VERSION ""

NS_ :

BS_:

BU_: HIB SaGE CBC DASM DIAGNOST EBCM ECM EPSB ESC ESL HALF HCP IC OCM ORC PTS RF_HUB SCCM

BO_ 1089 DG_RQ_GLOBAL_UDS: 8 DIAGNOST
 SG_ DG_RQ_GLOBAL_UDS : 7|64@0+ (1,0) [0|0] ""  SCCM,RF_HUB,PTS,ORC,OCM,IC,HCP,HALF,ESL,ESC,EPSB,ECM,EBCM,DASM,CBC

BO_ 501 DAS_A4: 8 DASM
 SG_ Sm_ICON_Dspl : 40|6@1+ (1,0) [0|0] ""  HIB,IC
 SG_ SetSpeed_MPH : 16|8@1+ (1,0) [0|250] "mph"  HIB,ORC,IC
 SG_ SetSpeed_KPH : 8|8@1+ (1,0) [0|250] "km/h"  HIB,IC,ECM
 SG_ RadarBlocked : 46|1@1+ (1,0) [0|0] ""  HIB,ORC,IC
 SG_ ObjIntrstDist : 56|8@1+ (1,0) [0|253] "m"  HIB,ORC
 SG_ NCConlyNA_DASMSts : 49|1@1+ (1,0) [0|0] ""  HIB,IC
 SG_ NCCNA_DASMSts : 53|1@1+ (1,0) [0|0] ""  HIB,IC
 SG_ HMI_Screens : 0|8@1+ (1,0) [0|254] "Text"  HIB,IC
 SG_ FCWonlyNA_DASMSts : 51|1@1+ (1,0) [0|0] ""  HIB,IC
 SG_ FCW_Error : 26|2@1+ (1,0) [0|0] ""  HIB,ORC,IC
 SG_ FCW_BrkOn : 29|1@1+ (1,0) [0|0] ""  HIB,ORC,CBC
 SG_ FCWBrakingOff : 47|1@1+ (1,0) [0|0] ""  HIB,IC
 SG_ CameraFailure : 55|1@1+ (1,0) [0|0] ""  HIB,IC
 SG_ CameraBlocked : 54|1@1+ (1,0) [0|0] ""  HIB,IC
 SG_ CIPV_Fused : 30|1@1+ (1,0) [0|0] ""  HIB,ORC
 SG_ ACConlyNA_DASMSts : 48|1@1+ (1,0) [0|0] ""  HIB,IC
 SG_ ACC_HMI_SCRN_REQ : 31|1@1+ (1,0) [0|0] ""  HIB,IC
 SG_ ACCOnOff : 36|3@1+ (1,0) [0|0] ""  HIB,ORC,IC
 SG_ ACCNA_DASMSts : 52|1@1+ (1,0) [0|0] ""  HIB,IC
 SG_ ACCFaulted : 50|1@1+ (1,0) [0|0] ""  HIB,ORC,IC

BO_ 1747 APPL_ECU_DASM: 8 DIAGNOST
 SG_ APPL_ECU_DASM : 7|64@0+ (1,0) [0|0] ""  DASM

BO_ 1754 APPL_ECU_EPS: 8 DIAGNOST
 SG_ APPL_ECU_EPS : 7|64@0+ (1,0) [0|0] ""  EPSB

BO_ 1764 APPL_ECU_HALF: 8 DIAGNOST
 SG_ APPL_ECU_HaLF : 7|64@0+ (1,0) [0|0] ""  HALF

BO_ 1762 APPL_ECU_PTS: 8 DIAGNOST
 SG_ APPL_ECU_PTS : 7|64@0+ (1,0) [0|0] ""  PTS

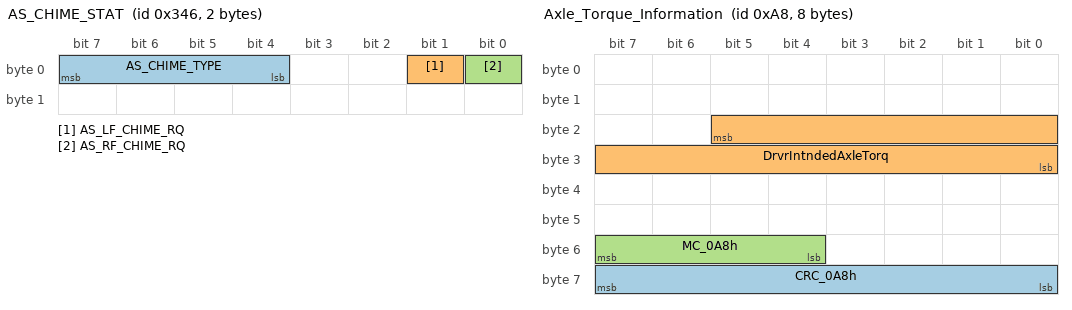
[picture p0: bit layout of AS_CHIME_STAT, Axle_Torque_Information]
BO_ 838 AS_CHIME_STAT: 2 DASM
 SG_ AS_CHIME_TYPE : 4|4@1+ (1,0) [0|0] ""  CBC,ORC
 SG_ AS_LF_CHIME_RQ : 1|1@1+ (1,0) [0|0] ""  CBC
 SG_ AS_RF_CHIME_RQ : 0|1@1+ (1,0) [0|0] ""  CBC

BO_ 168 Axle_Torque_Information: 8 ECM
 SG_ CRC_0A8h : 56|8@1+ (1,0) [0|0] ""  DASM,ESC
 SG_ DrvrIntndedAxleTorq : 21|14@0+ (1.5625,-4604.688) [-4604.688|20970.3125] "Nm"  DASM,ESC,ORC
 SG_ MC_0A8h : 52|4@1+ (1,0) [0|15] ""  DASM,ESC

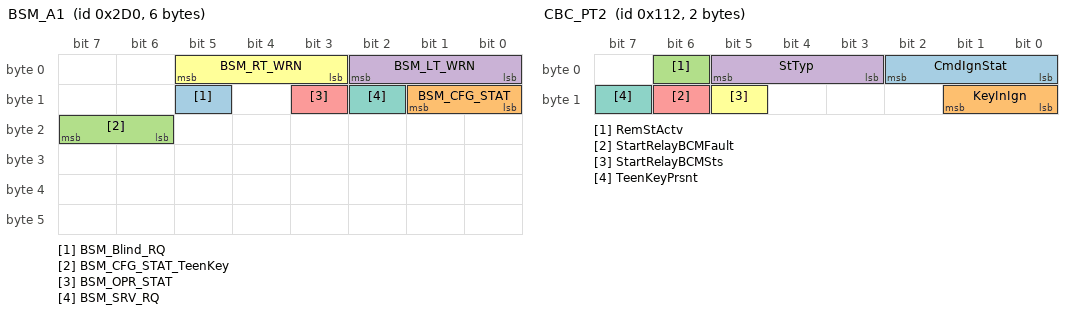
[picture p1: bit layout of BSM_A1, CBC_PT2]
BO_ 720 BSM_A1: 6 CBC
 SG_ BSM_Blind_RQ : 13|1@1+ (1,0) [0|0] ""  DASM,IC,ORC
 SG_ BSM_CFG_STAT : 8|2@1+ (1,0) [0|0] ""  DASM,IC,ORC
 SG_ BSM_CFG_STAT_TeenKey : 22|2@1+ (1,0) [0|0] ""  DASM
 SG_ BSM_LT_WRN : 0|3@1+ (1,0) [0|0] ""  DASM,ORC
 SG_ BSM_OPR_STAT : 11|1@1+ (1,0) [0|0] ""  DASM,IC
 SG_ BSM_RT_WRN : 3|3@1+ (1,0) [0|0] ""  DASM,ORC
 SG_ BSM_SRV_RQ : 10|1@1+ (1,0) [0|0] ""  DASM,IC,ORC

BO_ 820 CBC_PT1: 8 CBC
 SG_ AHB_ACT : 14|1@1+ (1,0) [0|0] ""  IC
 SG_ BRK_FLUID_LO : 62|1@1+ (1,0) [0|0] ""  ESC,IC
 SG_ DAY_LGT_MD : 40|1@1+ (1,0) [0|0] ""  IC,RF_HUB,SCCM
 SG_ DRV_AJAR : 17|1@1+ (1,0) [0|0] ""  DASM,ECM,ESC,HCP,IC,PTS,RF_HUB
 SG_ DR_LK_STAT : 5|2@1+ (1,0) [0|0] "" Vector__XXX
 SG_ FOB_SrchRq : 8|2@1+ (1,0) [0|0] ""  RF_HUB
 SG_ FT_FOG_RQ : 2|1@1+ (1,0) [0|0] ""  IC
 SG_ FT_WPR_NOT_PRK : 56|1@1+ (1,0) [0|0] ""  DASM,ECM,HALF
 SG_ HIBEAM_ON : 58|1@1+ (1,0) [0|0] ""  HALF,IC
 SG_ IGN_OFF_TIME_LNG : 27|12@0+ (1,0) [0|4080] "min"  DASM,ECM,ESC
 SG_ LOBEAM_ON : 57|1@1+ (1,0) [0|0] "" Vector__XXX
 SG_ L_R_AJAR : 19|1@1+ (1,0) [0|0] ""  IC,RF_HUB
 SG_ PANEL_INTS : 48|8@1+ (0.5,0) [0|100] "%"  IC,RF_HUB,SCCM
 SG_ PARK_LMP_ON : 16|1@1+ (1,0) [0|0] ""  IC
 SG_ PSG_AJAR : 18|1@1+ (1,0) [0|0] ""  ESC,IC,RF_HUB
 SG_ REV_GEAR : 4|1@1+ (1,0) [0|0] ""  EPSB,HALF,ORC
 SG_ R_FOG_RQ : 3|1@1+ (1,0) [0|0] ""  IC
 SG_ R_R_AJAR : 20|1@1+ (1,0) [0|0] ""  IC,RF_HUB
 SG_ SHIP_STAT : 28|2@1+ (1,0) [0|0] ""  DASM,HCP,IC,RF_HUB
 SG_ TLG_AJAR : 22|1@1+ (1,0) [0|0] ""  IC,PTS,RF_HUB
 SG_ TurnInd_LT_ON : 30|1@1+ (1,0) [0|0] ""  HALF,IC
 SG_ TurnInd_RT_ON : 31|1@1+ (1,0) [0|0] ""  HALF,IC
 SG_ WASH_FLUID_LO : 63|1@1+ (1,0) [0|0] ""  IC

BO_ 274 CBC_PT2: 2 CBC
 SG_ CmdIgnStat : 0|3@1+ (1,0) [0|0] ""  DASM,EBCM,ECM,EPSB,ESC,ESL,HALF,HCP,IC,OCM,ORC,PTS,RF_HUB,SCCM
 SG_ KeyInIgn : 8|2@1+ (1,0) [0|0] ""  ESL,HCP,IC,RF_HUB
 SG_ RemStActv : 6|1@1+ (1,0) [0|0] ""  ECM,HCP,IC,RF_HUB
 SG_ StTyp : 3|3@1+ (1,0) [0|0] ""  RF_HUB
 SG_ StartRelayBCMFault : 14|1@1+ (1,0) [0|0] ""  ECM
 SG_ StartRelayBCMSts : 13|1@1+ (1,0) [0|0] ""  ECM
 SG_ TeenKeyPrsnt : 15|1@1+ (1,0) [0|0] ""  DASM,ECM,IC,ORC,PTS

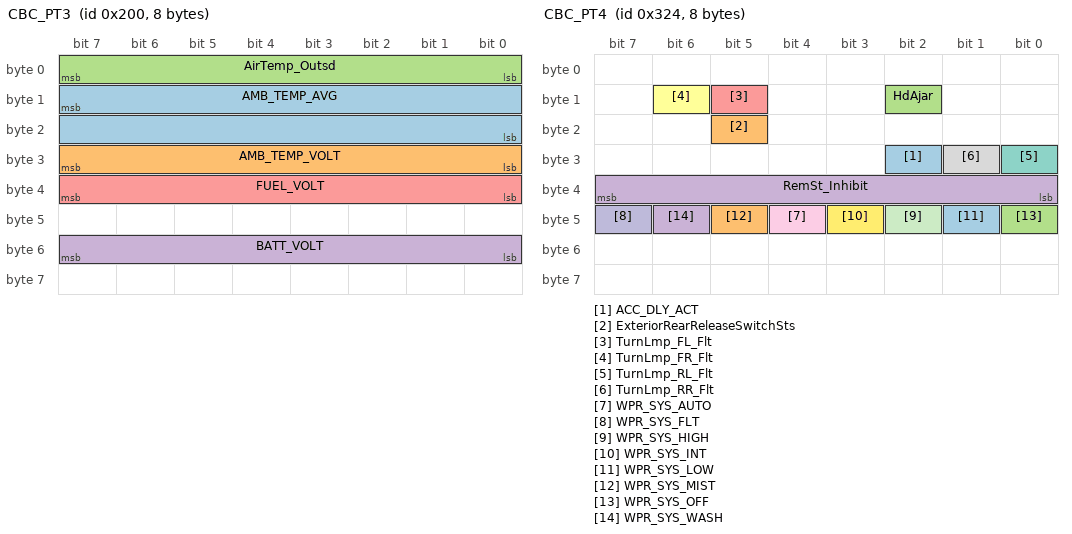
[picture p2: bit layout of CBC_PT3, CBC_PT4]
BO_ 512 CBC_PT3: 8 CBC
 SG_ AMB_TEMP_AVG : 15|16@0+ (0.01,-40) [-40|85] "°C"  DASM,ECM,EPSB,ESC,OCM,PTS,RF_HUB
 SG_ AMB_TEMP_VOLT : 24|8@1+ (0.019607843,0) [0|4.98] "Volts"  ECM,HCP
 SG_ AirTemp_Outsd : 0|8@1+ (0.5,-40) [-40|85] "°C"  DASM,ECM,EPSB,RF_HUB
 SG_ BATT_VOLT : 48|8@1+ (0.1,0) [5|18] "Volts"  DASM,EBCM,ECM,EPSB,ESC,ESL,HALF,HCP,IC,OCM,ORC,PTS,RF_HUB,SCCM
 SG_ FUEL_VOLT : 32|8@1+ (0.019607843,0) [0|4.98] "Volts"  ECM,IC

BO_ 804 CBC_PT4: 8 CBC
 SG_ ACC_DLY_ACT : 26|1@1+ (1,0) [0|0] ""  IC
 SG_ ExteriorRearReleaseSwitchSts : 21|1@1+ (1,0) [0|0] ""  RF_HUB
 SG_ HdAjar : 10|1@1+ (1,0) [0|0] ""  HCP,IC
 SG_ RemSt_Inhibit : 32|8@1+ (1,0) [0|0] ""  IC
 SG_ TurnLmp_FL_Flt : 13|1@1+ (1,0) [0|0] ""  HALF,IC
 SG_ TurnLmp_FR_Flt : 14|1@1+ (1,0) [0|0] ""  HALF,IC
 SG_ TurnLmp_RL_Flt : 24|1@1+ (1,0) [0|0] ""  HALF,IC
 SG_ TurnLmp_RR_Flt : 25|1@1+ (1,0) [0|0] ""  HALF,IC
 SG_ WPR_SYS_AUTO : 44|1@1+ (1,0) [0|0] ""  DASM,ESC,HALF
 SG_ WPR_SYS_FLT : 47|1@1+ (1,0) [0|0] ""  DASM,ESC,HALF
 SG_ WPR_SYS_HIGH : 42|1@1+ (1,0) [0|0] ""  DASM,ESC,HALF
 SG_ WPR_SYS_INT : 43|1@1+ (1,0) [0|0] ""  DASM,ESC,HALF
 SG_ WPR_SYS_LOW : 41|1@1+ (1,0) [0|0] ""  DASM,ESC,HALF
 SG_ WPR_SYS_MIST : 45|1@1+ (1,0) [0|0] ""  DASM,ESC,HALF
 SG_ WPR_SYS_OFF : 40|1@1+ (1,0) [0|0] ""  DASM,ESC,HALF
 SG_ WPR_SYS_WASH : 46|1@1+ (1,0) [0|0] ""  DASM,ESC,HALF

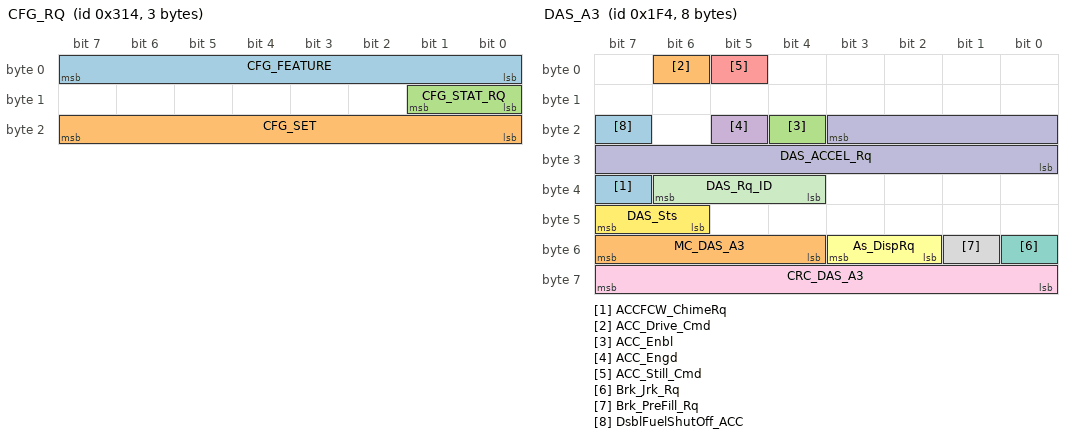
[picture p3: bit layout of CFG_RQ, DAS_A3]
BO_ 788 CFG_RQ: 3 CBC
 SG_ CFG_FEATURE : 0|8@1+ (1,0) [0|0] ""  DASM,ECM,ESC,HALF,IC,PTS,RF_HUB
 SG_ CFG_SET : 16|8@1+ (1,0) [0|255] ""  DASM,ECM,ESC,HALF,IC,PTS,RF_HUB
 SG_ CFG_STAT_RQ : 8|2@1+ (1,0) [0|0] ""  DASM,ECM,ESC,HALF,IC,PTS,RF_HUB

BO_ 500 DAS_A3: 8 DASM
 SG_ ACCFCW_ChimeRq : 39|1@1+ (1,0) [0|0] ""  HIB,IC
 SG_ ACC_Drive_Cmd : 6|1@1+ (1,0) [0|0] ""  HIB
 SG_ ACC_Enbl : 20|1@1+ (1,0) [0|0] ""  HIB,IC
 SG_ ACC_Engd : 21|1@1+ (1,0) [0|0] ""  HIB,IC
 SG_ ACC_Still_Cmd : 5|1@1+ (1,0) [0|0] ""  HIB,ORC
 SG_ As_DispRq : 50|2@1+ (1,0) [0|0] ""  HIB,HALF,IC,ORC
 SG_ Brk_Jrk_Rq : 48|1@1+ (1,0) [0|0] ""  HIB
 SG_ Brk_PreFill_Rq : 49|1@1+ (1,0) [0|0] ""  HIB
 SG_ CRC_DAS_A3 : 56|8@1+ (1,0) [0|0] ""  HIB
 SG_ DAS_ACCEL_Rq : 19|12@0+ (0.004885,-16) [-16|4] "m/s²"  HIB,ORC
 SG_ DAS_Rq_ID : 36|3@1+ (1,0) [0|0] ""  HIB
 SG_ DAS_Sts : 46|2@1+ (1,0) [0|0] ""  HIB
 SG_ DsblFuelShutOff_ACC : 23|1@1+ (1,0) [0|0] ""  HIB
 SG_ MC_DAS_A3 : 52|4@1+ (1,0) [0|15] ""  HIB,ECM

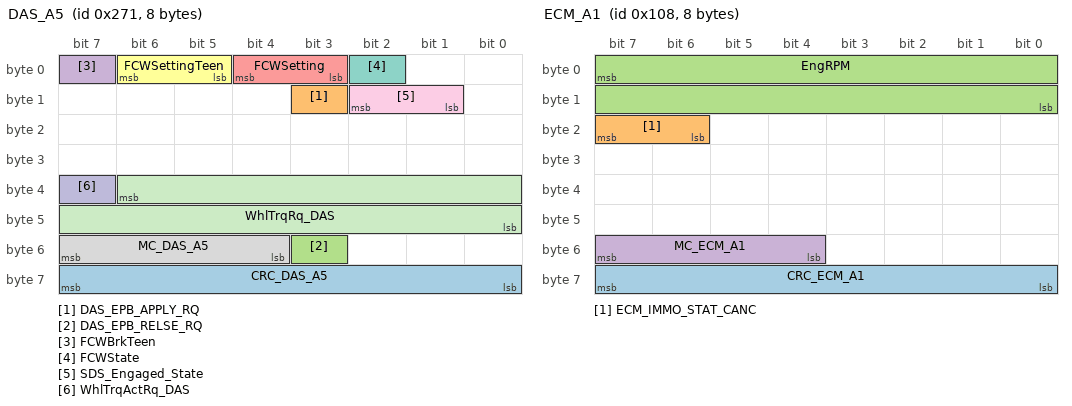
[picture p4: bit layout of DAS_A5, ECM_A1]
BO_ 625 DAS_A5: 8 DASM
 SG_ CRC_DAS_A5 : 56|8@1+ (1,0) [0|255] ""  HIB
 SG_ DAS_EPB_APPLY_RQ : 11|1@1+ (1,0) [0|0] ""  HIB
 SG_ DAS_EPB_RELSE_RQ : 51|1@1+ (1,0) [0|0] ""  HIB,HCP
 SG_ FCWBrkTeen : 7|1@1+ (1,0) [0|0] ""  HIB,CBC,ORC
 SG_ FCWSetting : 3|2@1+ (1,0) [0|0] ""  CBC,ORC
 SG_ FCWSettingTeen : 5|2@1+ (1,0) [0|0] ""  HIB,CBC,ORC
 SG_ FCWState : 2|1@1+ (1,0) [0|0] ""  HIB,CBC,IC,ORC
 SG_ MC_DAS_A5 : 52|4@1+ (1,0) [0|15] ""  HIB
 SG_ SDS_Engaged_State : 9|2@1+ (1,0) [0|0] ""  HIB,HCP
 SG_ WhlTrqActRq_DAS : 39|1@1+ (1,0) [0|0] ""  HIB
 SG_ WhlTrqRq_DAS : 38|15@0+ (1,-7767) [-7767|24999] "Nm"  HIB

BO_ 2015 DG_RQ_GLOBAL: 8 DIAGNOST
 SG_ DG_RQ_GLOBAL : 7|64@0+ (1,0) [0|0] ""  EBCM,ECM,ESC,HCP

BO_ 1875 D_RQ_DASM: 8 DIAGNOST
 SG_ D_RQ_DASM : 7|64@0+ (1,0) [0|0] ""  DASM

BO_ 1882 D_RQ_EPS: 8 DIAGNOST
 SG_ D_RQ_EPS : 7|64@0+ (1,0) [0|0] ""  EPSB

BO_ 1892 D_RQ_HaLF: 8 DIAGNOST
 SG_ D_RQ_HaLF : 7|64@0+ (1,0) [0|0] ""  HALF

BO_ 1890 D_RQ_PTS: 8 DIAGNOST
 SG_ D_RQ_PTS : 7|64@0+ (1,0) [0|0] ""  PTS

BO_ 1235 D_RS_DASM: 8 DASM
 SG_ D_RS_DASM : 7|64@0+ (1,0) [0|0] ""  DIAGNOST

BO_ 1242 D_RS_EPS: 8 EPSB
 SG_ D_RS_EPS : 7|64@0+ (1,0) [0|0] ""  DIAGNOST

BO_ 1252 D_RS_HaLF: 8 HALF
 SG_ D_RS_HaLF : 7|64@0+ (1,0) [0|0] ""  DIAGNOST

BO_ 1250 D_RS_PTS: 8 PTS
 SG_ D_RS_PTS : 7|64@0+ (1,0) [0|0] ""  DIAGNOST

BO_ 264 ECM_A1: 8 ECM
 SG_ CRC_ECM_A1 : 56|8@1+ (1,0) [0|0] ""  DASM,ESC,HALF
 SG_ ECM_IMMO_STAT_CANC : 22|2@1+ (1,0) [0|0] ""  CBC,HCP
 SG_ EngRPM : 7|16@0+ (1,0) [0|65534] "rpm"  CBC,DASM,EBCM,EPSB,ESC,HALF,IC,ORC,RF_HUB
 SG_ MC_ECM_A1 : 52|4@1+ (1,0) [0|15] ""  DASM,ESC,HALF

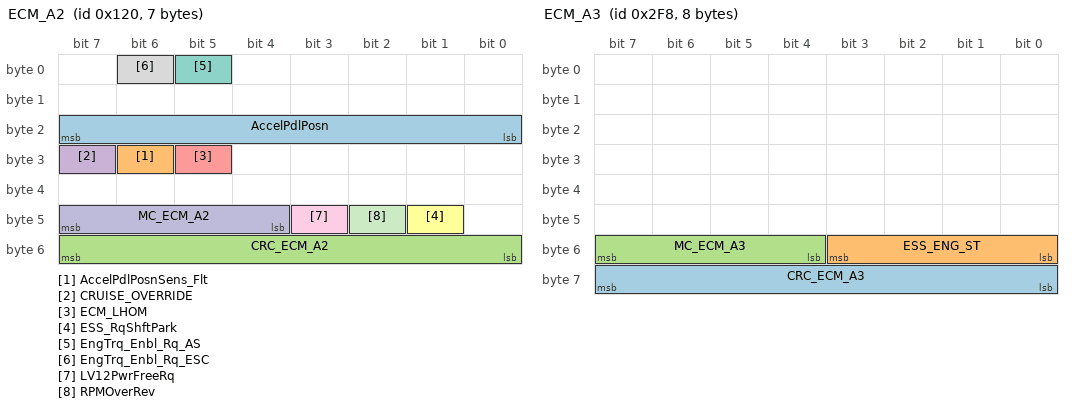
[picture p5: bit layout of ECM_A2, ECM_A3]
BO_ 288 ECM_A2: 7 ECM
 SG_ AccelPdlPosn : 16|8@1+ (0.4,0) [0|100] "%"  CBC,ESC,HALF
 SG_ AccelPdlPosnSens_Flt : 30|1@1+ (1,0) [0|0] ""  CBC,DASM,ESC,HALF
 SG_ CRC_ECM_A2 : 48|8@1+ (1,0) [0|0] ""  DASM,ESC,HALF
 SG_ CRUISE_OVERRIDE : 31|1@1+ (1,0) [0|0] ""  DASM,ESC,HCP,ORC
 SG_ ECM_LHOM : 29|1@1+ (1,0) [0|0] ""  DASM
 SG_ ESS_RqShftPark : 41|1@1+ (1,0) [0|0] ""  ORC
 SG_ EngTrq_Enbl_Rq_AS : 5|1@1+ (1,0) [0|0] ""  DASM,ESC
 SG_ EngTrq_Enbl_Rq_ESC : 6|1@1+ (1,0) [0|0] ""  DASM,ESC
 SG_ LV12PwrFreeRq : 43|1@1+ (1,0) [0|0] ""  DASM,ESC
 SG_ MC_ECM_A2 : 44|4@1+ (1,0) [0|15] ""  DASM,ESC,HALF
 SG_ RPMOverRev : 42|1@1+ (1,0) [0|0] "" Vector__XXX

BO_ 760 ECM_A3: 8 ECM
 SG_ CRC_ECM_A3 : 56|8@1+ (1,0) [0|0] ""  ESC,PTS
 SG_ ESS_ENG_ST : 48|4@1+ (1,0) [0|0] ""  CBC,EPSB,ESC,HALF,IC,ORC,PTS
 SG_ MC_ECM_A3 : 52|4@1+ (1,0) [0|15] ""  EPSB,ESC,PTS

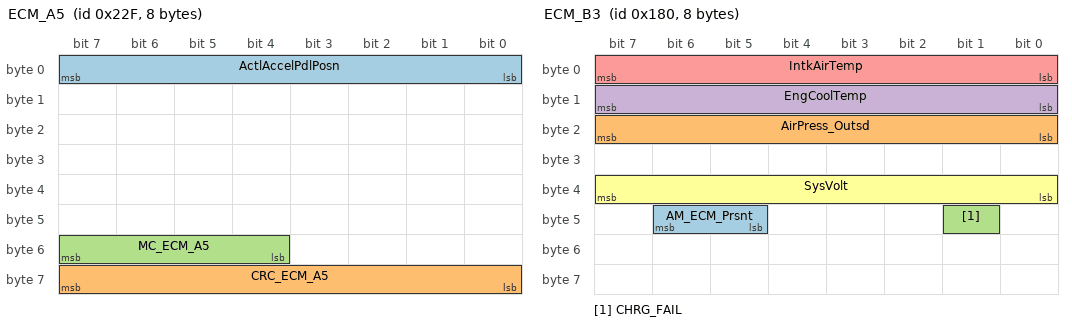
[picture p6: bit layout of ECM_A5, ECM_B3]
BO_ 559 ECM_A5: 8 ECM
 SG_ ActlAccelPdlPosn : 0|8@1+ (0.4,0) [0|100] "%"  DASM,ESC,HALF,ORC
 SG_ CRC_ECM_A5 : 56|8@1+ (1,0) [0|0] ""  DASM,ESC
 SG_ MC_ECM_A5 : 52|4@1+ (1,0) [0|15] ""  DASM,ESC

BO_ 384 ECM_B3: 8 ECM
 SG_ AM_ECM_Prsnt : 45|2@1+ (1,0) [0|0] ""  CBC
 SG_ AirPress_Outsd : 16|8@1+ (1,0) [0|254] "kPaA"  DASM,RF_HUB
 SG_ CHRG_FAIL : 41|1@1+ (1,0) [0|0] ""  IC
 SG_ EngCoolTemp : 8|8@1+ (1,-40) [-40|214] "°C"  CBC,ESC,IC
 SG_ IntkAirTemp : 0|8@1+ (1,-40) [-40|214] "°C"  ECM
 SG_ SysVolt : 32|8@1+ (0.0618,0) [0|15.6972] "Volts"  HCP

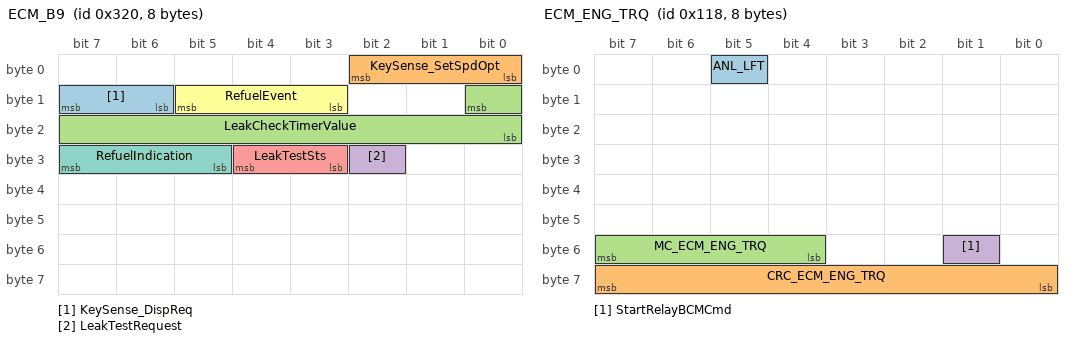
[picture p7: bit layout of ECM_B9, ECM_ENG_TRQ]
BO_ 800 ECM_B9: 8 ECM
 SG_ KeySense_DispReq : 14|2@1+ (1,0) [0|0] ""  IC
 SG_ KeySense_SetSpdOpt : 0|3@1+ (1,0) [0|0] ""  CBC,DASM,IC,ORC
 SG_ LeakCheckTimerValue : 8|9@0+ (1,0) [0|510] "min"  CBC
 SG_ LeakTestRequest : 26|1@1+ (1,0) [0|0] ""  CBC
 SG_ LeakTestSts : 27|2@1+ (1,0) [0|0] ""  CBC
 SG_ RefuelEvent : 11|3@1+ (1,0) [0|0] ""  CBC
 SG_ RefuelIndication : 29|3@1+ (1,0) [0|0] ""  IC

BO_ 280 ECM_ENG_TRQ: 8 ECM
 SG_ ANL_LFT : 5|1@1+ (1,0) [0|0] ""  CBC
 SG_ CRC_ECM_ENG_TRQ : 56|8@1+ (1,0) [0|0] ""  DASM,ESC
 SG_ MC_ECM_ENG_TRQ : 52|4@1+ (1,0) [0|15] ""  ESC
 SG_ StartRelayBCMCmd : 49|1@1+ (1,0) [0|0] ""  CBC

BO_ 1427 ECU_APPL_DASM: 8 DASM
 SG_ ECU_APPL_DASM : 7|64@0+ (1,0) [0|0] ""  DIAGNOST

BO_ 1434 ECU_APPL_EPS: 8 EPSB
 SG_ ECU_APPL_EPS : 7|64@0+ (1,0) [0|0] ""  DIAGNOST

BO_ 1444 ECU_APPL_HaLF: 8 HALF
 SG_ ECU_APPL_HaLF : 7|64@0+ (1,0) [0|0] ""  DIAGNOST

BO_ 1442 ECU_APPL_PTS: 8 PTS
 SG_ ECU_APPL_PTS : 7|64@0+ (1,0) [0|0] ""  DIAGNOST

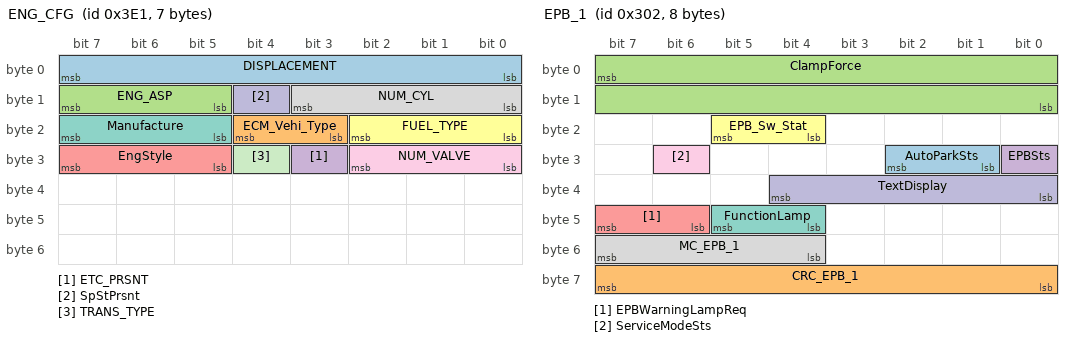
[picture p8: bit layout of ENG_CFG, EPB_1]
BO_ 993 ENG_CFG: 7 ECM
 SG_ DISPLACEMENT : 0|8@1+ (0.1,0) [0|25] "liters"  ESC,HALF,ORC
 SG_ ECM_Vehi_Type : 19|2@1+ (1,0) [0|0] "" Vector__XXX
 SG_ ENG_ASP : 13|3@1+ (1,0) [0|0] ""  ESC
 SG_ ETC_PRSNT : 27|1@1+ (1,0) [0|0] "" Vector__XXX
 SG_ EngStyle : 29|3@1+ (1,0) [0|0] ""  CBC,ESC
 SG_ FUEL_TYPE : 16|3@1+ (1,0) [0|0] ""  CBC,ESC,IC,ORC
 SG_ Manufacture : 21|3@1+ (1,0) [0|0] "" Vector__XXX
 SG_ NUM_CYL : 8|4@1+ (1,0) [0|14] "cylinders"  ESC,HALF,IC
 SG_ NUM_VALVE : 24|3@1+ (1,0) [0|6] "valve-per-cylinder" Vector__XXX
 SG_ SpStPrsnt : 12|1@1+ (1,0) [0|0] ""  CBC,EPSB,ESC,HALF,IC,PTS
 SG_ TRANS_TYPE : 28|1@1+ (1,0) [0|0] "" Vector__XXX

BO_ 770 EPB_1: 8 ESC
 SG_ AutoParkSts : 25|2@1+ (1,0) [0|0] ""  CBC
 SG_ CRC_EPB_1 : 56|8@1+ (1,0) [0|0] ""  DASM,ECM,IC
 SG_ ClampForce : 7|16@0+ (1,0) [0|65535] "N"  ORC
 SG_ EPBSts : 24|1@1+ (1,0) [0|0] ""  DASM,ECM,HCP
 SG_ EPBWarningLampReq : 46|2@1+ (1,0) [0|0] ""  IC,ORC
 SG_ EPB_Sw_Stat : 20|2@1+ (1,0) [0|0] ""  ORC
 SG_ FunctionLamp : 44|2@1+ (1,0) [0|0] ""  IC
 SG_ MC_EPB_1 : 52|4@1+ (1,0) [0|15] ""  DASM,ECM,IC
 SG_ ServiceModeSts : 30|1@1+ (1,0) [0|0] ""  CBC
 SG_ TextDisplay : 32|5@1+ (1,0) [0|0] ""  CBC,IC

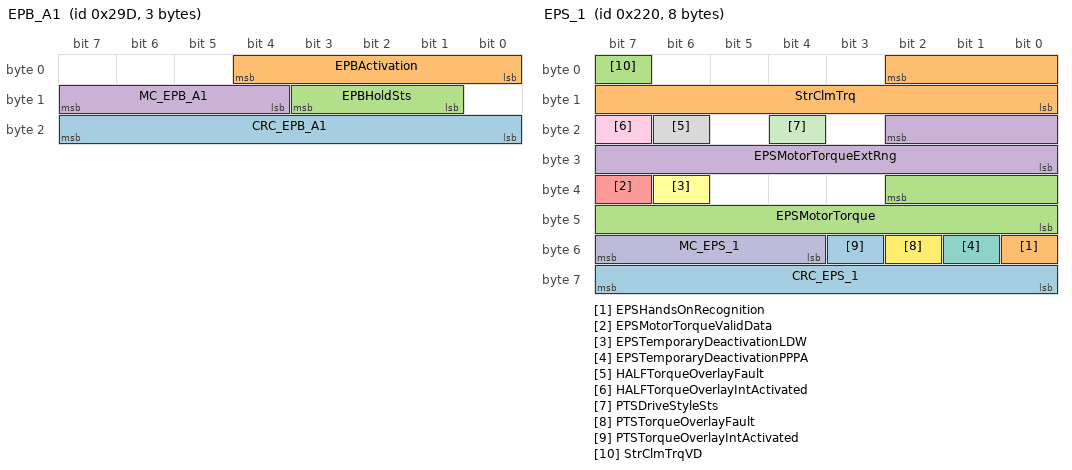
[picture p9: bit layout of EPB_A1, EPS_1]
BO_ 669 EPB_A1: 3 ESC
 SG_ CRC_EPB_A1 : 16|8@1+ (1,0) [0|0] ""  DASM,ECM,HCP,PTS
 SG_ EPBActivation : 0|5@1+ (1,0) [0|0] "" Vector__XXX
 SG_ EPBHoldSts : 9|3@1+ (1,0) [0|0] ""  CBC,DASM,ECM,HCP,ORC,PTS
 SG_ MC_EPB_A1 : 12|4@1+ (1,0) [0|15] ""  DASM,ECM,HCP,PTS

BO_ 544 EPS_1: 8 EPSB
 SG_ CRC_EPS_1 : 56|8@1+ (1,0) [0|0] ""  ECM,ESC,HALF,PTS
 SG_ EPSHandsOnRecognition : 48|1@1+ (1,0) [0|0] ""  PTS
 SG_ EPSMotorTorque : 34|11@0+ (0.001953125,-2) [-2|1.998047] "Nm"  HALF,ORC
 SG_ EPSMotorTorqueExtRng : 18|11@0+ (0.00488281,-5) [-5|4.99022926] "Nm" Vector__XXX
 SG_ EPSMotorTorqueValidData : 39|1@1+ (1,0) [0|0] ""  HALF
 SG_ EPSTemporaryDeactivationLDW : 38|1@1+ (1,0) [0|0] ""  HALF
 SG_ EPSTemporaryDeactivationPPPA : 49|1@1+ (1,0) [0|0] ""  PTS
 SG_ HALFTorqueOverlayFault : 22|1@1+ (1,0) [0|0] ""  HALF
 SG_ HALFTorqueOverlayIntActivated : 23|1@1+ (1,0) [0|0] ""  HALF,ORC
 SG_ MC_EPS_1 : 52|4@1+ (1,0) [0|15] ""  ECM,ESC,HALF,PTS
 SG_ PTSDriveStyleSts : 20|1@1+ (1,0) [0|0] ""  PTS
 SG_ PTSTorqueOverlayFault : 50|1@1+ (1,0) [0|0] ""  PTS
 SG_ PTSTorqueOverlayIntActivated : 51|1@1+ (1,0) [0|0] ""  PTS
 SG_ StrClmTrq : 2|11@0+ (0.0078125,-8) [-8|7.98] "Nm"  ECM,HALF,ORC,PTS
 SG_ StrClmTrqVD : 7|1@1+ (1,0) [0|0] ""  ECM,HALF,PTS

CM_ "Excel Convert to DBC - Written by Vector CANtech, Inc. 2016";
CM_ SG_ 1089 DG_RQ_GLOBAL_UDS "Diagnostic-Request";
CM_ SG_ 501 Sm_ICON_Dspl "Small graphic display";
CM_ SG_ 501 SetSpeed_MPH "Desired set speed in miles per hour";
CM_ SG_ 501 SetSpeed_KPH "Desired set speed in kilometers per hour";
CM_ SG_ 501 RadarBlocked "ACC FCW not available: clean radar snsr; True = [1]";
CM_ SG_ 501 ObjIntrstDist "Object of interest distance";
CM_ SG_ 501 NCConlyNA_DASMSts "NCC only not available: vehicle system error; True = [1]";
CM_ SG_ 501 NCCNA_DASMSts "NCC/FCW not avail: vehicle system error; True = [1]";
CM_ SG_ 501 HMI_Screens "HMI screens";
CM_ SG_ 501 FCWonlyNA_DASMSts "FCW only not available: vehicle system error; True = [1]";
CM_ SG_ 501 FCW_Error "Forward collision warning error";
CM_ SG_ 501 FCW_BrkOn "FCW braking is on; true = [1]";
CM_ SG_ 501 FCWBrakingOff "FCW autobraking disabled; True = [1]";
CM_ SG_ 501 CameraFailure "ACC/FCW limited functionality: camera failure; True = [1]";
CM_ SG_ 501 CameraBlocked "ACC FCW limited functionality: camera blocked; True = [1]";
CM_ SG_ 501 CIPV_Fused "Closest in-path vehicle is fused; True = [1]";
CM_ SG_ 501 ACConlyNA_DASMSts "ACC only not available: vehicle system error; True = [1]";
CM_ SG_ 501 ACC_HMI_SCRN_REQ "ACC HMI Screen request. Display HMI screen when [1]";
CM_ SG_ 501 ACCOnOff "ACC on off status";
CM_ SG_ 501 ACCNA_DASMSts "ACC/FCW not avail: vehicle system error; True = [1]";
CM_ SG_ 501 ACCFaulted "ACC faulted; True = [1]";
CM_ SG_ 1747 APPL_ECU_DASM "External Application to ECU";
CM_ SG_ 1754 APPL_ECU_EPS "External Application to ECU";
CM_ SG_ 1764 APPL_ECU_HaLF "External Application to ECU";
CM_ SG_ 1762 APPL_ECU_PTS "External Application to ECU";
CM_ SG_ 838 AS_CHIME_TYPE "AS chime type";
CM_ SG_ 838 AS_LF_CHIME_RQ "AS left front chime on request; True = [1]";
CM_ SG_ 838 AS_RF_CHIME_RQ "AS right front chime on request; True = [1]";
CM_ SG_ 168 CRC_0A8h "CRC-Checksum Byte 1 - 7 according to SAE J1850";
CM_ SG_ 168 DrvrIntndedAxleTorq "Driver Intended Axle Torque";
CM_ SG_ 168 MC_0A8h "Message counter   0A8h";
CM_ SG_ 720 BSM_Blind_RQ "Sensor blinded request from BSM; 1= sensor blocked request";
CM_ SG_ 720 BSM_CFG_STAT "BSM configuration status";
CM_ SG_ 720 BSM_CFG_STAT_TeenKey "BSM configuration status for teen key";
CM_ SG_ 720 BSM_LT_WRN "Blind spot detection left side warning";
CM_ SG_ 720 BSM_OPR_STAT "BSM operation status; 1= operational failure";
CM_ SG_ 720 BSM_RT_WRN "Blind spot detection Right side warning";
CM_ SG_ 720 BSM_SRV_RQ "BSM service warning request; 1= service request";
CM_ SG_ 820 AHB_ACT "Automatic high beam active";
CM_ SG_ 820 BRK_FLUID_LO "Low brake fluid warning; low = [1]";
CM_ SG_ 820 DAY_LGT_MD "Day light brightness mode; Night=[0], Day=[1]";
CM_ SG_ 820 DRV_AJAR "Driver door ajar (1 = Door Ajar)";
CM_ SG_ 820 DR_LK_STAT "Door lock status";
CM_ SG_ 820 FOB_SrchRq "FOB search request";
CM_ SG_ 820 FT_FOG_RQ "Front fog request; off=[0], on=[1]";
CM_ SG_ 820 FT_WPR_NOT_PRK "Front wiper outside park position";
CM_ SG_ 820 HIBEAM_ON "High beam is on; off=[0], on=[1]";
CM_ SG_ 820 IGN_OFF_TIME_LNG "Time since last ignition on (long)";
CM_ SG_ 820 LOBEAM_ON "Low beam is on; off=[0], on=[1]";
CM_ SG_ 820 L_R_AJAR "Left rear door ajar";
CM_ SG_ 820 PANEL_INTS "Panel-/display intensity";
CM_ SG_ 820 PARK_LMP_ON "Parklamps are on; off=[0], on=[1]";
CM_ SG_ 820 PSG_AJAR "Passenger door ajar";
CM_ SG_ 820 REV_GEAR "Reverse Gear (manual trans)";
CM_ SG_ 820 R_FOG_RQ "Rear fog request; [0] = off, [1] = on";
CM_ SG_ 820 R_R_AJAR "Right rear door ajar";
CM_ SG_ 820 SHIP_STAT "Shipping status";
CM_ SG_ 820 TLG_AJAR "Trunk/Liftgate ajar";
CM_ SG_ 820 TurnInd_LT_ON "Turn indication left is on";
CM_ SG_ 820 TurnInd_RT_ON "Turn indication right is on";
CM_ SG_ 820 WASH_FLUID_LO "Low washer fluid warning (1=Fluid is low)";
CM_ SG_ 274 CmdIgnStat "Commanded ignition switch status";
CM_ SG_ 274 KeyInIgn "Key in ignition status";
CM_ SG_ 274 RemStActv "Ignition run active for remote start (0=not active, 1=active)";
CM_ SG_ 274 StTyp "Type of start being requested";
CM_ SG_ 274 StartRelayBCMFault "CBC starter relay fault detected";
CM_ SG_ 274 StartRelayBCMSts "CBC starter relay status; [1] = ON";
CM_ SG_ 274 TeenKeyPrsnt "Teen key present; Present = [1]";
CM_ SG_ 512 AMB_TEMP_AVG "Averaged ambient temperature";
CM_ SG_ 512 AMB_TEMP_VOLT "Ambient Temp Sensor A/D Voltage";
CM_ SG_ 512 AirTemp_Outsd "Outside air temperature";
CM_ SG_ 512 BATT_VOLT "System voltage";
CM_ SG_ 512 FUEL_VOLT "Fuel level A/D Voltage (Single tank OR Primary on Saddle/Dual Tank)";
CM_ SG_ 804 ACC_DLY_ACT "Accessory Delay Active";
CM_ SG_ 804 ExteriorRearReleaseSwitchSts "Exterior rear release switch status";
CM_ SG_ 804 HdAjar "Hood latch ajar, left or single (1=ajar)";
CM_ SG_ 804 RemSt_Inhibit "Remote start inhibit";
CM_ SG_ 804 TurnLmp_FL_Flt "Turn indication lamp front left fault";
CM_ SG_ 804 TurnLmp_FR_Flt "Turn indication lamp front right fault";
CM_ SG_ 804 TurnLmp_RL_Flt "Turn indication lamp rear left fault";
CM_ SG_ 804 TurnLmp_RR_Flt "Turn indication lamp rear right fault";
CM_ SG_ 804 WPR_SYS_AUTO "Wiper system auto; [1] = Auto wipers equipped";
CM_ SG_ 804 WPR_SYS_FLT "Wiper system fault present; [1] = fault present";
CM_ SG_ 804 WPR_SYS_HIGH "Wiper system high; [1] = switch is HIGH";
CM_ SG_ 804 WPR_SYS_INT "Wiper system intermittent; [1] = switch is INT";
CM_ SG_ 804 WPR_SYS_LOW "Wiper system low; [1] = switch is LOW";
CM_ SG_ 804 WPR_SYS_MIST "Wiper system mist; [1] = mist request";
CM_ SG_ 804 WPR_SYS_OFF "Wiper system off; [1] = switch is OFF";
CM_ SG_ 804 WPR_SYS_WASH "Wiper system wash; [1] = wash request";
CM_ SG_ 788 CFG_FEATURE "Configurable feature";
CM_ SG_ 788 CFG_SET "Specific setting or value (see reference)";
CM_ SG_ 788 CFG_STAT_RQ "Configurable feature status request";
CM_ SG_ 500 ACCFCW_ChimeRq "ACC FCW chime request active; Active = [1]";
CM_ SG_ 500 ACC_Drive_Cmd "ACC drive off commanded; True = [1]";
CM_ SG_ 500 ACC_Enbl "ACC cruise control enabled; True = [1]";
CM_ SG_ 500 ACC_Engd "ACC engaged; True = [1]";
CM_ SG_ 500 ACC_Still_Cmd "ACC stop commanded; True = [1]";
CM_ SG_ 500 As_DispRq "Assistance system display request (priority)";
CM_ SG_ 500 Brk_Jrk_Rq "Brake jerk request; True = [1]";
CM_ SG_ 500 Brk_PreFill_Rq "Brakes pre-fill request; True = [1]";
CM_ SG_ 500 CRC_DAS_A3 "CRC-checksum byte 1 to 7 according to SAE J1850";
CM_ SG_ 500 DAS_ACCEL_Rq "DASM acceleration request";
CM_ SG_ 500 DAS_Rq_ID "DAS request ID";
CM_ SG_ 500 DAS_Sts "DASM fault status";
CM_ SG_ 500 DsblFuelShutOff_ACC "Disable fuel shutoff; True = [1]";
CM_ SG_ 500 MC_DAS_A3 "Message counter";
CM_ SG_ 625 CRC_DAS_A5 "CRC-checksum byte 1 to 7 according to SAE J1850";
CM_ SG_ 625 DAS_EPB_APPLY_RQ "DAS request to apply EPB";
CM_ SG_ 625 DAS_EPB_RELSE_RQ "DAS request to apply EPB";
CM_ SG_ 625 FCWBrkTeen "FCW braking is on for teen key; true = [1]";
CM_ SG_ 625 FCWSetting "Forward collision warning sensitivity setting";
CM_ SG_ 625 FCWSettingTeen "Forward collision warning sensitivity setting teen key";
CM_ SG_ 625 FCWState "FCW system operating state; On = [1]";
CM_ SG_ 625 MC_DAS_A5 "Message counter";
CM_ SG_ 625 SDS_Engaged_State "SDS Engaged Status";
CM_ SG_ 625 WhlTrqActRq_DAS "Wheel torque request active; True = [1]";
CM_ SG_ 625 WhlTrqRq_DAS "Requested wheel torque";
CM_ SG_ 2015 DG_RQ_GLOBAL "Diagnostic-Request";
CM_ SG_ 1875 D_RQ_DASM "Diagnostic-Request";
CM_ SG_ 1882 D_RQ_EPS "Diagnostic-Request";
CM_ SG_ 1892 D_RQ_HaLF "Diagnostic-Request";
CM_ SG_ 1890 D_RQ_PTS "Diagnostic-Request";
CM_ SG_ 1235 D_RS_DASM "Diagnostic-Response";
CM_ SG_ 1242 D_RS_EPS "Diagnostic-Response";
CM_ SG_ 1252 D_RS_HaLF "Diagnostic-Response";
CM_ SG_ 1250 D_RS_PTS "Diagnostic-Response";
CM_ SG_ 264 CRC_ECM_A1 "CRC-checksum byte 1 to 7 according to SAE J1850";
CM_ SG_ 264 ECM_IMMO_STAT_CANC "ECM immobilizer status";
CM_ SG_ 264 EngRPM "Engine revolutions per minute";
CM_ SG_ 264 MC_ECM_A1 "Message counter";
CM_ SG_ 288 AccelPdlPosn "Throttle Pedal Position (Calculated)";
CM_ SG_ 288 AccelPdlPosnSens_Flt "Accelerator pedal position sensor fault";
CM_ SG_ 288 CRC_ECM_A2 "CRC-checksum byte 1 to 6 according to SAE J1850";
CM_ SG_ 288 CRUISE_OVERRIDE "Driver is over-riding cruise set speed";
CM_ SG_ 288 ECM_LHOM "Engine in limp home mode";
CM_ SG_ 288 ESS_RqShftPark "ESS Request shift to Park.  1 = True, 0 = False";
CM_ SG_ 288 EngTrq_Enbl_Rq_AS "Allow LCM torque requests";
CM_ SG_ 288 EngTrq_Enbl_Rq_ESC "Allow ESC torque request";
CM_ SG_ 288 LV12PwrFreeRq "Level 1 or 2 power free request - engine controller has depowered the throttle body";
CM_ SG_ 288 MC_ECM_A2 "Message counter";
CM_ SG_ 288 RPMOverRev "RPM Overrev condition has occurred";
CM_ SG_ 760 CRC_ECM_A3 "CRC-checksum byte 1 to 7 according to SAE J1850";
CM_ SG_ 760 ESS_ENG_ST "ESS Engine State";
CM_ SG_ 760 MC_ECM_A3 "Message counter";
CM_ SG_ 559 ActlAccelPdlPosn "Throttle Pedal Position (actual)";
CM_ SG_ 559 CRC_ECM_A5 "CRC-checksum byte 1 to 7 according to SAE J1850";
CM_ SG_ 559 MC_ECM_A5 "Message counter";
CM_ SG_ 384 AM_ECM_Prsnt "Aftermarket ECM present";
CM_ SG_ 384 AirPress_Outsd "Ambient air pressure (barometric pressure)";
CM_ SG_ 384 CHRG_FAIL "Charging system Failure (battery indicator request)";
CM_ SG_ 384 EngCoolTemp "Engine coolant temperature";
CM_ SG_ 384 IntkAirTemp "Engine Intake Air Temperature";
CM_ SG_ 384 SysVolt "Engine system voltage";
CM_ SG_ 800 KeySense_DispReq "Key sense cluster EVIC request";
CM_ SG_ 800 KeySense_SetSpdOpt "Key sense max speed option for ECM speed limiting";
CM_ SG_ 800 LeakCheckTimerValue "Requested leak test timer value";
CM_ SG_ 800 LeakTestRequest "Leak test is requested after powerdown; No request = [0], Leak test requested = [1]";
CM_ SG_ 800 LeakTestSts "Status of leak test";
CM_ SG_ 800 RefuelEvent "Status of refuel event";
CM_ SG_ 800 RefuelIndication "Indication to the driver about the status of the refuel system";
CM_ SG_ 280 ANL_LFT "Starter motor running (Cranking)";
CM_ SG_ 280 CRC_ECM_ENG_TRQ "CRC-checksum byte 1 to 7 according to SAE J1850";
CM_ SG_ 280 MC_ECM_ENG_TRQ "Message counter";
CM_ SG_ 280 StartRelayBCMCmd "Engine restart request for StopStart function";
CM_ SG_ 1427 ECU_APPL_DASM "ECU to External Application";
CM_ SG_ 1434 ECU_APPL_EPS "ECU to External Application";
CM_ SG_ 1444 ECU_APPL_HaLF "ECU to External Application";
CM_ SG_ 1442 ECU_APPL_PTS "ECU to External Application";
CM_ SG_ 993 DISPLACEMENT "Engine displacement";
CM_ SG_ 993 ECM_Vehi_Type "Engine vehicle type";
CM_ SG_ 993 ENG_ASP "Engine aspiration method";
CM_ SG_ 993 ETC_PRSNT "Electronic throttle control";
CM_ SG_ 993 EngStyle "Engine output version";
CM_ SG_ 993 FUEL_TYPE "Fuel type";
CM_ SG_ 993 Manufacture "Engine manufacture";
CM_ SG_ 993 NUM_CYL "Number of engine cylinders";
CM_ SG_ 993 NUM_VALVE "Number of valves per cylinder";
CM_ SG_ 993 SpStPrsnt "Stop start feature present";
CM_ SG_ 993 TRANS_TYPE "Transmission type; [0] = manual, [1] = automatic";
CM_ SG_ 770 AutoParkSts "EPB auto park brake function available status";
CM_ SG_ 770 CRC_EPB_1 "CRC-checksum byte 1 to 7 according to SAE J1850";
CM_ SG_ 770 ClampForce "EPB clamp force";
CM_ SG_ 770 EPBSts "EPB status; Enable = [1]";
CM_ SG_ 770 EPBWarningLampReq "EPB warning (fault) lamp active request";
CM_ SG_ 770 EPB_Sw_Stat "EPB switch state";
CM_ SG_ 770 FunctionLamp "EPB function lamp active request";
CM_ SG_ 770 MC_EPB_1 "Message counter";
CM_ SG_ 770 ServiceModeSts "EPB service mode; Service mode = [1]";
CM_ SG_ 770 TextDisplay "Text message display request";
CM_ SG_ 669 CRC_EPB_A1 "CRC-checksum byte 1 to 2 according to SAE J1850";
CM_ SG_ 669 EPBActivation "EPB activation reason";
CM_ SG_ 669 EPBHoldSts "EPB hold status";
CM_ SG_ 669 MC_EPB_A1 "Message counter";
CM_ SG_ 544 CRC_EPS_1 "CRC-checksum byte 1 to 7 according to SAE J1850";
CM_ SG_ 544 EPSHandsOnRecognition "Driver interference during the semiautomatic parking maneuver; True = [1]";
CM_ SG_ 544 EPSMotorTorque "EPS motor torque";
CM_ SG_ 544 EPSMotorTorqueExtRng "EPS motor torque extended range (+/- 5Nm)";
CM_ SG_ 544 EPSMotorTorqueValidData "Motor torque: valid data [1]";
CM_ SG_ 544 EPSTemporaryDeactivationLDW "Temporary deactivation of the EPS LDW torque overlay function";
CM_ SG_ 544 EPSTemporaryDeactivationPPPA "Temporary deactivation of the EPS PPPA torque overlay function; True = [1]";
CM_ SG_ 544 HALFTorqueOverlayFault "Fault of the HALF torque overlay interface";
CM_ SG_ 544 HALFTorqueOverlayIntActivated "Torque overlay interface has been successfully activated; True = [1]";
CM_ SG_ 544 MC_EPS_1 "Message counter";
CM_ SG_ 544 PTSDriveStyleSts "PTS_TOC Actived = [1]";
CM_ SG_ 544 PTSTorqueOverlayFault "Fault of the PTS torque overlay interface; True = [1]";
CM_ SG_ 544 PTSTorqueOverlayIntActivated "Torque overlay interface has been successfully activated; True = [1]";
CM_ SG_ 544 StrClmTrq "Steering column torque; counterclockwise positive [Nm]";
CM_ SG_ 544 StrClmTrqVD "Steering column torque: valid data [1]";
BA_DEF_ BO_  "App-Botschaft" ENUM  "nein","ja";
BA_DEF_ BO_  "CanMsgMinLen" INT 0 8;
BA_DEF_ BO_  "DiagRequest" ENUM  "nein","ja";
BA_DEF_ BO_  "DiagResponse" ENUM  "nein","ja";
BA_DEF_ BO_  "DiagState" ENUM  "nein","ja";
BA_DEF_ BO_  "GenMsgCycleTime" INT 0 65535;
BA_DEF_ BO_  "GenMsgCycleTimeActive" INT 0 65535;
BA_DEF_ BO_  "GenMsgDelayTime" INT 0 65535;
BA_DEF_ BO_  "GenMsgNrOfRepetitions" INT 0 65535;
BA_DEF_ BO_  "GenMsgSendType" ENUM  "cyclicX","spontanX","cyclicIfActiveX","spontanWithDelay","cyclicAndSpontanX","cyclicAndSpontanWithDelay","spontanWithRepitition","cyclicIfActiveAndSpontanWD","cyclicIfActiveFast","cyclicWithRepeatOnDemand","none";
BA_DEF_ BO_  "GenMsgStartDelayTime" INT 0 65535;
BA_DEF_ BO_  "GenMsgStartValue" STRING ;
BA_DEF_ BO_  "NWM-Botschaft" ENUM  "nein","ja";
BA_DEF_ BO_  "TpTxIndex" INT 0 99;
BA_DEF_  "Baudrate" INT 0 1000000;
BA_DEF_  "Manufacturer" ENUM  "DBAG","VAG","BMWAG","PAG","GM";
BA_DEF_  "NBTMax" INT 0 255;
BA_DEF_  "NBTMin" INT 0 255;
BA_DEF_  "NmMessageCount" INT 0 64;
BA_DEF_  "NWM-Basisadresse" HEX 0 536870911;
BA_DEF_  "NWM-Typ" ENUM  "zentral (MB-W210)","dezentral (MB-OSAN)","keines","VAG-OSEK","BMW-OSEK","PAG-OSEK","DBAG-OSEK";
BA_DEF_  "SamplePointMax" FLOAT 0 100;
BA_DEF_  "SamplePointMin" FLOAT 0 100;
BA_DEF_  "Version" HEX 0 4080;
BA_DEF_  "VersionWeek" INT 0 53;
BA_DEF_  "VersionYear" INT 0 99;
BA_DEF_ BU_  "NWM-Knoten" ENUM  "nein","ja";
BA_DEF_ BU_  "NWM-Stationsadresse" HEX 0 63;
BA_DEF_ BU_  "TpNodeBaseAddress" HEX 0 65535;
BA_DEF_ BU_  "TpOwnSystemEcuNumber" HEX 0 255;
BA_DEF_ SG_  "FlexKomComment" STRING ;
BA_DEF_ SG_  "FlexKomIsMotorola" ENUM  "nein","ja";
BA_DEF_ SG_  "FlexKomSID" INT 0 2147483647;
BA_DEF_ SG_  "FlexKomSigLaenge" INT 0 64;
BA_DEF_ SG_  "FlexKomSigName" STRING ;
BA_DEF_ SG_  "FlexKomSigStartPos" INT 0 63;
BA_DEF_ SG_  "FlexKomSigStartValue" STRING ;
BA_DEF_ SG_  "GenSigCycleTime" INT 0 65535;
BA_DEF_ SG_  "GenSigCycleTimeActive" INT 0 65535;
BA_DEF_ SG_  "GenSigSendType" ENUM  "cyclicX","spontanX","cyclicIfActiveX","spontanWithDelay","cyclicAndSpontanX","cyclicAndSpontanWithDelay","spontanWithRepitition","cyclicIfActiveAndSpontanWD","cyclicIfActiveFast","cyclicWithRepeatOnDemand","none";
BA_DEF_ SG_  "GenSigSNA" STRING ;
BA_DEF_ SG_  "GenSigStartValue" HEX 0 2147483648;
BA_DEF_ SG_  "GenSigTimeout_CBC" INT 0 65535;
BA_DEF_ SG_  "GenSigTimeout_EPS" INT 0 65535;
BA_DEF_ SG_  "GenSigTimeout_ESC" INT 0 65535;
BA_DEF_ SG_  "GenSigTimeout_ESL" INT 0 65535;
BA_DEF_ SG_  "GenSigTimeout_RHSC2" INT 0 65535;
BA_DEF_ SG_  "GenSigTimeout_ETM" INT 0 65535;
BA_DEF_ SG_  "GenSigTimeout_HaLF" INT 0 65535;
BA_DEF_ SG_  "GenSigTimeout_IC" INT 0 65535;
BA_DEF_ SG_  "GenSigTimeout_OCM" INT 0 65535;
BA_DEF_ SG_  "GenSigTimeout_ORC" INT 0 65535;
BA_DEF_ SG_  "GenSigTimeout_PTS" INT 0 65535;
BA_DEF_ SG_  "GenSigTimeout_RF_HUB" INT 0 65535;
BA_DEF_ SG_  "GenSigTimeout_SCCM" INT 0 65535;
BA_DEF_ SG_  "RID" STRING ;
BA_DEF_DEF_  "App-Botschaft" "nein";
BA_DEF_DEF_  "CanMsgMinLen" 0;
BA_DEF_DEF_  "DiagRequest" "nein";
BA_DEF_DEF_  "DiagResponse" "nein";
BA_DEF_DEF_  "DiagState" "nein";
BA_DEF_DEF_  "GenMsgCycleTime" 0;
BA_DEF_DEF_  "GenMsgCycleTimeActive" 0;
BA_DEF_DEF_  "GenMsgDelayTime" 0;
BA_DEF_DEF_  "GenMsgNrOfRepetitions" 0;
BA_DEF_DEF_  "GenMsgSendType" "cyclicX";
BA_DEF_DEF_  "GenMsgStartDelayTime" 0;
BA_DEF_DEF_  "GenMsgStartValue" "";
BA_DEF_DEF_  "NWM-Botschaft" "nein";
BA_DEF_DEF_  "TpTxIndex" 0;
BA_DEF_DEF_  "Baudrate" 500000;
BA_DEF_DEF_  "Manufacturer" "DBAG";
BA_DEF_DEF_  "NBTMax" 20;
BA_DEF_DEF_  "NBTMin" 10;
BA_DEF_DEF_  "NmMessageCount" 64;
BA_DEF_DEF_  "NWM-Basisadresse" 1024;
BA_DEF_DEF_  "NWM-Typ" "DBAG-OSEK";
BA_DEF_DEF_  "SamplePointMax" 81.25;
BA_DEF_DEF_  "SamplePointMin" 75;
BA_DEF_DEF_  "Version" 4;
BA_DEF_DEF_  "VersionWeek" 26;
BA_DEF_DEF_  "VersionYear" 18;
BA_DEF_DEF_  "NWM-Knoten" "nein";
BA_DEF_DEF_  "NWM-Stationsadresse" 0;
BA_DEF_DEF_  "TpNodeBaseAddress" 0;
BA_DEF_DEF_  "TpOwnSystemEcuNumber" 0;
BA_DEF_DEF_  "FlexKomComment" "";
BA_DEF_DEF_  "FlexKomIsMotorola" "nein";
BA_DEF_DEF_  "FlexKomSID" 0;
BA_DEF_DEF_  "FlexKomSigLaenge" 0;
BA_DEF_DEF_  "FlexKomSigName" "";
BA_DEF_DEF_  "FlexKomSigStartPos" 0;
BA_DEF_DEF_  "FlexKomSigStartValue" "";
BA_DEF_DEF_  "GenSigCycleTime" 0;
BA_DEF_DEF_  "GenSigCycleTimeActive" 0;
BA_DEF_DEF_  "GenSigSendType" "cyclicX";
BA_DEF_DEF_  "GenSigSNA" "";
BA_DEF_DEF_  "GenSigStartValue" 0;
BA_DEF_DEF_  "GenSigTimeout_CBC" 0;
BA_DEF_DEF_  "GenSigTimeout_EPS" 0;
BA_DEF_DEF_  "GenSigTimeout_ESC" 0;
BA_DEF_DEF_  "GenSigTimeout_ESL" 0;
BA_DEF_DEF_  "GenSigTimeout_RHSC2" 0;
BA_DEF_DEF_  "GenSigTimeout_ETM" 0;
BA_DEF_DEF_  "GenSigTimeout_HaLF" 0;
BA_DEF_DEF_  "GenSigTimeout_IC" 0;
BA_DEF_DEF_  "GenSigTimeout_OCM" 0;
BA_DEF_DEF_  "GenSigTimeout_ORC" 0;
BA_DEF_DEF_  "GenSigTimeout_PTS" 0;
BA_DEF_DEF_  "GenSigTimeout_RF_HUB" 0;
BA_DEF_DEF_  "GenSigTimeout_SCCM" 0;
BA_DEF_DEF_  "RID" "";
BA_ "NWM-Knoten" BU_ CBC 1;
BA_ "NWM-Stationsadresse" BU_ CBC 1;
BA_ "NWM-Knoten" BU_ EBCM 1;
BA_ "NWM-Stationsadresse" BU_ EBCM 59;
BA_ "NWM-Knoten" BU_ EPSB 1;
BA_ "NWM-Stationsadresse" BU_ EPSB 26;
BA_ "NWM-Knoten" BU_ ESC 1;
BA_ "NWM-Stationsadresse" BU_ ESC 7;
BA_ "NWM-Knoten" BU_ ESL 1;
BA_ "NWM-Stationsadresse" BU_ ESL 8;
BA_ "NWM-Knoten" BU_ HCP 1;
BA_ "NWM-Stationsadresse" BU_ HCP 58;
BA_ "NWM-Knoten" BU_ IC 1;
BA_ "NWM-Stationsadresse" BU_ IC 2;
BA_ "NWM-Knoten" BU_ RF_HUB 1;
BA_ "NWM-Knoten" BU_ SCCM 1;
BA_ "NWM-Stationsadresse" BU_ SCCM 35;
BA_ "GenMsgStartValue" BO_ 1089 "0000000000000000h";
BA_ "GenMsgNrOfRepetitions" BO_ 1089 2;
BA_ "GenMsgDelayTime" BO_ 1089 20;
BA_ "DiagState" BO_ 1089 1;
BA_ "GenMsgStartValue" BO_ 501 "00FFFF00000000FFh";
BA_ "GenMsgNrOfRepetitions" BO_ 501 2;
BA_ "GenMsgDelayTime" BO_ 501 20;
BA_ "GenMsgCycleTime" BO_ 501 60;
BA_ "App-Botschaft" BO_ 1747 1;
BA_ "GenMsgDelayTime" BO_ 1747 20;
BA_ "GenMsgNrOfRepetitions" BO_ 1747 2;
BA_ "GenMsgSendType" BO_ 1747 1;
BA_ "GenMsgStartValue" BO_ 1747 "0000000000000000h";
BA_ "App-Botschaft" BO_ 1754 1;
BA_ "GenMsgDelayTime" BO_ 1754 20;
BA_ "GenMsgNrOfRepetitions" BO_ 1754 2;
BA_ "GenMsgSendType" BO_ 1754 1;
BA_ "GenMsgStartValue" BO_ 1754 "0000000000000000h";
BA_ "App-Botschaft" BO_ 1764 1;
BA_ "GenMsgDelayTime" BO_ 1764 20;
BA_ "GenMsgNrOfRepetitions" BO_ 1764 2;
BA_ "GenMsgSendType" BO_ 1764 1;
BA_ "GenMsgStartValue" BO_ 1764 "0000000000000000h";
BA_ "App-Botschaft" BO_ 1762 1;
BA_ "GenMsgDelayTime" BO_ 1762 20;
BA_ "GenMsgNrOfRepetitions" BO_ 1762 2;
BA_ "GenMsgSendType" BO_ 1762 1;
BA_ "GenMsgStartValue" BO_ 1762 "0000000000000000h";
BA_ "GenMsgCycleTime" BO_ 838 1000;
BA_ "GenMsgDelayTime" BO_ 838 20;
BA_ "GenMsgNrOfRepetitions" BO_ 838 2;
BA_ "GenMsgSendType" BO_ 838 5;
BA_ "GenMsgStartValue" BO_ 838 "0000h";
BA_ "GenMsgCycleTime" BO_ 168 10;
BA_ "GenMsgDelayTime" BO_ 168 20;
BA_ "GenMsgNrOfRepetitions" BO_ 168 2;
BA_ "GenMsgStartValue" BO_ 168 "0B830B830B8300FFh";
BA_ "GenMsgCycleTime" BO_ 720 500;
BA_ "GenMsgDelayTime" BO_ 720 20;
BA_ "GenMsgNrOfRepetitions" BO_ 720 2;
BA_ "GenMsgSendType" BO_ 720 5;
BA_ "GenMsgStartValue" BO_ 720 "0003C0000000h";
BA_ "GenMsgCycleTime" BO_ 820 1000;
BA_ "GenMsgDelayTime" BO_ 820 20;
BA_ "GenMsgNrOfRepetitions" BO_ 820 2;
BA_ "GenMsgSendType" BO_ 820 5;
BA_ "GenMsgStartDelayTime" BO_ 820 20;
BA_ "GenMsgStartValue" BO_ 820 "6000003FFFFC0000h";
BA_ "GenMsgCycleTime" BO_ 274 20;
BA_ "GenMsgDelayTime" BO_ 274 20;
BA_ "GenMsgNrOfRepetitions" BO_ 274 2;
BA_ "GenMsgStartValue" BO_ 274 "0000h";
BA_ "GenMsgCycleTime" BO_ 512 100;
BA_ "GenMsgDelayTime" BO_ 512 20;
BA_ "GenMsgNrOfRepetitions" BO_ 512 2;
BA_ "GenMsgStartValue" BO_ 512 "FFFFFFFFFFFFFFFFh";
BA_ "GenMsgCycleTime" BO_ 804 1000;
BA_ "GenMsgDelayTime" BO_ 804 20;
BA_ "GenMsgNrOfRepetitions" BO_ 804 2;
BA_ "GenMsgSendType" BO_ 804 5;
BA_ "GenMsgStartDelayTime" BO_ 804 30;
BA_ "GenMsgStartValue" BO_ 804 "000C000000010000h";
BA_ "GenMsgCycleTimeActive" BO_ 788 50;
BA_ "GenMsgDelayTime" BO_ 788 20;
BA_ "GenMsgNrOfRepetitions" BO_ 788 2;
BA_ "GenMsgSendType" BO_ 788 2;
BA_ "GenMsgStartValue" BO_ 788 "000000h";
BA_ "GenMsgCycleTime" BO_ 500 20;
BA_ "GenMsgDelayTime" BO_ 500 20;
BA_ "GenMsgNrOfRepetitions" BO_ 500 2;
BA_ "GenMsgStartValue" BO_ 500 "1FFF0CCB000000FFh";
BA_ "GenMsgCycleTime" BO_ 625 20;
BA_ "GenMsgDelayTime" BO_ 625 20;
BA_ "GenMsgNrOfRepetitions" BO_ 625 2;
BA_ "GenMsgStartValue" BO_ 625 "000000FF000000FFh";
BA_ "DiagState" BO_ 2015 1;
BA_ "GenMsgDelayTime" BO_ 2015 20;
BA_ "GenMsgNrOfRepetitions" BO_ 2015 2;
BA_ "GenMsgStartValue" BO_ 2015 "0000000000000000h";
BA_ "DiagRequest" BO_ 1875 1;
BA_ "GenMsgDelayTime" BO_ 1875 20;
BA_ "GenMsgNrOfRepetitions" BO_ 1875 2;
BA_ "GenMsgSendType" BO_ 1875 1;
BA_ "GenMsgStartValue" BO_ 1875 "0000000000000000h";
BA_ "DiagRequest" BO_ 1882 1;
BA_ "GenMsgDelayTime" BO_ 1882 20;
BA_ "GenMsgNrOfRepetitions" BO_ 1882 2;
BA_ "GenMsgSendType" BO_ 1882 1;
BA_ "GenMsgStartValue" BO_ 1882 "0000000000000000h";
BA_ "DiagRequest" BO_ 1892 1;
BA_ "GenMsgDelayTime" BO_ 1892 20;
BA_ "GenMsgNrOfRepetitions" BO_ 1892 2;
BA_ "GenMsgSendType" BO_ 1892 1;
BA_ "GenMsgStartValue" BO_ 1892 "0000000000000000h";
BA_ "DiagRequest" BO_ 1890 1;
BA_ "GenMsgDelayTime" BO_ 1890 20;
BA_ "GenMsgNrOfRepetitions" BO_ 1890 2;
BA_ "GenMsgSendType" BO_ 1890 1;
BA_ "GenMsgStartValue" BO_ 1890 "0000000000000000h";
BA_ "DiagResponse" BO_ 1235 1;
BA_ "GenMsgDelayTime" BO_ 1235 20;
BA_ "GenMsgNrOfRepetitions" BO_ 1235 2;
BA_ "GenMsgSendType" BO_ 1235 1;
BA_ "GenMsgStartValue" BO_ 1235 "0000000000000000h";
BA_ "DiagResponse" BO_ 1242 1;
BA_ "GenMsgDelayTime" BO_ 1242 20;
BA_ "GenMsgNrOfRepetitions" BO_ 1242 2;
BA_ "GenMsgSendType" BO_ 1242 1;
BA_ "GenMsgStartValue" BO_ 1242 "0000000000000000h";
BA_ "DiagResponse" BO_ 1252 1;
BA_ "GenMsgDelayTime" BO_ 1252 20;
BA_ "GenMsgNrOfRepetitions" BO_ 1252 2;
BA_ "GenMsgSendType" BO_ 1252 1;
BA_ "GenMsgStartValue" BO_ 1252 "0000000000000000h";
BA_ "DiagResponse" BO_ 1250 1;
BA_ "GenMsgDelayTime" BO_ 1250 20;
BA_ "GenMsgNrOfRepetitions" BO_ 1250 2;
BA_ "GenMsgSendType" BO_ 1250 1;
BA_ "GenMsgStartValue" BO_ 1250 "0000000000000000h";
BA_ "GenMsgCycleTime" BO_ 264 10;
BA_ "GenMsgDelayTime" BO_ 264 20;
BA_ "GenMsgNrOfRepetitions" BO_ 264 2;
BA_ "GenMsgStartValue" BO_ 264 "FFFF1FFF1FFF00FFh";
BA_ "GenMsgCycleTime" BO_ 288 20;
BA_ "GenMsgDelayTime" BO_ 288 20;
BA_ "GenMsgNrOfRepetitions" BO_ 288 2;
BA_ "GenMsgStartValue" BO_ 288 "1FFFFF1FFF00FFh";
BA_ "GenMsgCycleTime" BO_ 760 10;
BA_ "GenMsgDelayTime" BO_ 760 20;
BA_ "GenMsgNrOfRepetitions" BO_ 760 2;
BA_ "GenMsgStartValue" BO_ 760 "5FFF1FFF00FF0FFFh";
BA_ "GenMsgCycleTime" BO_ 559 20;
BA_ "GenMsgDelayTime" BO_ 559 20;
BA_ "GenMsgNrOfRepetitions" BO_ 559 2;
BA_ "GenMsgStartValue" BO_ 559 "FFFFFFFF00000CFFh";
BA_ "GenMsgCycleTime" BO_ 384 100;
BA_ "GenMsgDelayTime" BO_ 384 20;
BA_ "GenMsgNrOfRepetitions" BO_ 384 2;
BA_ "GenMsgStartValue" BO_ 384 "00FFFF000001FFFFh";
BA_ "GenMsgCycleTime" BO_ 800 100;
BA_ "GenMsgDelayTime" BO_ 800 20;
BA_ "GenMsgNrOfRepetitions" BO_ 800 2;
BA_ "GenMsgStartValue" BO_ 800 "00000000F0000000h";
BA_ "GenMsgCycleTime" BO_ 280 10;
BA_ "GenMsgDelayTime" BO_ 280 20;
BA_ "GenMsgNrOfRepetitions" BO_ 280 2;
BA_ "GenMsgStartValue" BO_ 280 "9FFF1FFF1FFF00FFh";
BA_ "App-Botschaft" BO_ 1427 1;
BA_ "GenMsgDelayTime" BO_ 1427 20;
BA_ "GenMsgNrOfRepetitions" BO_ 1427 2;
BA_ "GenMsgSendType" BO_ 1427 1;
BA_ "GenMsgStartValue" BO_ 1427 "0000000000000000h";
BA_ "App-Botschaft" BO_ 1434 1;
BA_ "GenMsgDelayTime" BO_ 1434 20;
BA_ "GenMsgNrOfRepetitions" BO_ 1434 2;
BA_ "GenMsgSendType" BO_ 1434 1;
BA_ "GenMsgStartValue" BO_ 1434 "0000000000000000h";
BA_ "App-Botschaft" BO_ 1444 1;
BA_ "GenMsgDelayTime" BO_ 1444 20;
BA_ "GenMsgNrOfRepetitions" BO_ 1444 2;
BA_ "GenMsgSendType" BO_ 1444 1;
BA_ "GenMsgStartValue" BO_ 1444 "0000000000000000h";
BA_ "App-Botschaft" BO_ 1442 1;
BA_ "GenMsgDelayTime" BO_ 1442 20;
BA_ "GenMsgNrOfRepetitions" BO_ 1442 2;
BA_ "GenMsgSendType" BO_ 1442 1;
BA_ "GenMsgStartValue" BO_ 1442 "0000000000000000h";
BA_ "GenMsgCycleTime" BO_ 993 100;
BA_ "GenMsgDelayTime" BO_ 993 20;
BA_ "GenMsgNrOfRepetitions" BO_ 993 2;
BA_ "GenMsgStartValue" BO_ 993 "FFEFE7E71F0000h";
BA_ "GenMsgCycleTime" BO_ 770 250;
BA_ "GenMsgDelayTime" BO_ 770 20;
BA_ "GenMsgNrOfRepetitions" BO_ 770 2;
BA_ "GenMsgStartValue" BO_ 770 "00000000000000FFh";
BA_ "GenMsgCycleTime" BO_ 669 40;
BA_ "GenMsgDelayTime" BO_ 669 20;
BA_ "GenMsgNrOfRepetitions" BO_ 669 2;
BA_ "GenMsgStartValue" BO_ 669 "0000FFh";
BA_ "GenMsgCycleTime" BO_ 544 10;
BA_ "GenMsgDelayTime" BO_ 544 20;
BA_ "GenMsgNrOfRepetitions" BO_ 544 2;
BA_ "GenMsgStartValue" BO_ 544 "07FF07FF040000FFh";
BA_ "RID" SG_ 1089 DG_RQ_GLOBAL_UDS "2075";
BA_ "GenSigSNA" SG_ 1089 DG_RQ_GLOBAL_UDS "0h";
BA_ "FlexKomSigStartValue" SG_ 1089 DG_RQ_GLOBAL_UDS "0000000000000000h";
BA_ "FlexKomSigStartPos" SG_ 1089 DG_RQ_GLOBAL_UDS 7;
BA_ "FlexKomSigName" SG_ 1089 DG_RQ_GLOBAL_UDS "DG_RQ_GLOBAL_UDS";
BA_ "FlexKomSigLaenge" SG_ 1089 DG_RQ_GLOBAL_UDS 64;
BA_ "FlexKomSID" SG_ 1089 DG_RQ_GLOBAL_UDS 393;
BA_ "FlexKomIsMotorola" SG_ 1089 DG_RQ_GLOBAL_UDS 1;
BA_ "FlexKomComment" SG_ 1089 DG_RQ_GLOBAL_UDS "Diagnostic-Request";
BA_ "GenSigTimeout_IC" SG_ 501 Sm_ICON_Dspl 630;
BA_ "GenSigSNA" SG_ 501 Sm_ICON_Dspl "3Fh";
BA_ "GenSigCycleTime" SG_ 501 Sm_ICON_Dspl 60;
BA_ "FlexKomSigStartValue" SG_ 501 Sm_ICON_Dspl "00FFFF00000000FFh";
BA_ "FlexKomSigStartPos" SG_ 501 Sm_ICON_Dspl 7;
BA_ "FlexKomSigName" SG_ 501 Sm_ICON_Dspl "DAS_A4_PKT";
BA_ "FlexKomSigLaenge" SG_ 501 Sm_ICON_Dspl 64;
BA_ "FlexKomSID" SG_ 501 Sm_ICON_Dspl 1717;
BA_ "FlexKomIsMotorola" SG_ 501 Sm_ICON_Dspl 1;
BA_ "FlexKomComment" SG_ 501 Sm_ICON_Dspl "DAS_A4 Packet";
BA_ "GenSigTimeout_ORC" SG_ 501 SetSpeed_MPH 210;
BA_ "GenSigTimeout_IC" SG_ 501 SetSpeed_MPH 630;
BA_ "GenSigStartValue" SG_ 501 SetSpeed_MPH 255;
BA_ "GenSigSNA" SG_ 501 SetSpeed_MPH "FFh";
BA_ "GenSigCycleTime" SG_ 501 SetSpeed_MPH 60;
BA_ "FlexKomSigStartValue" SG_ 501 SetSpeed_MPH "00FFFF00000000FFh";
BA_ "FlexKomSigStartPos" SG_ 501 SetSpeed_MPH 7;
BA_ "FlexKomSigName" SG_ 501 SetSpeed_MPH "DAS_A4_PKT";
BA_ "FlexKomSigLaenge" SG_ 501 SetSpeed_MPH 64;
BA_ "FlexKomSID" SG_ 501 SetSpeed_MPH 1717;
BA_ "FlexKomIsMotorola" SG_ 501 SetSpeed_MPH 1;
BA_ "FlexKomComment" SG_ 501 SetSpeed_MPH "DAS_A4 Packet";
BA_ "GenSigTimeout_IC" SG_ 501 SetSpeed_KPH 630;
BA_ "GenSigStartValue" SG_ 501 SetSpeed_KPH 255;
BA_ "GenSigSNA" SG_ 501 SetSpeed_KPH "FFh";
BA_ "GenSigCycleTime" SG_ 501 SetSpeed_KPH 60;
BA_ "FlexKomSigStartValue" SG_ 501 SetSpeed_KPH "00FFFF00000000FFh";
BA_ "FlexKomSigStartPos" SG_ 501 SetSpeed_KPH 7;
BA_ "FlexKomSigName" SG_ 501 SetSpeed_KPH "DAS_A4_PKT";
BA_ "FlexKomSigLaenge" SG_ 501 SetSpeed_KPH 64;
BA_ "FlexKomSID" SG_ 501 SetSpeed_KPH 1717;
BA_ "FlexKomIsMotorola" SG_ 501 SetSpeed_KPH 1;
BA_ "FlexKomComment" SG_ 501 SetSpeed_KPH "DAS_A4 Packet";
BA_ "GenSigTimeout_ORC" SG_ 501 RadarBlocked 210;
BA_ "GenSigTimeout_IC" SG_ 501 RadarBlocked 630;
BA_ "GenSigSNA" SG_ 501 RadarBlocked "0h";
BA_ "GenSigCycleTime" SG_ 501 RadarBlocked 60;
BA_ "FlexKomSigStartValue" SG_ 501 RadarBlocked "00FFFF00000000FFh";
BA_ "FlexKomSigStartPos" SG_ 501 RadarBlocked 7;
BA_ "FlexKomSigName" SG_ 501 RadarBlocked "DAS_A4_PKT";
BA_ "FlexKomSigLaenge" SG_ 501 RadarBlocked 64;
BA_ "FlexKomSID" SG_ 501 RadarBlocked 1717;
BA_ "FlexKomIsMotorola" SG_ 501 RadarBlocked 1;
BA_ "FlexKomComment" SG_ 501 RadarBlocked "DAS_A4 Packet";
BA_ "GenSigTimeout_ORC" SG_ 501 ObjIntrstDist 210;
BA_ "GenSigStartValue" SG_ 501 ObjIntrstDist 255;
BA_ "GenSigSNA" SG_ 501 ObjIntrstDist "FFh";
BA_ "GenSigCycleTime" SG_ 501 ObjIntrstDist 60;
BA_ "FlexKomSigStartValue" SG_ 501 ObjIntrstDist "00FFFF00000000FFh";
BA_ "FlexKomSigStartPos" SG_ 501 ObjIntrstDist 7;
BA_ "FlexKomSigName" SG_ 501 ObjIntrstDist "DAS_A4_PKT";
BA_ "FlexKomSigLaenge" SG_ 501 ObjIntrstDist 64;
BA_ "FlexKomSID" SG_ 501 ObjIntrstDist 1717;
BA_ "FlexKomIsMotorola" SG_ 501 ObjIntrstDist 1;
BA_ "FlexKomComment" SG_ 501 ObjIntrstDist "DAS_A4 Packet";
BA_ "GenSigTimeout_IC" SG_ 501 NCConlyNA_DASMSts 630;
BA_ "GenSigSNA" SG_ 501 NCConlyNA_DASMSts "0h";
BA_ "GenSigCycleTime" SG_ 501 NCConlyNA_DASMSts 60;
BA_ "FlexKomSigStartValue" SG_ 501 NCConlyNA_DASMSts "00FFFF00000000FFh";
BA_ "FlexKomSigStartPos" SG_ 501 NCConlyNA_DASMSts 7;
BA_ "FlexKomSigName" SG_ 501 NCConlyNA_DASMSts "DAS_A4_PKT";
BA_ "FlexKomSigLaenge" SG_ 501 NCConlyNA_DASMSts 64;
BA_ "FlexKomSID" SG_ 501 NCConlyNA_DASMSts 1717;
BA_ "FlexKomIsMotorola" SG_ 501 NCConlyNA_DASMSts 1;
BA_ "FlexKomComment" SG_ 501 NCConlyNA_DASMSts "DAS_A4 Packet";
BA_ "GenSigTimeout_ORC" SG_ 501 NCCNA_DASMSts 210;
BA_ "GenSigTimeout_IC" SG_ 501 NCCNA_DASMSts 630;
BA_ "GenSigSNA" SG_ 501 NCCNA_DASMSts "0h";
BA_ "GenSigCycleTime" SG_ 501 NCCNA_DASMSts 60;
BA_ "FlexKomSigStartValue" SG_ 501 NCCNA_DASMSts "00FFFF00000000FFh";
BA_ "FlexKomSigStartPos" SG_ 501 NCCNA_DASMSts 7;
BA_ "FlexKomSigName" SG_ 501 NCCNA_DASMSts "DAS_A4_PKT";
BA_ "FlexKomSigLaenge" SG_ 501 NCCNA_DASMSts 64;
BA_ "FlexKomSID" SG_ 501 NCCNA_DASMSts 1717;
BA_ "FlexKomIsMotorola" SG_ 501 NCCNA_DASMSts 1;
BA_ "FlexKomComment" SG_ 501 NCCNA_DASMSts "DAS_A4 Packet";
BA_ "GenSigTimeout_ORC" SG_ 501 HMI_Screens 210;
BA_ "GenSigTimeout_IC" SG_ 501 HMI_Screens 630;
BA_ "GenSigSNA" SG_ 501 HMI_Screens "FFh";
BA_ "GenSigCycleTime" SG_ 501 HMI_Screens 60;
BA_ "FlexKomSigStartValue" SG_ 501 HMI_Screens "00FFFF00000000FFh";
BA_ "FlexKomSigStartPos" SG_ 501 HMI_Screens 7;
BA_ "FlexKomSigName" SG_ 501 HMI_Screens "DAS_A4_PKT";
BA_ "FlexKomSigLaenge" SG_ 501 HMI_Screens 64;
BA_ "FlexKomSID" SG_ 501 HMI_Screens 1717;
BA_ "FlexKomIsMotorola" SG_ 501 HMI_Screens 1;
BA_ "FlexKomComment" SG_ 501 HMI_Screens "DAS_A4 Packet";
BA_ "GenSigSNA" SG_ 501 FCWonlyNA_DASMSts "0h";
BA_ "GenSigCycleTime" SG_ 501 FCWonlyNA_DASMSts 60;
BA_ "FlexKomSigStartValue" SG_ 501 FCWonlyNA_DASMSts "00FFFF00000000FFh";
BA_ "FlexKomSigStartPos" SG_ 501 FCWonlyNA_DASMSts 7;
BA_ "FlexKomSigName" SG_ 501 FCWonlyNA_DASMSts "DAS_A4_PKT";
BA_ "FlexKomSigLaenge" SG_ 501 FCWonlyNA_DASMSts 64;
BA_ "FlexKomSID" SG_ 501 FCWonlyNA_DASMSts 1717;
BA_ "FlexKomIsMotorola" SG_ 501 FCWonlyNA_DASMSts 1;
BA_ "FlexKomComment" SG_ 501 FCWonlyNA_DASMSts "DAS_A4 Packet";
BA_ "GenSigTimeout_ORC" SG_ 501 FCW_Error 210;
BA_ "GenSigTimeout_IC" SG_ 501 FCW_Error 630;
BA_ "GenSigSNA" SG_ 501 FCW_Error "3h";
BA_ "GenSigCycleTime" SG_ 501 FCW_Error 60;
BA_ "FlexKomSigStartValue" SG_ 501 FCW_Error "00FFFF00000000FFh";
BA_ "FlexKomSigStartPos" SG_ 501 FCW_Error 7;
BA_ "FlexKomSigName" SG_ 501 FCW_Error "DAS_A4_PKT";
BA_ "FlexKomSigLaenge" SG_ 501 FCW_Error 64;
BA_ "FlexKomSID" SG_ 501 FCW_Error 1717;
BA_ "FlexKomIsMotorola" SG_ 501 FCW_Error 1;
BA_ "FlexKomComment" SG_ 501 FCW_Error "DAS_A4 Packet";
BA_ "RID" SG_ 501 FCW_BrkOn "1882";
BA_ "GenSigTimeout_ORC" SG_ 501 FCW_BrkOn 210;
BA_ "GenSigTimeout_IC" SG_ 501 FCW_BrkOn 630;
BA_ "GenSigTimeout_CBC" SG_ 501 FCW_BrkOn 630;
BA_ "GenSigSNA" SG_ 501 FCW_BrkOn "0h";
BA_ "GenSigCycleTime" SG_ 501 FCW_BrkOn 60;
BA_ "FlexKomSigStartValue" SG_ 501 FCW_BrkOn "00FFFF00000000FFh";
BA_ "FlexKomSigStartPos" SG_ 501 FCW_BrkOn 7;
BA_ "FlexKomSigName" SG_ 501 FCW_BrkOn "DAS_A4_PKT";
BA_ "FlexKomSigLaenge" SG_ 501 FCW_BrkOn 64;
BA_ "FlexKomSID" SG_ 501 FCW_BrkOn 1717;
BA_ "FlexKomIsMotorola" SG_ 501 FCW_BrkOn 1;
BA_ "FlexKomComment" SG_ 501 FCW_BrkOn "DAS_A4 Packet";
BA_ "GenSigTimeout_ORC" SG_ 501 FCWBrakingOff 210;
BA_ "GenSigTimeout_IC" SG_ 501 FCWBrakingOff 630;
BA_ "GenSigSNA" SG_ 501 FCWBrakingOff "0h";
BA_ "GenSigCycleTime" SG_ 501 FCWBrakingOff 60;
BA_ "FlexKomSigStartValue" SG_ 501 FCWBrakingOff "00FFFF00000000FFh";
BA_ "FlexKomSigStartPos" SG_ 501 FCWBrakingOff 7;
BA_ "FlexKomSigName" SG_ 501 FCWBrakingOff "DAS_A4_PKT";
BA_ "FlexKomSigLaenge" SG_ 501 FCWBrakingOff 64;
BA_ "FlexKomSID" SG_ 501 FCWBrakingOff 1717;
BA_ "FlexKomIsMotorola" SG_ 501 FCWBrakingOff 1;
BA_ "FlexKomComment" SG_ 501 FCWBrakingOff "DAS_A4 Packet";
BA_ "GenSigTimeout_ORC" SG_ 501 CameraFailure 210;
BA_ "GenSigTimeout_IC" SG_ 501 CameraFailure 630;
BA_ "GenSigSNA" SG_ 501 CameraFailure "0h";
BA_ "GenSigCycleTime" SG_ 501 CameraFailure 60;
BA_ "FlexKomSigStartValue" SG_ 501 CameraFailure "00FFFF00000000FFh";
BA_ "FlexKomSigStartPos" SG_ 501 CameraFailure 7;
BA_ "FlexKomSigName" SG_ 501 CameraFailure "DAS_A4_PKT";
BA_ "FlexKomSigLaenge" SG_ 501 CameraFailure 64;
BA_ "FlexKomSID" SG_ 501 CameraFailure 1717;
BA_ "FlexKomIsMotorola" SG_ 501 CameraFailure 1;
BA_ "FlexKomComment" SG_ 501 CameraFailure "DAS_A4 Packet";
BA_ "GenSigTimeout_ORC" SG_ 501 CameraBlocked 210;
BA_ "GenSigTimeout_IC" SG_ 501 CameraBlocked 630;
BA_ "GenSigSNA" SG_ 501 CameraBlocked "0h";
BA_ "GenSigCycleTime" SG_ 501 CameraBlocked 60;
BA_ "FlexKomSigStartValue" SG_ 501 CameraBlocked "00FFFF00000000FFh";
BA_ "FlexKomSigStartPos" SG_ 501 CameraBlocked 7;
BA_ "FlexKomSigName" SG_ 501 CameraBlocked "DAS_A4_PKT";
BA_ "FlexKomSigLaenge" SG_ 501 CameraBlocked 64;
BA_ "FlexKomSID" SG_ 501 CameraBlocked 1717;
BA_ "FlexKomIsMotorola" SG_ 501 CameraBlocked 1;
BA_ "FlexKomComment" SG_ 501 CameraBlocked "DAS_A4 Packet";
BA_ "GenSigTimeout_ORC" SG_ 501 CIPV_Fused 210;
BA_ "GenSigSNA" SG_ 501 CIPV_Fused "0h";
BA_ "GenSigCycleTime" SG_ 501 CIPV_Fused 60;
BA_ "FlexKomSigStartValue" SG_ 501 CIPV_Fused "00FFFF00000000FFh";
BA_ "FlexKomSigStartPos" SG_ 501 CIPV_Fused 7;
BA_ "FlexKomSigName" SG_ 501 CIPV_Fused "DAS_A4_PKT";
BA_ "FlexKomSigLaenge" SG_ 501 CIPV_Fused 64;
BA_ "FlexKomSID" SG_ 501 CIPV_Fused 1717;
BA_ "FlexKomIsMotorola" SG_ 501 CIPV_Fused 1;
BA_ "FlexKomComment" SG_ 501 CIPV_Fused "DAS_A4 Packet";
BA_ "GenSigTimeout_IC" SG_ 501 ACConlyNA_DASMSts 630;
BA_ "GenSigSNA" SG_ 501 ACConlyNA_DASMSts "0h";
BA_ "GenSigCycleTime" SG_ 501 ACConlyNA_DASMSts 60;
BA_ "FlexKomSigStartValue" SG_ 501 ACConlyNA_DASMSts "00FFFF00000000FFh";
BA_ "FlexKomSigStartPos" SG_ 501 ACConlyNA_DASMSts 7;
BA_ "FlexKomSigName" SG_ 501 ACConlyNA_DASMSts "DAS_A4_PKT";
BA_ "FlexKomSigLaenge" SG_ 501 ACConlyNA_DASMSts 64;
BA_ "FlexKomSID" SG_ 501 ACConlyNA_DASMSts 1717;
BA_ "FlexKomIsMotorola" SG_ 501 ACConlyNA_DASMSts 1;
BA_ "FlexKomComment" SG_ 501 ACConlyNA_DASMSts "DAS_A4 Packet";
BA_ "GenSigTimeout_IC" SG_ 501 ACC_HMI_SCRN_REQ 630;
BA_ "GenSigSNA" SG_ 501 ACC_HMI_SCRN_REQ "0h";
BA_ "GenSigCycleTime" SG_ 501 ACC_HMI_SCRN_REQ 60;
BA_ "FlexKomSigStartValue" SG_ 501 ACC_HMI_SCRN_REQ "00FFFF00000000FFh";
BA_ "FlexKomSigStartPos" SG_ 501 ACC_HMI_SCRN_REQ 7;
BA_ "FlexKomSigName" SG_ 501 ACC_HMI_SCRN_REQ "DAS_A4_PKT";
BA_ "FlexKomSigLaenge" SG_ 501 ACC_HMI_SCRN_REQ 64;
BA_ "FlexKomSID" SG_ 501 ACC_HMI_SCRN_REQ 1717;
BA_ "FlexKomIsMotorola" SG_ 501 ACC_HMI_SCRN_REQ 1;
BA_ "FlexKomComment" SG_ 501 ACC_HMI_SCRN_REQ "DAS_A4 Packet";
BA_ "GenSigTimeout_ORC" SG_ 501 ACCOnOff 210;
BA_ "GenSigTimeout_IC" SG_ 501 ACCOnOff 630;
BA_ "GenSigSNA" SG_ 501 ACCOnOff "7h";
BA_ "GenSigCycleTime" SG_ 501 ACCOnOff 60;
BA_ "FlexKomSigStartValue" SG_ 501 ACCOnOff "00FFFF00000000FFh";
BA_ "FlexKomSigStartPos" SG_ 501 ACCOnOff 7;
BA_ "FlexKomSigName" SG_ 501 ACCOnOff "DAS_A4_PKT";
BA_ "FlexKomSigLaenge" SG_ 501 ACCOnOff 64;
BA_ "FlexKomSID" SG_ 501 ACCOnOff 1717;
BA_ "FlexKomIsMotorola" SG_ 501 ACCOnOff 1;
BA_ "FlexKomComment" SG_ 501 ACCOnOff "DAS_A4 Packet";
BA_ "GenSigTimeout_ORC" SG_ 501 ACCNA_DASMSts 210;
BA_ "GenSigTimeout_IC" SG_ 501 ACCNA_DASMSts 630;
BA_ "GenSigSNA" SG_ 501 ACCNA_DASMSts "0h";
BA_ "GenSigCycleTime" SG_ 501 ACCNA_DASMSts 60;
BA_ "FlexKomSigStartValue" SG_ 501 ACCNA_DASMSts "00FFFF00000000FFh";
BA_ "FlexKomSigStartPos" SG_ 501 ACCNA_DASMSts 7;
BA_ "FlexKomSigName" SG_ 501 ACCNA_DASMSts "DAS_A4_PKT";
BA_ "FlexKomSigLaenge" SG_ 501 ACCNA_DASMSts 64;
BA_ "FlexKomSID" SG_ 501 ACCNA_DASMSts 1717;
BA_ "FlexKomIsMotorola" SG_ 501 ACCNA_DASMSts 1;
BA_ "FlexKomComment" SG_ 501 ACCNA_DASMSts "DAS_A4 Packet";
BA_ "GenSigTimeout_ORC" SG_ 501 ACCFaulted 210;
BA_ "GenSigTimeout_IC" SG_ 501 ACCFaulted 630;
BA_ "GenSigSNA" SG_ 501 ACCFaulted "0h";
BA_ "GenSigCycleTime" SG_ 501 ACCFaulted 60;
BA_ "FlexKomSigStartValue" SG_ 501 ACCFaulted "00FFFF00000000FFh";
BA_ "FlexKomSigStartPos" SG_ 501 ACCFaulted 7;
BA_ "FlexKomSigName" SG_ 501 ACCFaulted "DAS_A4_PKT";
BA_ "FlexKomSigLaenge" SG_ 501 ACCFaulted 64;
BA_ "FlexKomSID" SG_ 501 ACCFaulted 1717;
BA_ "FlexKomIsMotorola" SG_ 501 ACCFaulted 1;
BA_ "FlexKomComment" SG_ 501 ACCFaulted "DAS_A4 Packet";
BA_ "FlexKomComment" SG_ 1747 APPL_ECU_DASM "External Application to ECU";
BA_ "FlexKomIsMotorola" SG_ 1747 APPL_ECU_DASM 1;
BA_ "FlexKomSID" SG_ 1747 APPL_ECU_DASM 298;
BA_ "FlexKomSigLaenge" SG_ 1747 APPL_ECU_DASM 64;
BA_ "FlexKomSigName" SG_ 1747 APPL_ECU_DASM "APPL_ECU_DASM";
BA_ "FlexKomSigStartPos" SG_ 1747 APPL_ECU_DASM 7;
BA_ "FlexKomSigStartValue" SG_ 1747 APPL_ECU_DASM "0000000000000000h";
BA_ "GenSigSendType" SG_ 1747 APPL_ECU_DASM 1;
BA_ "GenSigSNA" SG_ 1747 APPL_ECU_DASM "0h";
BA_ "FlexKomComment" SG_ 1754 APPL_ECU_EPS "External Application to ECU";
BA_ "FlexKomIsMotorola" SG_ 1754 APPL_ECU_EPS 1;
BA_ "FlexKomSID" SG_ 1754 APPL_ECU_EPS 289;
BA_ "FlexKomSigLaenge" SG_ 1754 APPL_ECU_EPS 64;
BA_ "FlexKomSigName" SG_ 1754 APPL_ECU_EPS "APPL_ECU_EPS";
BA_ "FlexKomSigStartPos" SG_ 1754 APPL_ECU_EPS 7;
BA_ "FlexKomSigStartValue" SG_ 1754 APPL_ECU_EPS "0000000000000000h";
BA_ "GenSigSendType" SG_ 1754 APPL_ECU_EPS 1;
BA_ "GenSigSNA" SG_ 1754 APPL_ECU_EPS "0h";
BA_ "FlexKomComment" SG_ 1764 APPL_ECU_HaLF "External Application to ECU";
BA_ "FlexKomIsMotorola" SG_ 1764 APPL_ECU_HaLF 1;
BA_ "FlexKomSID" SG_ 1764 APPL_ECU_HaLF 1631;
BA_ "FlexKomSigLaenge" SG_ 1764 APPL_ECU_HaLF 64;
BA_ "FlexKomSigName" SG_ 1764 APPL_ECU_HaLF "APPL_ECU_HaLF";
BA_ "FlexKomSigStartPos" SG_ 1764 APPL_ECU_HaLF 7;
BA_ "FlexKomSigStartValue" SG_ 1764 APPL_ECU_HaLF "0000000000000000h";
BA_ "GenSigSendType" SG_ 1764 APPL_ECU_HaLF 1;
BA_ "GenSigSNA" SG_ 1764 APPL_ECU_HaLF "0h";
BA_ "FlexKomComment" SG_ 1762 APPL_ECU_PTS "External Application to ECU";
BA_ "FlexKomIsMotorola" SG_ 1762 APPL_ECU_PTS 1;
BA_ "FlexKomSID" SG_ 1762 APPL_ECU_PTS 310;
BA_ "FlexKomSigLaenge" SG_ 1762 APPL_ECU_PTS 64;
BA_ "FlexKomSigName" SG_ 1762 APPL_ECU_PTS "APPL_ECU_PTS";
BA_ "FlexKomSigStartPos" SG_ 1762 APPL_ECU_PTS 7;
BA_ "FlexKomSigStartValue" SG_ 1762 APPL_ECU_PTS "0000000000000000h";
BA_ "GenSigSendType" SG_ 1762 APPL_ECU_PTS 1;
BA_ "GenSigSNA" SG_ 1762 APPL_ECU_PTS "0h";
BA_ "FlexKomComment" SG_ 838 AS_CHIME_TYPE "AS chime status";
BA_ "FlexKomIsMotorola" SG_ 838 AS_CHIME_TYPE 1;
BA_ "FlexKomSID" SG_ 838 AS_CHIME_TYPE 1016;
BA_ "FlexKomSigLaenge" SG_ 838 AS_CHIME_TYPE 16;
BA_ "FlexKomSigName" SG_ 838 AS_CHIME_TYPE "AS_CHIME_STAT";
BA_ "FlexKomSigStartPos" SG_ 838 AS_CHIME_TYPE 7;
BA_ "FlexKomSigStartValue" SG_ 838 AS_CHIME_TYPE "0000h";
BA_ "GenSigCycleTime" SG_ 838 AS_CHIME_TYPE 1000;
BA_ "GenSigSendType" SG_ 838 AS_CHIME_TYPE 5;
BA_ "GenSigSNA" SG_ 838 AS_CHIME_TYPE "Fh";
BA_ "GenSigTimeout_IC" SG_ 838 AS_CHIME_TYPE 10500;
BA_ "GenSigTimeout_ORC" SG_ 838 AS_CHIME_TYPE 3500;
BA_ "RID" SG_ 838 AS_CHIME_TYPE "1056";
BA_ "FlexKomComment" SG_ 838 AS_LF_CHIME_RQ "AS chime status";
BA_ "FlexKomIsMotorola" SG_ 838 AS_LF_CHIME_RQ 1;
BA_ "FlexKomSID" SG_ 838 AS_LF_CHIME_RQ 1016;
BA_ "FlexKomSigLaenge" SG_ 838 AS_LF_CHIME_RQ 16;
BA_ "FlexKomSigName" SG_ 838 AS_LF_CHIME_RQ "AS_CHIME_STAT";
BA_ "FlexKomSigStartPos" SG_ 838 AS_LF_CHIME_RQ 7;
BA_ "FlexKomSigStartValue" SG_ 838 AS_LF_CHIME_RQ "0000h";
BA_ "GenSigCycleTime" SG_ 838 AS_LF_CHIME_RQ 1000;
BA_ "GenSigSendType" SG_ 838 AS_LF_CHIME_RQ 5;
BA_ "GenSigSNA" SG_ 838 AS_LF_CHIME_RQ "0h";
BA_ "RID" SG_ 838 AS_LF_CHIME_RQ "1121";
BA_ "FlexKomComment" SG_ 838 AS_RF_CHIME_RQ "AS chime status";
BA_ "FlexKomIsMotorola" SG_ 838 AS_RF_CHIME_RQ 1;
BA_ "FlexKomSID" SG_ 838 AS_RF_CHIME_RQ 1016;
BA_ "FlexKomSigLaenge" SG_ 838 AS_RF_CHIME_RQ 16;
BA_ "FlexKomSigName" SG_ 838 AS_RF_CHIME_RQ "AS_CHIME_STAT";
BA_ "FlexKomSigStartPos" SG_ 838 AS_RF_CHIME_RQ 7;
BA_ "FlexKomSigStartValue" SG_ 838 AS_RF_CHIME_RQ "0000h";
BA_ "GenSigCycleTime" SG_ 838 AS_RF_CHIME_RQ 1000;
BA_ "GenSigSendType" SG_ 838 AS_RF_CHIME_RQ 5;
BA_ "GenSigSNA" SG_ 838 AS_RF_CHIME_RQ "0h";
BA_ "RID" SG_ 838 AS_RF_CHIME_RQ "1245";
BA_ "FlexKomComment" SG_ 168 CRC_0A8h ".";
BA_ "FlexKomIsMotorola" SG_ 168 CRC_0A8h 1;
BA_ "FlexKomSID" SG_ 168 CRC_0A8h 2291;
BA_ "FlexKomSigLaenge" SG_ 168 CRC_0A8h 64;
BA_ "FlexKomSigName" SG_ 168 CRC_0A8h "Axle_Torque_Information";
BA_ "FlexKomSigStartPos" SG_ 168 CRC_0A8h 7;
BA_ "FlexKomSigStartValue" SG_ 168 CRC_0A8h "0B830B830B8300FFh";
BA_ "GenSigCycleTime" SG_ 168 CRC_0A8h 10;
BA_ "GenSigSNA" SG_ 168 CRC_0A8h "FFh";
BA_ "GenSigStartValue" SG_ 168 CRC_0A8h 255;
BA_ "FlexKomComment" SG_ 168 DrvrIntndedAxleTorq ".";
BA_ "FlexKomIsMotorola" SG_ 168 DrvrIntndedAxleTorq 1;
BA_ "FlexKomSID" SG_ 168 DrvrIntndedAxleTorq 2291;
BA_ "FlexKomSigLaenge" SG_ 168 DrvrIntndedAxleTorq 64;
BA_ "FlexKomSigName" SG_ 168 DrvrIntndedAxleTorq "Axle_Torque_Information";
BA_ "FlexKomSigStartPos" SG_ 168 DrvrIntndedAxleTorq 7;
BA_ "FlexKomSigStartValue" SG_ 168 DrvrIntndedAxleTorq "0B830B830B8300FFh";
BA_ "GenSigCycleTime" SG_ 168 DrvrIntndedAxleTorq 10;
BA_ "GenSigSNA" SG_ 168 DrvrIntndedAxleTorq "3FFFh";
BA_ "GenSigStartValue" SG_ 168 DrvrIntndedAxleTorq 2947;
BA_ "FlexKomComment" SG_ 168 MC_0A8h ".";
BA_ "FlexKomIsMotorola" SG_ 168 MC_0A8h 1;
BA_ "FlexKomSID" SG_ 168 MC_0A8h 2291;
BA_ "FlexKomSigLaenge" SG_ 168 MC_0A8h 64;
BA_ "FlexKomSigName" SG_ 168 MC_0A8h "Axle_Torque_Information";
BA_ "FlexKomSigStartPos" SG_ 168 MC_0A8h 7;
BA_ "FlexKomSigStartValue" SG_ 168 MC_0A8h "0B830B830B8300FFh";
BA_ "GenSigCycleTime" SG_ 168 MC_0A8h 10;
BA_ "GenSigSNA" SG_ 168 MC_0A8h "0h";
BA_ "FlexKomComment" SG_ 720 BSM_Blind_RQ "Sensor blinded request from BSM; 1= sensor blocked";
BA_ "FlexKomIsMotorola" SG_ 720 BSM_Blind_RQ 1;
BA_ "FlexKomSID" SG_ 720 BSM_Blind_RQ 1362;
BA_ "FlexKomSigLaenge" SG_ 720 BSM_Blind_RQ 1;
BA_ "FlexKomSigName" SG_ 720 BSM_Blind_RQ "BSM_Blind_RQ";
BA_ "FlexKomSigStartPos" SG_ 720 BSM_Blind_RQ 13;
BA_ "FlexKomSigStartValue" SG_ 720 BSM_Blind_RQ "00h";
BA_ "GenSigCycleTime" SG_ 720 BSM_Blind_RQ 500;
BA_ "GenSigSendType" SG_ 720 BSM_Blind_RQ 5;
BA_ "GenSigSNA" SG_ 720 BSM_Blind_RQ "0h";
BA_ "GenSigTimeout_HaLF" SG_ 720 BSM_Blind_RQ 5250;
BA_ "GenSigTimeout_IC" SG_ 720 BSM_Blind_RQ 5250;
BA_ "RID" SG_ 720 BSM_Blind_RQ "1158";
BA_ "FlexKomComment" SG_ 720 BSM_CFG_STAT "BSM configuration status";
BA_ "FlexKomIsMotorola" SG_ 720 BSM_CFG_STAT 1;
BA_ "FlexKomSID" SG_ 720 BSM_CFG_STAT 4;
BA_ "FlexKomSigLaenge" SG_ 720 BSM_CFG_STAT 2;
BA_ "FlexKomSigName" SG_ 720 BSM_CFG_STAT "BSM_CFG_STAT";
BA_ "FlexKomSigStartPos" SG_ 720 BSM_CFG_STAT 9;
BA_ "FlexKomSigStartValue" SG_ 720 BSM_CFG_STAT "03h";
BA_ "GenSigCycleTime" SG_ 720 BSM_CFG_STAT 500;
BA_ "GenSigSendType" SG_ 720 BSM_CFG_STAT 5;
BA_ "GenSigSNA" SG_ 720 BSM_CFG_STAT "3h";
BA_ "GenSigStartValue" SG_ 720 BSM_CFG_STAT 3;
BA_ "GenSigTimeout_HaLF" SG_ 720 BSM_CFG_STAT 5250;
BA_ "GenSigTimeout_IC" SG_ 720 BSM_CFG_STAT 5250;
BA_ "RID" SG_ 720 BSM_CFG_STAT "1248";
BA_ "FlexKomComment" SG_ 720 BSM_CFG_STAT_TeenKey "BSM configuration status for teen key";
BA_ "FlexKomIsMotorola" SG_ 720 BSM_CFG_STAT_TeenKey 1;
BA_ "FlexKomSID" SG_ 720 BSM_CFG_STAT_TeenKey 2328;
BA_ "FlexKomSigLaenge" SG_ 720 BSM_CFG_STAT_TeenKey 2;
BA_ "FlexKomSigName" SG_ 720 BSM_CFG_STAT_TeenKey "BSM_CFG_STAT_TeenKey";
BA_ "FlexKomSigStartPos" SG_ 720 BSM_CFG_STAT_TeenKey 23;
BA_ "FlexKomSigStartValue" SG_ 720 BSM_CFG_STAT_TeenKey "03h";
BA_ "GenSigCycleTime" SG_ 720 BSM_CFG_STAT_TeenKey 500;
BA_ "GenSigSendType" SG_ 720 BSM_CFG_STAT_TeenKey 5;
BA_ "GenSigSNA" SG_ 720 BSM_CFG_STAT_TeenKey "3h";
BA_ "GenSigStartValue" SG_ 720 BSM_CFG_STAT_TeenKey 3;
BA_ "RID" SG_ 720 BSM_CFG_STAT_TeenKey "2164";
BA_ "FlexKomComment" SG_ 720 BSM_LT_WRN "Blind spot detection warning status";
BA_ "FlexKomIsMotorola" SG_ 720 BSM_LT_WRN 1;
BA_ "FlexKomSID" SG_ 720 BSM_LT_WRN 9;
BA_ "FlexKomSigLaenge" SG_ 720 BSM_LT_WRN 6;
BA_ "FlexKomSigName" SG_ 720 BSM_LT_WRN "BSM_WRN";
BA_ "FlexKomSigStartPos" SG_ 720 BSM_LT_WRN 5;
BA_ "FlexKomSigStartValue" SG_ 720 BSM_LT_WRN "00h";
BA_ "GenSigCycleTime" SG_ 720 BSM_LT_WRN 500;
BA_ "GenSigSendType" SG_ 720 BSM_LT_WRN 5;
BA_ "GenSigSNA" SG_ 720 BSM_LT_WRN "7h";
BA_ "GenSigTimeout_HaLF" SG_ 720 BSM_LT_WRN 5250;
BA_ "GenSigTimeout_IC" SG_ 720 BSM_LT_WRN 5250;
BA_ "RID" SG_ 720 BSM_LT_WRN "1209";
BA_ "FlexKomComment" SG_ 720 BSM_OPR_STAT "BSM operation status; 1= operational failure";
BA_ "FlexKomIsMotorola" SG_ 720 BSM_OPR_STAT 1;
BA_ "FlexKomSID" SG_ 720 BSM_OPR_STAT 7;
BA_ "FlexKomSigLaenge" SG_ 720 BSM_OPR_STAT 1;
BA_ "FlexKomSigName" SG_ 720 BSM_OPR_STAT "BSM_OPR_STAT";
BA_ "FlexKomSigStartPos" SG_ 720 BSM_OPR_STAT 11;
BA_ "FlexKomSigStartValue" SG_ 720 BSM_OPR_STAT "00h";
BA_ "GenSigCycleTime" SG_ 720 BSM_OPR_STAT 500;
BA_ "GenSigSendType" SG_ 720 BSM_OPR_STAT 5;
BA_ "GenSigSNA" SG_ 720 BSM_OPR_STAT "0h";
BA_ "GenSigTimeout_HaLF" SG_ 720 BSM_OPR_STAT 5250;
BA_ "GenSigTimeout_IC" SG_ 720 BSM_OPR_STAT 5250;
BA_ "RID" SG_ 720 BSM_OPR_STAT "1115";
BA_ "FlexKomComment" SG_ 720 BSM_RT_WRN "Blind spot detection warning status";
BA_ "FlexKomIsMotorola" SG_ 720 BSM_RT_WRN 1;
BA_ "FlexKomSID" SG_ 720 BSM_RT_WRN 9;
BA_ "FlexKomSigLaenge" SG_ 720 BSM_RT_WRN 6;
BA_ "FlexKomSigName" SG_ 720 BSM_RT_WRN "BSM_WRN";
BA_ "FlexKomSigStartPos" SG_ 720 BSM_RT_WRN 5;
BA_ "FlexKomSigStartValue" SG_ 720 BSM_RT_WRN "00h";
BA_ "GenSigCycleTime" SG_ 720 BSM_RT_WRN 500;
BA_ "GenSigSendType" SG_ 720 BSM_RT_WRN 5;
BA_ "GenSigSNA" SG_ 720 BSM_RT_WRN "7h";
BA_ "GenSigTimeout_HaLF" SG_ 720 BSM_RT_WRN 5250;
BA_ "GenSigTimeout_IC" SG_ 720 BSM_RT_WRN 5250;
BA_ "RID" SG_ 720 BSM_RT_WRN "1169";
BA_ "FlexKomComment" SG_ 720 BSM_SRV_RQ "BSM service warning request; 1= service request";
BA_ "FlexKomIsMotorola" SG_ 720 BSM_SRV_RQ 1;
BA_ "FlexKomSID" SG_ 720 BSM_SRV_RQ 6;
BA_ "FlexKomSigLaenge" SG_ 720 BSM_SRV_RQ 1;
BA_ "FlexKomSigName" SG_ 720 BSM_SRV_RQ "BSM_SRV_RQ";
BA_ "FlexKomSigStartPos" SG_ 720 BSM_SRV_RQ 10;
BA_ "FlexKomSigStartValue" SG_ 720 BSM_SRV_RQ "00h";
BA_ "GenSigCycleTime" SG_ 720 BSM_SRV_RQ 500;
BA_ "GenSigSendType" SG_ 720 BSM_SRV_RQ 5;
BA_ "GenSigSNA" SG_ 720 BSM_SRV_RQ "0h";
BA_ "GenSigTimeout_HaLF" SG_ 720 BSM_SRV_RQ 5250;
BA_ "GenSigTimeout_IC" SG_ 720 BSM_SRV_RQ 5250;
BA_ "RID" SG_ 720 BSM_SRV_RQ "1242";
BA_ "FlexKomComment" SG_ 820 AHB_ACT "Automatic high beam active";
BA_ "FlexKomIsMotorola" SG_ 820 AHB_ACT 1;
BA_ "FlexKomSID" SG_ 820 AHB_ACT 732;
BA_ "FlexKomSigLaenge" SG_ 820 AHB_ACT 1;
BA_ "FlexKomSigName" SG_ 820 AHB_ACT "AHB_ACT";
BA_ "FlexKomSigStartPos" SG_ 820 AHB_ACT 14;
BA_ "FlexKomSigStartValue" SG_ 820 AHB_ACT "00h";
BA_ "GenSigCycleTime" SG_ 820 AHB_ACT 1000;
BA_ "GenSigSendType" SG_ 820 AHB_ACT 5;
BA_ "GenSigSNA" SG_ 820 AHB_ACT "0h";
BA_ "GenSigTimeout_IC" SG_ 820 AHB_ACT 10500;
BA_ "RID" SG_ 820 AHB_ACT "971";
BA_ "FlexKomComment" SG_ 820 BRK_FLUID_LO "Low brake fluid warning; low = [1]";
BA_ "FlexKomIsMotorola" SG_ 820 BRK_FLUID_LO 1;
BA_ "FlexKomSID" SG_ 820 BRK_FLUID_LO 885;
BA_ "FlexKomSigLaenge" SG_ 820 BRK_FLUID_LO 1;
BA_ "FlexKomSigName" SG_ 820 BRK_FLUID_LO "BRK_FLUID_LO";
BA_ "FlexKomSigStartPos" SG_ 820 BRK_FLUID_LO 62;
BA_ "FlexKomSigStartValue" SG_ 820 BRK_FLUID_LO "00h";
BA_ "GenSigCycleTime" SG_ 820 BRK_FLUID_LO 1000;
BA_ "GenSigSendType" SG_ 820 BRK_FLUID_LO 5;
BA_ "GenSigSNA" SG_ 820 BRK_FLUID_LO "0h";
BA_ "GenSigTimeout_ETM" SG_ 820 BRK_FLUID_LO 10500;
BA_ "GenSigTimeout_IC" SG_ 820 BRK_FLUID_LO 10500;
BA_ "FlexKomComment" SG_ 820 DAY_LGT_MD "Interior lighting status powertrain";
BA_ "FlexKomIsMotorola" SG_ 820 DAY_LGT_MD 1;
BA_ "FlexKomSID" SG_ 820 DAY_LGT_MD 1417;
BA_ "FlexKomSigLaenge" SG_ 820 DAY_LGT_MD 24;
BA_ "FlexKomSigName" SG_ 820 DAY_LGT_MD "IntLtSt_PT";
BA_ "FlexKomSigStartPos" SG_ 820 DAY_LGT_MD 47;
BA_ "FlexKomSigStartValue" SG_ 820 DAY_LGT_MD "000000h";
BA_ "GenSigCycleTime" SG_ 820 DAY_LGT_MD 1000;
BA_ "GenSigSendType" SG_ 820 DAY_LGT_MD 5;
BA_ "GenSigSNA" SG_ 820 DAY_LGT_MD "0h";
BA_ "GenSigTimeout_RHSC2" SG_ 820 DAY_LGT_MD 10500;
BA_ "GenSigTimeout_IC" SG_ 820 DAY_LGT_MD 10500;
BA_ "GenSigTimeout_RF_HUB" SG_ 820 DAY_LGT_MD 10500;
BA_ "GenSigTimeout_SCCM" SG_ 820 DAY_LGT_MD 10500;
BA_ "RID" SG_ 820 DAY_LGT_MD "9743";
BA_ "FlexKomComment" SG_ 820 DRV_AJAR "Door ajar";
BA_ "FlexKomIsMotorola" SG_ 820 DRV_AJAR 1;
BA_ "FlexKomSID" SG_ 820 DRV_AJAR 797;
BA_ "FlexKomSigLaenge" SG_ 820 DRV_AJAR 6;
BA_ "FlexKomSigName" SG_ 820 DRV_AJAR "DR_AJAR";
BA_ "FlexKomSigStartPos" SG_ 820 DRV_AJAR 22;
BA_ "FlexKomSigStartValue" SG_ 820 DRV_AJAR "00h";
BA_ "GenSigCycleTime" SG_ 820 DRV_AJAR 1000;
BA_ "GenSigSendType" SG_ 820 DRV_AJAR 5;
BA_ "GenSigSNA" SG_ 820 DRV_AJAR "0h";
BA_ "GenSigTimeout_IC" SG_ 820 DRV_AJAR 10500;
BA_ "GenSigTimeout_RF_HUB" SG_ 820 DRV_AJAR 10500;
BA_ "FlexKomComment" SG_ 820 DR_LK_STAT "Door lock status";
BA_ "FlexKomIsMotorola" SG_ 820 DR_LK_STAT 1;
BA_ "FlexKomSID" SG_ 820 DR_LK_STAT 861;
BA_ "FlexKomSigLaenge" SG_ 820 DR_LK_STAT 2;
BA_ "FlexKomSigName" SG_ 820 DR_LK_STAT "DR_LK_STAT";
BA_ "FlexKomSigStartPos" SG_ 820 DR_LK_STAT 6;
BA_ "FlexKomSigStartValue" SG_ 820 DR_LK_STAT "03h";
BA_ "GenSigCycleTime" SG_ 820 DR_LK_STAT 1000;
BA_ "GenSigSendType" SG_ 820 DR_LK_STAT 5;
BA_ "GenSigSNA" SG_ 820 DR_LK_STAT "3h";
BA_ "GenSigStartValue" SG_ 820 DR_LK_STAT 3;
BA_ "GenSigTimeout_IC" SG_ 820 DR_LK_STAT 10500;
BA_ "GenSigTimeout_RF_HUB" SG_ 820 DR_LK_STAT 10500;
BA_ "FlexKomComment" SG_ 820 FOB_SrchRq "FOB search request";
BA_ "FlexKomIsMotorola" SG_ 820 FOB_SrchRq 1;
BA_ "FlexKomSID" SG_ 820 FOB_SrchRq 1392;
BA_ "FlexKomSigLaenge" SG_ 820 FOB_SrchRq 2;
BA_ "FlexKomSigName" SG_ 820 FOB_SrchRq "FOB_SrchRq";
BA_ "FlexKomSigStartPos" SG_ 820 FOB_SrchRq 9;
BA_ "FlexKomSigStartValue" SG_ 820 FOB_SrchRq "00h";
BA_ "GenSigCycleTime" SG_ 820 FOB_SrchRq 1000;
BA_ "GenSigSendType" SG_ 820 FOB_SrchRq 5;
BA_ "GenSigSNA" SG_ 820 FOB_SrchRq "0h";
BA_ "GenSigTimeout_RF_HUB" SG_ 820 FOB_SrchRq 5500;
BA_ "FlexKomComment" SG_ 820 FT_FOG_RQ "Front fog request; off=[0], on=[1]";
BA_ "FlexKomIsMotorola" SG_ 820 FT_FOG_RQ 1;
BA_ "FlexKomSID" SG_ 820 FT_FOG_RQ 758;
BA_ "FlexKomSigLaenge" SG_ 820 FT_FOG_RQ 1;
BA_ "FlexKomSigName" SG_ 820 FT_FOG_RQ "FT_FOG_RQ";
BA_ "FlexKomSigStartPos" SG_ 820 FT_FOG_RQ 2;
BA_ "FlexKomSigStartValue" SG_ 820 FT_FOG_RQ "00h";
BA_ "GenSigCycleTime" SG_ 820 FT_FOG_RQ 1000;
BA_ "GenSigSendType" SG_ 820 FT_FOG_RQ 5;
BA_ "GenSigSNA" SG_ 820 FT_FOG_RQ "0h";
BA_ "GenSigTimeout_IC" SG_ 820 FT_FOG_RQ 10500;
BA_ "FlexKomComment" SG_ 820 FT_WPR_NOT_PRK "Front wiper outside park position";
BA_ "FlexKomIsMotorola" SG_ 820 FT_WPR_NOT_PRK 1;
BA_ "FlexKomSID" SG_ 820 FT_WPR_NOT_PRK 1046;
BA_ "FlexKomSigLaenge" SG_ 820 FT_WPR_NOT_PRK 1;
BA_ "FlexKomSigName" SG_ 820 FT_WPR_NOT_PRK "FT_WPR_NOT_PRK";
BA_ "FlexKomSigStartPos" SG_ 820 FT_WPR_NOT_PRK 56;
BA_ "FlexKomSigStartValue" SG_ 820 FT_WPR_NOT_PRK "00h";
BA_ "GenSigCycleTime" SG_ 820 FT_WPR_NOT_PRK 1000;
BA_ "GenSigSendType" SG_ 820 FT_WPR_NOT_PRK 5;
BA_ "GenSigSNA" SG_ 820 FT_WPR_NOT_PRK "0h";
BA_ "FlexKomComment" SG_ 820 HIBEAM_ON "High beam is on; off=[0], on=[1]";
BA_ "FlexKomIsMotorola" SG_ 820 HIBEAM_ON 1;
BA_ "FlexKomSID" SG_ 820 HIBEAM_ON 884;
BA_ "FlexKomSigLaenge" SG_ 820 HIBEAM_ON 1;
BA_ "FlexKomSigName" SG_ 820 HIBEAM_ON "HIBEAM_ON";
BA_ "FlexKomSigStartPos" SG_ 820 HIBEAM_ON 58;
BA_ "FlexKomSigStartValue" SG_ 820 HIBEAM_ON "00h";
BA_ "GenSigCycleTime" SG_ 820 HIBEAM_ON 1000;
BA_ "GenSigSendType" SG_ 820 HIBEAM_ON 5;
BA_ "GenSigSNA" SG_ 820 HIBEAM_ON "0h";
BA_ "GenSigTimeout_IC" SG_ 820 HIBEAM_ON 10500;
BA_ "FlexKomComment" SG_ 820 IGN_OFF_TIME_LNG "Time since last ignition on (long)";
BA_ "FlexKomIsMotorola" SG_ 820 IGN_OFF_TIME_LNG 1;
BA_ "FlexKomSID" SG_ 820 IGN_OFF_TIME_LNG 998;
BA_ "FlexKomSigLaenge" SG_ 820 IGN_OFF_TIME_LNG 16;
BA_ "FlexKomSigName" SG_ 820 IGN_OFF_TIME_LNG "IGN_OFF_TIME_LNG";
BA_ "FlexKomSigStartPos" SG_ 820 IGN_OFF_TIME_LNG 31;
BA_ "FlexKomSigStartValue" SG_ 820 IGN_OFF_TIME_LNG "0FFFh";
BA_ "GenSigCycleTime" SG_ 820 IGN_OFF_TIME_LNG 1000;
BA_ "GenSigSendType" SG_ 820 IGN_OFF_TIME_LNG 5;
BA_ "GenSigSNA" SG_ 820 IGN_OFF_TIME_LNG "FFFh";
BA_ "GenSigStartValue" SG_ 820 IGN_OFF_TIME_LNG 4095;
BA_ "GenSigTimeout_IC" SG_ 820 IGN_OFF_TIME_LNG 10500;
BA_ "GenSigTimeout_RF_HUB" SG_ 820 IGN_OFF_TIME_LNG 10500;
BA_ "FlexKomComment" SG_ 820 LOBEAM_ON "Low beam is on; off=[0], on=[1]";
BA_ "FlexKomIsMotorola" SG_ 820 LOBEAM_ON 1;
BA_ "FlexKomSID" SG_ 820 LOBEAM_ON 883;
BA_ "FlexKomSigLaenge" SG_ 820 LOBEAM_ON 1;
BA_ "FlexKomSigName" SG_ 820 LOBEAM_ON "LOBEAM_ON";
BA_ "FlexKomSigStartPos" SG_ 820 LOBEAM_ON 57;
BA_ "FlexKomSigStartValue" SG_ 820 LOBEAM_ON "00h";
BA_ "GenSigCycleTime" SG_ 820 LOBEAM_ON 1000;
BA_ "GenSigSendType" SG_ 820 LOBEAM_ON 5;
BA_ "GenSigSNA" SG_ 820 LOBEAM_ON "0h";
BA_ "GenSigTimeout_IC" SG_ 820 LOBEAM_ON 10500;
BA_ "FlexKomComment" SG_ 820 L_R_AJAR "Door ajar";
BA_ "FlexKomIsMotorola" SG_ 820 L_R_AJAR 1;
BA_ "FlexKomSID" SG_ 820 L_R_AJAR 797;
BA_ "FlexKomSigLaenge" SG_ 820 L_R_AJAR 6;
BA_ "FlexKomSigName" SG_ 820 L_R_AJAR "DR_AJAR";
BA_ "FlexKomSigStartPos" SG_ 820 L_R_AJAR 22;
BA_ "FlexKomSigStartValue" SG_ 820 L_R_AJAR "00h";
BA_ "GenSigCycleTime" SG_ 820 L_R_AJAR 1000;
BA_ "GenSigSendType" SG_ 820 L_R_AJAR 5;
BA_ "GenSigSNA" SG_ 820 L_R_AJAR "0h";
BA_ "GenSigTimeout_IC" SG_ 820 L_R_AJAR 10500;
BA_ "GenSigTimeout_RF_HUB" SG_ 820 L_R_AJAR 10500;
BA_ "FlexKomComment" SG_ 820 PANEL_INTS "Interior lighting status powertrain";
BA_ "FlexKomIsMotorola" SG_ 820 PANEL_INTS 1;
BA_ "FlexKomSID" SG_ 820 PANEL_INTS 1417;
BA_ "FlexKomSigLaenge" SG_ 820 PANEL_INTS 24;
BA_ "FlexKomSigName" SG_ 820 PANEL_INTS "IntLtSt_PT";
BA_ "FlexKomSigStartPos" SG_ 820 PANEL_INTS 47;
BA_ "FlexKomSigStartValue" SG_ 820 PANEL_INTS "000000h";
BA_ "GenSigCycleTime" SG_ 820 PANEL_INTS 1000;
BA_ "GenSigSendType" SG_ 820 PANEL_INTS 5;
BA_ "GenSigSNA" SG_ 820 PANEL_INTS "FFh";
BA_ "GenSigTimeout_RHSC2" SG_ 820 PANEL_INTS 10500;
BA_ "GenSigTimeout_IC" SG_ 820 PANEL_INTS 10500;
BA_ "GenSigTimeout_RF_HUB" SG_ 820 PANEL_INTS 10500;
BA_ "GenSigTimeout_SCCM" SG_ 820 PANEL_INTS 10500;
BA_ "RID" SG_ 820 PANEL_INTS "9744";
BA_ "FlexKomComment" SG_ 820 PARK_LMP_ON "Parklamps are on; off=[0], on=[1]";
BA_ "FlexKomIsMotorola" SG_ 820 PARK_LMP_ON 1;
BA_ "FlexKomSID" SG_ 820 PARK_LMP_ON 767;
BA_ "FlexKomSigLaenge" SG_ 820 PARK_LMP_ON 1;
BA_ "FlexKomSigName" SG_ 820 PARK_LMP_ON "PARK_LMP_ON";
BA_ "FlexKomSigStartPos" SG_ 820 PARK_LMP_ON 16;
BA_ "FlexKomSigStartValue" SG_ 820 PARK_LMP_ON "00h";
BA_ "GenSigCycleTime" SG_ 820 PARK_LMP_ON 1000;
BA_ "GenSigSendType" SG_ 820 PARK_LMP_ON 5;
BA_ "GenSigSNA" SG_ 820 PARK_LMP_ON "0h";
BA_ "GenSigTimeout_IC" SG_ 820 PARK_LMP_ON 10500;
BA_ "FlexKomComment" SG_ 820 PSG_AJAR "Door ajar";
BA_ "FlexKomIsMotorola" SG_ 820 PSG_AJAR 1;
BA_ "FlexKomSID" SG_ 820 PSG_AJAR 797;
BA_ "FlexKomSigLaenge" SG_ 820 PSG_AJAR 6;
BA_ "FlexKomSigName" SG_ 820 PSG_AJAR "DR_AJAR";
BA_ "FlexKomSigStartPos" SG_ 820 PSG_AJAR 22;
BA_ "FlexKomSigStartValue" SG_ 820 PSG_AJAR "00h";
BA_ "GenSigCycleTime" SG_ 820 PSG_AJAR 1000;
BA_ "GenSigSendType" SG_ 820 PSG_AJAR 5;
BA_ "GenSigSNA" SG_ 820 PSG_AJAR "0h";
BA_ "GenSigTimeout_IC" SG_ 820 PSG_AJAR 10500;
BA_ "GenSigTimeout_ORC" SG_ 820 PSG_AJAR 3500;
BA_ "GenSigTimeout_RF_HUB" SG_ 820 PSG_AJAR 10500;
BA_ "FlexKomComment" SG_ 820 REV_GEAR "Reverse Gear (manual trans)";
BA_ "FlexKomIsMotorola" SG_ 820 REV_GEAR 1;
BA_ "FlexKomSID" SG_ 820 REV_GEAR 685;
BA_ "FlexKomSigLaenge" SG_ 820 REV_GEAR 1;
BA_ "FlexKomSigName" SG_ 820 REV_GEAR "REV_GEAR";
BA_ "FlexKomSigStartPos" SG_ 820 REV_GEAR 4;
BA_ "FlexKomSigStartValue" SG_ 820 REV_GEAR "00h";
BA_ "GenSigCycleTime" SG_ 820 REV_GEAR 1000;
BA_ "GenSigSendType" SG_ 820 REV_GEAR 5;
BA_ "GenSigSNA" SG_ 820 REV_GEAR "0h";
BA_ "GenSigTimeout_IC" SG_ 820 REV_GEAR 10500;
BA_ "GenSigTimeout_ORC" SG_ 820 REV_GEAR 3500;
BA_ "GenSigTimeout_PTS" SG_ 820 REV_GEAR 3500;
BA_ "GenSigTimeout_RF_HUB" SG_ 820 REV_GEAR 10500;
BA_ "RID" SG_ 820 REV_GEAR "9766";
BA_ "FlexKomComment" SG_ 820 R_FOG_RQ "Rear fog request; [0] = off, [1] = on";
BA_ "FlexKomIsMotorola" SG_ 820 R_FOG_RQ 1;
BA_ "FlexKomSID" SG_ 820 R_FOG_RQ 427;
BA_ "FlexKomSigLaenge" SG_ 820 R_FOG_RQ 1;
BA_ "FlexKomSigName" SG_ 820 R_FOG_RQ "R_FOG_RQ";
BA_ "FlexKomSigStartPos" SG_ 820 R_FOG_RQ 3;
BA_ "FlexKomSigStartValue" SG_ 820 R_FOG_RQ "00h";
BA_ "GenSigCycleTime" SG_ 820 R_FOG_RQ 1000;
BA_ "GenSigSendType" SG_ 820 R_FOG_RQ 5;
BA_ "GenSigSNA" SG_ 820 R_FOG_RQ "0h";
BA_ "GenSigTimeout_IC" SG_ 820 R_FOG_RQ 10500;
BA_ "FlexKomComment" SG_ 820 R_R_AJAR "Door ajar";
BA_ "FlexKomIsMotorola" SG_ 820 R_R_AJAR 1;
BA_ "FlexKomSID" SG_ 820 R_R_AJAR 797;
BA_ "FlexKomSigLaenge" SG_ 820 R_R_AJAR 6;
BA_ "FlexKomSigName" SG_ 820 R_R_AJAR "DR_AJAR";
BA_ "FlexKomSigStartPos" SG_ 820 R_R_AJAR 22;
BA_ "FlexKomSigStartValue" SG_ 820 R_R_AJAR "00h";
BA_ "GenSigCycleTime" SG_ 820 R_R_AJAR 1000;
BA_ "GenSigSendType" SG_ 820 R_R_AJAR 5;
BA_ "GenSigSNA" SG_ 820 R_R_AJAR "0h";
BA_ "GenSigTimeout_IC" SG_ 820 R_R_AJAR 10500;
BA_ "GenSigTimeout_RF_HUB" SG_ 820 R_R_AJAR 10500;
BA_ "FlexKomComment" SG_ 820 SHIP_STAT "Shipping status";
BA_ "FlexKomIsMotorola" SG_ 820 SHIP_STAT 1;
BA_ "FlexKomSID" SG_ 820 SHIP_STAT 869;
BA_ "FlexKomSigLaenge" SG_ 820 SHIP_STAT 2;
BA_ "FlexKomSigName" SG_ 820 SHIP_STAT "SHIP_STAT";
BA_ "FlexKomSigStartPos" SG_ 820 SHIP_STAT 29;
BA_ "FlexKomSigStartValue" SG_ 820 SHIP_STAT "03h";
BA_ "GenSigCycleTime" SG_ 820 SHIP_STAT 1000;
BA_ "GenSigSendType" SG_ 820 SHIP_STAT 5;
BA_ "GenSigSNA" SG_ 820 SHIP_STAT "3h";
BA_ "GenSigStartValue" SG_ 820 SHIP_STAT 3;
BA_ "GenSigTimeout_IC" SG_ 820 SHIP_STAT 10500;
BA_ "GenSigTimeout_ORC" SG_ 820 SHIP_STAT 3500;
BA_ "GenSigTimeout_RF_HUB" SG_ 820 SHIP_STAT 10500;
BA_ "FlexKomComment" SG_ 820 TLG_AJAR "Door ajar";
BA_ "FlexKomIsMotorola" SG_ 820 TLG_AJAR 1;
BA_ "FlexKomSID" SG_ 820 TLG_AJAR 797;
BA_ "FlexKomSigLaenge" SG_ 820 TLG_AJAR 6;
BA_ "FlexKomSigName" SG_ 820 TLG_AJAR "DR_AJAR";
BA_ "FlexKomSigStartPos" SG_ 820 TLG_AJAR 22;
BA_ "FlexKomSigStartValue" SG_ 820 TLG_AJAR "00h";
BA_ "GenSigCycleTime" SG_ 820 TLG_AJAR 1000;
BA_ "GenSigSendType" SG_ 820 TLG_AJAR 5;
BA_ "GenSigSNA" SG_ 820 TLG_AJAR "0h";
BA_ "GenSigTimeout_IC" SG_ 820 TLG_AJAR 10500;
BA_ "GenSigTimeout_RF_HUB" SG_ 820 TLG_AJAR 10500;
BA_ "FlexKomComment" SG_ 820 TurnInd_LT_ON "Turn indication status";
BA_ "FlexKomIsMotorola" SG_ 820 TurnInd_LT_ON 1;
BA_ "FlexKomSID" SG_ 820 TurnInd_LT_ON 759;
BA_ "FlexKomSigLaenge" SG_ 820 TurnInd_LT_ON 2;
BA_ "FlexKomSigName" SG_ 820 TurnInd_LT_ON "TurnInd_STAT";
BA_ "FlexKomSigStartPos" SG_ 820 TurnInd_LT_ON 31;
BA_ "FlexKomSigStartValue" SG_ 820 TurnInd_LT_ON "00h";
BA_ "GenSigCycleTime" SG_ 820 TurnInd_LT_ON 1000;
BA_ "GenSigSendType" SG_ 820 TurnInd_LT_ON 5;
BA_ "GenSigSNA" SG_ 820 TurnInd_LT_ON "0h";
BA_ "GenSigTimeout_IC" SG_ 820 TurnInd_LT_ON 10500;
BA_ "GenSigTimeout_PTS" SG_ 820 TurnInd_LT_ON 10500;
BA_ "FlexKomComment" SG_ 820 TurnInd_RT_ON "Turn indication status";
BA_ "FlexKomIsMotorola" SG_ 820 TurnInd_RT_ON 1;
BA_ "FlexKomSID" SG_ 820 TurnInd_RT_ON 759;
BA_ "FlexKomSigLaenge" SG_ 820 TurnInd_RT_ON 2;
BA_ "FlexKomSigName" SG_ 820 TurnInd_RT_ON "TurnInd_STAT";
BA_ "FlexKomSigStartPos" SG_ 820 TurnInd_RT_ON 31;
BA_ "FlexKomSigStartValue" SG_ 820 TurnInd_RT_ON "00h";
BA_ "GenSigCycleTime" SG_ 820 TurnInd_RT_ON 1000;
BA_ "GenSigSendType" SG_ 820 TurnInd_RT_ON 5;
BA_ "GenSigSNA" SG_ 820 TurnInd_RT_ON "0h";
BA_ "GenSigTimeout_IC" SG_ 820 TurnInd_RT_ON 10500;
BA_ "GenSigTimeout_PTS" SG_ 820 TurnInd_RT_ON 10500;
BA_ "FlexKomComment" SG_ 820 WASH_FLUID_LO "Low washer fluid warning (1=Fluid is low)";
BA_ "FlexKomIsMotorola" SG_ 820 WASH_FLUID_LO 1;
BA_ "FlexKomSID" SG_ 820 WASH_FLUID_LO 965;
BA_ "FlexKomSigLaenge" SG_ 820 WASH_FLUID_LO 1;
BA_ "FlexKomSigName" SG_ 820 WASH_FLUID_LO "WASH_FLUID_LO";
BA_ "FlexKomSigStartPos" SG_ 820 WASH_FLUID_LO 63;
BA_ "FlexKomSigStartValue" SG_ 820 WASH_FLUID_LO "00h";
BA_ "GenSigCycleTime" SG_ 820 WASH_FLUID_LO 1000;
BA_ "GenSigSendType" SG_ 820 WASH_FLUID_LO 5;
BA_ "GenSigSNA" SG_ 820 WASH_FLUID_LO "0h";
BA_ "GenSigTimeout_ETM" SG_ 820 WASH_FLUID_LO 10500;
BA_ "GenSigTimeout_IC" SG_ 820 WASH_FLUID_LO 10500;
BA_ "FlexKomComment" SG_ 274 CmdIgnStat "Vehicle start packet";
BA_ "FlexKomIsMotorola" SG_ 274 CmdIgnStat 1;
BA_ "FlexKomSID" SG_ 274 CmdIgnStat 880;
BA_ "FlexKomSigLaenge" SG_ 274 CmdIgnStat 16;
BA_ "FlexKomSigName" SG_ 274 CmdIgnStat "VehStart_PKT";
BA_ "FlexKomSigStartPos" SG_ 274 CmdIgnStat 7;
BA_ "FlexKomSigStartValue" SG_ 274 CmdIgnStat "0000h";
BA_ "GenSigCycleTime" SG_ 274 CmdIgnStat 20;
BA_ "GenSigSNA" SG_ 274 CmdIgnStat "7h";
BA_ "GenSigTimeout_EPS" SG_ 274 CmdIgnStat 210;
BA_ "GenSigTimeout_ESL" SG_ 274 CmdIgnStat 110;
BA_ "GenSigTimeout_IC" SG_ 274 CmdIgnStat 210;
BA_ "GenSigTimeout_ORC" SG_ 274 CmdIgnStat 70;
BA_ "GenSigTimeout_PTS" SG_ 274 CmdIgnStat 210;
BA_ "GenSigTimeout_SCCM" SG_ 274 CmdIgnStat 210;
BA_ "RID" SG_ 274 CmdIgnStat "9600";
BA_ "FlexKomComment" SG_ 274 KeyInIgn "Vehicle start packet";
BA_ "FlexKomIsMotorola" SG_ 274 KeyInIgn 1;
BA_ "FlexKomSID" SG_ 274 KeyInIgn 880;
BA_ "FlexKomSigLaenge" SG_ 274 KeyInIgn 16;
BA_ "FlexKomSigName" SG_ 274 KeyInIgn "VehStart_PKT";
BA_ "FlexKomSigStartPos" SG_ 274 KeyInIgn 7;
BA_ "FlexKomSigStartValue" SG_ 274 KeyInIgn "0000h";
BA_ "GenSigCycleTime" SG_ 274 KeyInIgn 20;
BA_ "GenSigSNA" SG_ 274 KeyInIgn "3h";
BA_ "GenSigTimeout_ESL" SG_ 274 KeyInIgn 110;
BA_ "GenSigTimeout_IC" SG_ 274 KeyInIgn 210;
BA_ "GenSigTimeout_ORC" SG_ 274 KeyInIgn 70;
BA_ "RID" SG_ 274 KeyInIgn "9745";
BA_ "FlexKomComment" SG_ 274 RemStActv "Vehicle start packet";
BA_ "FlexKomIsMotorola" SG_ 274 RemStActv 1;
BA_ "FlexKomSID" SG_ 274 RemStActv 880;
BA_ "FlexKomSigLaenge" SG_ 274 RemStActv 16;
BA_ "FlexKomSigName" SG_ 274 RemStActv "VehStart_PKT";
BA_ "FlexKomSigStartPos" SG_ 274 RemStActv 7;
BA_ "FlexKomSigStartValue" SG_ 274 RemStActv "0000h";
BA_ "GenSigCycleTime" SG_ 274 RemStActv 20;
BA_ "GenSigSNA" SG_ 274 RemStActv "0h";
BA_ "GenSigTimeout_IC" SG_ 274 RemStActv 210;
BA_ "GenSigTimeout_ORC" SG_ 274 RemStActv 70;
BA_ "RID" SG_ 274 RemStActv "9746";
BA_ "FlexKomComment" SG_ 274 StTyp "Vehicle start packet";
BA_ "FlexKomIsMotorola" SG_ 274 StTyp 1;
BA_ "FlexKomSID" SG_ 274 StTyp 880;
BA_ "FlexKomSigLaenge" SG_ 274 StTyp 16;
BA_ "FlexKomSigName" SG_ 274 StTyp "VehStart_PKT";
BA_ "FlexKomSigStartPos" SG_ 274 StTyp 7;
BA_ "FlexKomSigStartValue" SG_ 274 StTyp "0000h";
BA_ "GenSigCycleTime" SG_ 274 StTyp 20;
BA_ "GenSigSNA" SG_ 274 StTyp "7h";
BA_ "GenSigTimeout_IC" SG_ 274 StTyp 210;
BA_ "GenSigTimeout_ORC" SG_ 274 StTyp 70;
BA_ "FlexKomComment" SG_ 274 StartRelayBCMFault "CBC starter relay fault detected";
BA_ "FlexKomIsMotorola" SG_ 274 StartRelayBCMFault 1;
BA_ "FlexKomSID" SG_ 274 StartRelayBCMFault 1573;
BA_ "FlexKomSigLaenge" SG_ 274 StartRelayBCMFault 1;
BA_ "FlexKomSigName" SG_ 274 StartRelayBCMFault "StartRelayBCMFault";
BA_ "FlexKomSigStartPos" SG_ 274 StartRelayBCMFault 14;
BA_ "FlexKomSigStartValue" SG_ 274 StartRelayBCMFault "00h";
BA_ "GenSigCycleTime" SG_ 274 StartRelayBCMFault 20;
BA_ "GenSigSNA" SG_ 274 StartRelayBCMFault "0h";
BA_ "GenSigTimeout_ORC" SG_ 274 StartRelayBCMFault 70;
BA_ "FlexKomComment" SG_ 274 StartRelayBCMSts "CBC starter relay status; [1] = ON";
BA_ "FlexKomIsMotorola" SG_ 274 StartRelayBCMSts 1;
BA_ "FlexKomSID" SG_ 274 StartRelayBCMSts 1526;
BA_ "FlexKomSigLaenge" SG_ 274 StartRelayBCMSts 1;
BA_ "FlexKomSigName" SG_ 274 StartRelayBCMSts "StartRelayBCMSts";
BA_ "FlexKomSigStartPos" SG_ 274 StartRelayBCMSts 13;
BA_ "FlexKomSigStartValue" SG_ 274 StartRelayBCMSts "00h";
BA_ "GenSigCycleTime" SG_ 274 StartRelayBCMSts 20;
BA_ "GenSigSNA" SG_ 274 StartRelayBCMSts "0h";
BA_ "FlexKomComment" SG_ 274 TeenKeyPrsnt "Vehicle start packet";
BA_ "FlexKomIsMotorola" SG_ 274 TeenKeyPrsnt 1;
BA_ "FlexKomSID" SG_ 274 TeenKeyPrsnt 880;
BA_ "FlexKomSigLaenge" SG_ 274 TeenKeyPrsnt 16;
BA_ "FlexKomSigName" SG_ 274 TeenKeyPrsnt "VehStart_PKT";
BA_ "FlexKomSigStartPos" SG_ 274 TeenKeyPrsnt 7;
BA_ "FlexKomSigStartValue" SG_ 274 TeenKeyPrsnt "0000h";
BA_ "GenSigCycleTime" SG_ 274 TeenKeyPrsnt 20;
BA_ "GenSigSNA" SG_ 274 TeenKeyPrsnt "0h";
BA_ "GenSigTimeout_ETM" SG_ 274 TeenKeyPrsnt 210;
BA_ "GenSigTimeout_IC" SG_ 274 TeenKeyPrsnt 210;
BA_ "FlexKomComment" SG_ 512 AMB_TEMP_AVG "Averaged ambient temperature";
BA_ "FlexKomIsMotorola" SG_ 512 AMB_TEMP_AVG 1;
BA_ "FlexKomSID" SG_ 512 AMB_TEMP_AVG 840;
BA_ "FlexKomSigLaenge" SG_ 512 AMB_TEMP_AVG 16;
BA_ "FlexKomSigName" SG_ 512 AMB_TEMP_AVG "AMB_TEMP_AVG";
BA_ "FlexKomSigStartPos" SG_ 512 AMB_TEMP_AVG 15;
BA_ "FlexKomSigStartValue" SG_ 512 AMB_TEMP_AVG "FFFFh";
BA_ "GenSigCycleTime" SG_ 512 AMB_TEMP_AVG 100;
BA_ "GenSigSNA" SG_ 512 AMB_TEMP_AVG "FFFFh";
BA_ "GenSigStartValue" SG_ 512 AMB_TEMP_AVG 65535;
BA_ "GenSigTimeout_IC" SG_ 512 AMB_TEMP_AVG 1050;
BA_ "GenSigTimeout_ORC" SG_ 512 AMB_TEMP_AVG 350;
BA_ "GenSigTimeout_RF_HUB" SG_ 512 AMB_TEMP_AVG 1050;
BA_ "RID" SG_ 512 AMB_TEMP_AVG "9768";
BA_ "FlexKomComment" SG_ 512 AMB_TEMP_VOLT "Ambient Temp Sensor A/D Voltage";
BA_ "FlexKomIsMotorola" SG_ 512 AMB_TEMP_VOLT 1;
BA_ "FlexKomSID" SG_ 512 AMB_TEMP_VOLT 1201;
BA_ "FlexKomSigLaenge" SG_ 512 AMB_TEMP_VOLT 8;
BA_ "FlexKomSigName" SG_ 512 AMB_TEMP_VOLT "AMB_TEMP_VOLT";
BA_ "FlexKomSigStartPos" SG_ 512 AMB_TEMP_VOLT 31;
BA_ "FlexKomSigStartValue" SG_ 512 AMB_TEMP_VOLT "FFh";
BA_ "GenSigCycleTime" SG_ 512 AMB_TEMP_VOLT 100;
BA_ "GenSigSNA" SG_ 512 AMB_TEMP_VOLT "FFh";
BA_ "GenSigStartValue" SG_ 512 AMB_TEMP_VOLT 255;
BA_ "GenSigTimeout_ORC" SG_ 512 AMB_TEMP_VOLT 350;
BA_ "RID" SG_ 512 AMB_TEMP_VOLT "1805";
BA_ "FlexKomComment" SG_ 512 AirTemp_Outsd "Outside air temperature";
BA_ "FlexKomIsMotorola" SG_ 512 AirTemp_Outsd 1;
BA_ "FlexKomSID" SG_ 512 AirTemp_Outsd 773;
BA_ "FlexKomSigLaenge" SG_ 512 AirTemp_Outsd 8;
BA_ "FlexKomSigName" SG_ 512 AirTemp_Outsd "AirTemp_Outsd";
BA_ "FlexKomSigStartPos" SG_ 512 AirTemp_Outsd 7;
BA_ "FlexKomSigStartValue" SG_ 512 AirTemp_Outsd "FFh";
BA_ "GenSigCycleTime" SG_ 512 AirTemp_Outsd 100;
BA_ "GenSigSNA" SG_ 512 AirTemp_Outsd "FFh";
BA_ "GenSigStartValue" SG_ 512 AirTemp_Outsd 255;
BA_ "GenSigTimeout_IC" SG_ 512 AirTemp_Outsd 1050;
BA_ "GenSigTimeout_ORC" SG_ 512 AirTemp_Outsd 350;
BA_ "GenSigTimeout_RF_HUB" SG_ 512 AirTemp_Outsd 1050;
BA_ "RID" SG_ 512 AirTemp_Outsd "9767";
BA_ "FlexKomComment" SG_ 512 BATT_VOLT "System voltage";
BA_ "FlexKomIsMotorola" SG_ 512 BATT_VOLT 1;
BA_ "FlexKomSID" SG_ 512 BATT_VOLT 839;
BA_ "FlexKomSigLaenge" SG_ 512 BATT_VOLT 8;
BA_ "FlexKomSigName" SG_ 512 BATT_VOLT "BATT_VOLT";
BA_ "FlexKomSigStartPos" SG_ 512 BATT_VOLT 55;
BA_ "FlexKomSigStartValue" SG_ 512 BATT_VOLT "FFh";
BA_ "GenSigCycleTime" SG_ 512 BATT_VOLT 100;
BA_ "GenSigSNA" SG_ 512 BATT_VOLT "FFh";
BA_ "GenSigStartValue" SG_ 512 BATT_VOLT 255;
BA_ "GenSigTimeout_EPS" SG_ 512 BATT_VOLT 1050;
BA_ "GenSigTimeout_RHSC2" SG_ 512 BATT_VOLT 1050;
BA_ "GenSigTimeout_IC" SG_ 512 BATT_VOLT 1050;
BA_ "GenSigTimeout_ORC" SG_ 512 BATT_VOLT 350;
BA_ "GenSigTimeout_RF_HUB" SG_ 512 BATT_VOLT 1050;
BA_ "GenSigTimeout_SCCM" SG_ 512 BATT_VOLT 1050;
BA_ "RID" SG_ 512 BATT_VOLT "9601";
BA_ "FlexKomComment" SG_ 512 FUEL_VOLT "Fuel level A/D Voltage (Single tank OR Primary on ";
BA_ "FlexKomIsMotorola" SG_ 512 FUEL_VOLT 1;
BA_ "FlexKomSID" SG_ 512 FUEL_VOLT 881;
BA_ "FlexKomSigLaenge" SG_ 512 FUEL_VOLT 8;
BA_ "FlexKomSigName" SG_ 512 FUEL_VOLT "FUEL_VOLT";
BA_ "FlexKomSigStartPos" SG_ 512 FUEL_VOLT 39;
BA_ "FlexKomSigStartValue" SG_ 512 FUEL_VOLT "FFh";
BA_ "GenSigCycleTime" SG_ 512 FUEL_VOLT 100;
BA_ "GenSigSNA" SG_ 512 FUEL_VOLT "FFh";
BA_ "GenSigStartValue" SG_ 512 FUEL_VOLT 255;
BA_ "GenSigTimeout_IC" SG_ 512 FUEL_VOLT 1050;
BA_ "FlexKomComment" SG_ 804 ACC_DLY_ACT "Accessory Delay Active";
BA_ "FlexKomIsMotorola" SG_ 804 ACC_DLY_ACT 1;
BA_ "FlexKomSID" SG_ 804 ACC_DLY_ACT 841;
BA_ "FlexKomSigLaenge" SG_ 804 ACC_DLY_ACT 1;
BA_ "FlexKomSigName" SG_ 804 ACC_DLY_ACT "ACC_DLY_ACT";
BA_ "FlexKomSigStartPos" SG_ 804 ACC_DLY_ACT 26;
BA_ "FlexKomSigStartValue" SG_ 804 ACC_DLY_ACT "00h";
BA_ "GenSigCycleTime" SG_ 804 ACC_DLY_ACT 1000;
BA_ "GenSigSendType" SG_ 804 ACC_DLY_ACT 5;
BA_ "GenSigSNA" SG_ 804 ACC_DLY_ACT "0h";
BA_ "GenSigTimeout_IC" SG_ 804 ACC_DLY_ACT 10500;
BA_ "GenSigTimeout_SCCM" SG_ 804 ACC_DLY_ACT 10500;
BA_ "FlexKomComment" SG_ 804 ExteriorRearReleaseSwitchSts "Exterior rear release switch status";
BA_ "FlexKomIsMotorola" SG_ 804 ExteriorRearReleaseSwitchSts 1;
BA_ "FlexKomSID" SG_ 804 ExteriorRearReleaseSwitchSts 1846;
BA_ "FlexKomSigLaenge" SG_ 804 ExteriorRearReleaseSwitchSts 1;
BA_ "FlexKomSigName" SG_ 804 ExteriorRearReleaseSwitchSts "ExteriorRearReleaseSwitchSts";
BA_ "FlexKomSigStartPos" SG_ 804 ExteriorRearReleaseSwitchSts 21;
BA_ "FlexKomSigStartValue" SG_ 804 ExteriorRearReleaseSwitchSts "00h";
BA_ "GenSigCycleTime" SG_ 804 ExteriorRearReleaseSwitchSts 1000;
BA_ "GenSigSendType" SG_ 804 ExteriorRearReleaseSwitchSts 5;
BA_ "GenSigSNA" SG_ 804 ExteriorRearReleaseSwitchSts "0h";
BA_ "GenSigTimeout_RF_HUB" SG_ 804 ExteriorRearReleaseSwitchSts 10500;
BA_ "FlexKomComment" SG_ 804 HdAjar "Hood latch ajar, left or single (1=ajar)";
BA_ "FlexKomIsMotorola" SG_ 804 HdAjar 1;
BA_ "FlexKomSID" SG_ 804 HdAjar 1818;
BA_ "FlexKomSigLaenge" SG_ 804 HdAjar 1;
BA_ "FlexKomSigName" SG_ 804 HdAjar "HdAjar";
BA_ "FlexKomSigStartPos" SG_ 804 HdAjar 10;
BA_ "FlexKomSigStartValue" SG_ 804 HdAjar "01h";
BA_ "GenSigCycleTime" SG_ 804 HdAjar 1000;
BA_ "GenSigSendType" SG_ 804 HdAjar 5;
BA_ "GenSigSNA" SG_ 804 HdAjar "1h";
BA_ "GenSigStartValue" SG_ 804 HdAjar 1;
BA_ "GenSigTimeout_IC" SG_ 804 HdAjar 10500;
BA_ "FlexKomComment" SG_ 804 RemSt_Inhibit "Remote start inhibit";
BA_ "FlexKomIsMotorola" SG_ 804 RemSt_Inhibit 1;
BA_ "FlexKomSID" SG_ 804 RemSt_Inhibit 1047;
BA_ "FlexKomSigLaenge" SG_ 804 RemSt_Inhibit 8;
BA_ "FlexKomSigName" SG_ 804 RemSt_Inhibit "RemSt_Inhibit";
BA_ "FlexKomSigStartPos" SG_ 804 RemSt_Inhibit 39;
BA_ "FlexKomSigStartValue" SG_ 804 RemSt_Inhibit "00h";
BA_ "GenSigCycleTime" SG_ 804 RemSt_Inhibit 1000;
BA_ "GenSigSendType" SG_ 804 RemSt_Inhibit 5;
BA_ "GenSigSNA" SG_ 804 RemSt_Inhibit "FFh";
BA_ "GenSigTimeout_ETM" SG_ 804 RemSt_Inhibit 10500;
BA_ "GenSigTimeout_IC" SG_ 804 RemSt_Inhibit 10500;
BA_ "FlexKomComment" SG_ 804 TurnLmp_FL_Flt "Turn indication lamp front fault";
BA_ "FlexKomIsMotorola" SG_ 804 TurnLmp_FL_Flt 1;
BA_ "FlexKomSID" SG_ 804 TurnLmp_FL_Flt 973;
BA_ "FlexKomSigLaenge" SG_ 804 TurnLmp_FL_Flt 2;
BA_ "FlexKomSigName" SG_ 804 TurnLmp_FL_Flt "TurnLmp_F_Flt";
BA_ "FlexKomSigStartPos" SG_ 804 TurnLmp_FL_Flt 14;
BA_ "FlexKomSigStartValue" SG_ 804 TurnLmp_FL_Flt "00h";
BA_ "GenSigCycleTime" SG_ 804 TurnLmp_FL_Flt 1000;
BA_ "GenSigSendType" SG_ 804 TurnLmp_FL_Flt 5;
BA_ "GenSigSNA" SG_ 804 TurnLmp_FL_Flt "0h";
BA_ "GenSigTimeout_IC" SG_ 804 TurnLmp_FL_Flt 10500;
BA_ "FlexKomComment" SG_ 804 TurnLmp_FR_Flt "Turn indication lamp front fault";
BA_ "FlexKomIsMotorola" SG_ 804 TurnLmp_FR_Flt 1;
BA_ "FlexKomSID" SG_ 804 TurnLmp_FR_Flt 973;
BA_ "FlexKomSigLaenge" SG_ 804 TurnLmp_FR_Flt 2;
BA_ "FlexKomSigName" SG_ 804 TurnLmp_FR_Flt "TurnLmp_F_Flt";
BA_ "FlexKomSigStartPos" SG_ 804 TurnLmp_FR_Flt 14;
BA_ "FlexKomSigStartValue" SG_ 804 TurnLmp_FR_Flt "00h";
BA_ "GenSigCycleTime" SG_ 804 TurnLmp_FR_Flt 1000;
BA_ "GenSigSendType" SG_ 804 TurnLmp_FR_Flt 5;
BA_ "GenSigSNA" SG_ 804 TurnLmp_FR_Flt "0h";
BA_ "GenSigTimeout_IC" SG_ 804 TurnLmp_FR_Flt 10500;
BA_ "FlexKomComment" SG_ 804 TurnLmp_RL_Flt "Turn indication lamp rear fault";
BA_ "FlexKomIsMotorola" SG_ 804 TurnLmp_RL_Flt 1;
BA_ "FlexKomSID" SG_ 804 TurnLmp_RL_Flt 1033;
BA_ "FlexKomSigLaenge" SG_ 804 TurnLmp_RL_Flt 2;
BA_ "FlexKomSigName" SG_ 804 TurnLmp_RL_Flt "TurnLmp_R_Flt";
BA_ "FlexKomSigStartPos" SG_ 804 TurnLmp_RL_Flt 25;
BA_ "FlexKomSigStartValue" SG_ 804 TurnLmp_RL_Flt "00h";
BA_ "GenSigCycleTime" SG_ 804 TurnLmp_RL_Flt 1000;
BA_ "GenSigSendType" SG_ 804 TurnLmp_RL_Flt 5;
BA_ "GenSigSNA" SG_ 804 TurnLmp_RL_Flt "0h";
BA_ "GenSigTimeout_IC" SG_ 804 TurnLmp_RL_Flt 10500;
BA_ "FlexKomComment" SG_ 804 TurnLmp_RR_Flt "Turn indication lamp rear fault";
BA_ "FlexKomIsMotorola" SG_ 804 TurnLmp_RR_Flt 1;
BA_ "FlexKomSID" SG_ 804 TurnLmp_RR_Flt 1033;
BA_ "FlexKomSigLaenge" SG_ 804 TurnLmp_RR_Flt 2;
BA_ "FlexKomSigName" SG_ 804 TurnLmp_RR_Flt "TurnLmp_R_Flt";
BA_ "FlexKomSigStartPos" SG_ 804 TurnLmp_RR_Flt 25;
BA_ "FlexKomSigStartValue" SG_ 804 TurnLmp_RR_Flt "00h";
BA_ "GenSigCycleTime" SG_ 804 TurnLmp_RR_Flt 1000;
BA_ "GenSigSendType" SG_ 804 TurnLmp_RR_Flt 5;
BA_ "GenSigSNA" SG_ 804 TurnLmp_RR_Flt "0h";
BA_ "GenSigTimeout_IC" SG_ 804 TurnLmp_RR_Flt 10500;
BA_ "FlexKomComment" SG_ 804 WPR_SYS_AUTO "Wiper System Status";
BA_ "FlexKomIsMotorola" SG_ 804 WPR_SYS_AUTO 1;
BA_ "FlexKomSID" SG_ 804 WPR_SYS_AUTO 1048;
BA_ "FlexKomSigLaenge" SG_ 804 WPR_SYS_AUTO 8;
BA_ "FlexKomSigName" SG_ 804 WPR_SYS_AUTO "WPR_SYS_STAT";
BA_ "FlexKomSigStartPos" SG_ 804 WPR_SYS_AUTO 47;
BA_ "FlexKomSigStartValue" SG_ 804 WPR_SYS_AUTO "01h";
BA_ "GenSigCycleTime" SG_ 804 WPR_SYS_AUTO 1000;
BA_ "GenSigSNA" SG_ 804 WPR_SYS_AUTO "0h";
BA_ "FlexKomComment" SG_ 804 WPR_SYS_FLT "Wiper System Status";
BA_ "FlexKomIsMotorola" SG_ 804 WPR_SYS_FLT 1;
BA_ "FlexKomSID" SG_ 804 WPR_SYS_FLT 1048;
BA_ "FlexKomSigLaenge" SG_ 804 WPR_SYS_FLT 8;
BA_ "FlexKomSigName" SG_ 804 WPR_SYS_FLT "WPR_SYS_STAT";
BA_ "FlexKomSigStartPos" SG_ 804 WPR_SYS_FLT 47;
BA_ "FlexKomSigStartValue" SG_ 804 WPR_SYS_FLT "01h";
BA_ "GenSigCycleTime" SG_ 804 WPR_SYS_FLT 1000;
BA_ "GenSigSNA" SG_ 804 WPR_SYS_FLT "0h";
BA_ "FlexKomComment" SG_ 804 WPR_SYS_HIGH "Wiper System Status";
BA_ "FlexKomIsMotorola" SG_ 804 WPR_SYS_HIGH 1;
BA_ "FlexKomSID" SG_ 804 WPR_SYS_HIGH 1048;
BA_ "FlexKomSigLaenge" SG_ 804 WPR_SYS_HIGH 8;
BA_ "FlexKomSigName" SG_ 804 WPR_SYS_HIGH "WPR_SYS_STAT";
BA_ "FlexKomSigStartPos" SG_ 804 WPR_SYS_HIGH 47;
BA_ "FlexKomSigStartValue" SG_ 804 WPR_SYS_HIGH "01h";
BA_ "GenSigCycleTime" SG_ 804 WPR_SYS_HIGH 1000;
BA_ "GenSigSNA" SG_ 804 WPR_SYS_HIGH "0h";
BA_ "FlexKomComment" SG_ 804 WPR_SYS_INT "Wiper System Status";
BA_ "FlexKomIsMotorola" SG_ 804 WPR_SYS_INT 1;
BA_ "FlexKomSID" SG_ 804 WPR_SYS_INT 1048;
BA_ "FlexKomSigLaenge" SG_ 804 WPR_SYS_INT 8;
BA_ "FlexKomSigName" SG_ 804 WPR_SYS_INT "WPR_SYS_STAT";
BA_ "FlexKomSigStartPos" SG_ 804 WPR_SYS_INT 47;
BA_ "FlexKomSigStartValue" SG_ 804 WPR_SYS_INT "01h";
BA_ "GenSigCycleTime" SG_ 804 WPR_SYS_INT 1000;
BA_ "GenSigSNA" SG_ 804 WPR_SYS_INT "0h";
BA_ "FlexKomComment" SG_ 804 WPR_SYS_LOW "Wiper System Status";
BA_ "FlexKomIsMotorola" SG_ 804 WPR_SYS_LOW 1;
BA_ "FlexKomSID" SG_ 804 WPR_SYS_LOW 1048;
BA_ "FlexKomSigLaenge" SG_ 804 WPR_SYS_LOW 8;
BA_ "FlexKomSigName" SG_ 804 WPR_SYS_LOW "WPR_SYS_STAT";
BA_ "FlexKomSigStartPos" SG_ 804 WPR_SYS_LOW 47;
BA_ "FlexKomSigStartValue" SG_ 804 WPR_SYS_LOW "01h";
BA_ "GenSigCycleTime" SG_ 804 WPR_SYS_LOW 1000;
BA_ "GenSigSNA" SG_ 804 WPR_SYS_LOW "0h";
BA_ "FlexKomComment" SG_ 804 WPR_SYS_MIST "Wiper System Status";
BA_ "FlexKomIsMotorola" SG_ 804 WPR_SYS_MIST 1;
BA_ "FlexKomSID" SG_ 804 WPR_SYS_MIST 1048;
BA_ "FlexKomSigLaenge" SG_ 804 WPR_SYS_MIST 8;
BA_ "FlexKomSigName" SG_ 804 WPR_SYS_MIST "WPR_SYS_STAT";
BA_ "FlexKomSigStartPos" SG_ 804 WPR_SYS_MIST 47;
BA_ "FlexKomSigStartValue" SG_ 804 WPR_SYS_MIST "01h";
BA_ "GenSigCycleTime" SG_ 804 WPR_SYS_MIST 1000;
BA_ "GenSigSNA" SG_ 804 WPR_SYS_MIST "0h";
BA_ "FlexKomComment" SG_ 804 WPR_SYS_OFF "Wiper System Status";
BA_ "FlexKomIsMotorola" SG_ 804 WPR_SYS_OFF 1;
BA_ "FlexKomSID" SG_ 804 WPR_SYS_OFF 1048;
BA_ "FlexKomSigLaenge" SG_ 804 WPR_SYS_OFF 8;
BA_ "FlexKomSigName" SG_ 804 WPR_SYS_OFF "WPR_SYS_STAT";
BA_ "FlexKomSigStartPos" SG_ 804 WPR_SYS_OFF 47;
BA_ "FlexKomSigStartValue" SG_ 804 WPR_SYS_OFF "01h";
BA_ "GenSigCycleTime" SG_ 804 WPR_SYS_OFF 1000;
BA_ "GenSigSNA" SG_ 804 WPR_SYS_OFF "1h";
BA_ "GenSigStartValue" SG_ 804 WPR_SYS_OFF 1;
BA_ "FlexKomComment" SG_ 804 WPR_SYS_WASH "Wiper System Status";
BA_ "FlexKomIsMotorola" SG_ 804 WPR_SYS_WASH 1;
BA_ "FlexKomSID" SG_ 804 WPR_SYS_WASH 1048;
BA_ "FlexKomSigLaenge" SG_ 804 WPR_SYS_WASH 8;
BA_ "FlexKomSigName" SG_ 804 WPR_SYS_WASH "WPR_SYS_STAT";
BA_ "FlexKomSigStartPos" SG_ 804 WPR_SYS_WASH 47;
BA_ "FlexKomSigStartValue" SG_ 804 WPR_SYS_WASH "01h";
BA_ "GenSigCycleTime" SG_ 804 WPR_SYS_WASH 1000;
BA_ "GenSigSNA" SG_ 804 WPR_SYS_WASH "0h";
BA_ "FlexKomComment" SG_ 788 CFG_FEATURE "Configurable display request - from CAN C";
BA_ "FlexKomIsMotorola" SG_ 788 CFG_FEATURE 1;
BA_ "FlexKomSID" SG_ 788 CFG_FEATURE 1679;
BA_ "FlexKomSigLaenge" SG_ 788 CFG_FEATURE 24;
BA_ "FlexKomSigName" SG_ 788 CFG_FEATURE "CFG_RQ_C";
BA_ "FlexKomSigStartPos" SG_ 788 CFG_FEATURE 7;
BA_ "FlexKomSigStartValue" SG_ 788 CFG_FEATURE "000000h";
BA_ "GenSigCycleTimeActive" SG_ 788 CFG_FEATURE 50;
BA_ "GenSigSendType" SG_ 788 CFG_FEATURE 2;
BA_ "GenSigSNA" SG_ 788 CFG_FEATURE "0h";
BA_ "RID" SG_ 788 CFG_FEATURE "1144";
BA_ "FlexKomComment" SG_ 788 CFG_SET "Configurable display request";
BA_ "FlexKomIsMotorola" SG_ 788 CFG_SET 1;
BA_ "FlexKomSID" SG_ 788 CFG_SET 442;
BA_ "FlexKomSigLaenge" SG_ 788 CFG_SET 24;
BA_ "FlexKomSigName" SG_ 788 CFG_SET "CFG_RQ";
BA_ "FlexKomSigStartPos" SG_ 788 CFG_SET 7;
BA_ "FlexKomSigStartValue" SG_ 788 CFG_SET "000000h";
BA_ "GenSigCycleTimeActive" SG_ 788 CFG_SET 50;
BA_ "GenSigSendType" SG_ 788 CFG_SET 2;
BA_ "GenSigSNA" SG_ 788 CFG_SET "0h";
BA_ "RID" SG_ 788 CFG_SET "1173";
BA_ "FlexKomComment" SG_ 788 CFG_STAT_RQ "Configurable display request";
BA_ "FlexKomIsMotorola" SG_ 788 CFG_STAT_RQ 1;
BA_ "FlexKomSID" SG_ 788 CFG_STAT_RQ 442;
BA_ "FlexKomSigLaenge" SG_ 788 CFG_STAT_RQ 24;
BA_ "FlexKomSigName" SG_ 788 CFG_STAT_RQ "CFG_RQ";
BA_ "FlexKomSigStartPos" SG_ 788 CFG_STAT_RQ 7;
BA_ "FlexKomSigStartValue" SG_ 788 CFG_STAT_RQ "000000h";
BA_ "GenSigCycleTimeActive" SG_ 788 CFG_STAT_RQ 50;
BA_ "GenSigSendType" SG_ 788 CFG_STAT_RQ 2;
BA_ "GenSigSNA" SG_ 788 CFG_STAT_RQ "0h";
BA_ "RID" SG_ 788 CFG_STAT_RQ "1228";
BA_ "FlexKomComment" SG_ 500 ACCFCW_ChimeRq "DAS_A3_PKT";
BA_ "FlexKomIsMotorola" SG_ 500 ACCFCW_ChimeRq 1;
BA_ "FlexKomSID" SG_ 500 ACCFCW_ChimeRq 1043;
BA_ "FlexKomSigLaenge" SG_ 500 ACCFCW_ChimeRq 64;
BA_ "FlexKomSigName" SG_ 500 ACCFCW_ChimeRq "DAS_A3_PKT";
BA_ "FlexKomSigStartPos" SG_ 500 ACCFCW_ChimeRq 7;
BA_ "FlexKomSigStartValue" SG_ 500 ACCFCW_ChimeRq "1FFF0CCB000000FFh";
BA_ "GenSigCycleTime" SG_ 500 ACCFCW_ChimeRq 20;
BA_ "GenSigSNA" SG_ 500 ACCFCW_ChimeRq "0h";
BA_ "GenSigTimeout_IC" SG_ 500 ACCFCW_ChimeRq 210;
BA_ "FlexKomComment" SG_ 500 ACC_Drive_Cmd "DAS_A3_PKT";
BA_ "FlexKomIsMotorola" SG_ 500 ACC_Drive_Cmd 1;
BA_ "FlexKomSID" SG_ 500 ACC_Drive_Cmd 1043;
BA_ "FlexKomSigLaenge" SG_ 500 ACC_Drive_Cmd 64;
BA_ "FlexKomSigName" SG_ 500 ACC_Drive_Cmd "DAS_A3_PKT";
BA_ "FlexKomSigStartPos" SG_ 500 ACC_Drive_Cmd 7;
BA_ "FlexKomSigStartValue" SG_ 500 ACC_Drive_Cmd "1FFF0CCB000000FFh";
BA_ "GenSigCycleTime" SG_ 500 ACC_Drive_Cmd 20;
BA_ "GenSigSNA" SG_ 500 ACC_Drive_Cmd "0h";
BA_ "GenSigTimeout_ORC" SG_ 500 ACC_Drive_Cmd 70;
BA_ "FlexKomComment" SG_ 500 ACC_Enbl "DAS_A3_PKT";
BA_ "FlexKomIsMotorola" SG_ 500 ACC_Enbl 1;
BA_ "FlexKomSID" SG_ 500 ACC_Enbl 1043;
BA_ "FlexKomSigLaenge" SG_ 500 ACC_Enbl 64;
BA_ "FlexKomSigName" SG_ 500 ACC_Enbl "DAS_A3_PKT";
BA_ "FlexKomSigStartPos" SG_ 500 ACC_Enbl 7;
BA_ "FlexKomSigStartValue" SG_ 500 ACC_Enbl "1FFF0CCB000000FFh";
BA_ "GenSigCycleTime" SG_ 500 ACC_Enbl 20;
BA_ "GenSigSNA" SG_ 500 ACC_Enbl "0h";
BA_ "GenSigTimeout_IC" SG_ 500 ACC_Enbl 210;
BA_ "GenSigTimeout_ORC" SG_ 500 ACC_Enbl 70;
BA_ "FlexKomComment" SG_ 500 ACC_Engd "DAS_A3_PKT";
BA_ "FlexKomIsMotorola" SG_ 500 ACC_Engd 1;
BA_ "FlexKomSID" SG_ 500 ACC_Engd 1043;
BA_ "FlexKomSigLaenge" SG_ 500 ACC_Engd 64;
BA_ "FlexKomSigName" SG_ 500 ACC_Engd "DAS_A3_PKT";
BA_ "FlexKomSigStartPos" SG_ 500 ACC_Engd 7;
BA_ "FlexKomSigStartValue" SG_ 500 ACC_Engd "1FFF0CCB000000FFh";
BA_ "GenSigCycleTime" SG_ 500 ACC_Engd 20;
BA_ "GenSigSNA" SG_ 500 ACC_Engd "0h";
BA_ "GenSigTimeout_IC" SG_ 500 ACC_Engd 210;
BA_ "GenSigTimeout_ORC" SG_ 500 ACC_Engd 70;
BA_ "RID" SG_ 500 ACC_Engd "6421";
BA_ "FlexKomComment" SG_ 500 ACC_Still_Cmd "DAS_A3_PKT";
BA_ "FlexKomIsMotorola" SG_ 500 ACC_Still_Cmd 1;
BA_ "FlexKomSID" SG_ 500 ACC_Still_Cmd 1043;
BA_ "FlexKomSigLaenge" SG_ 500 ACC_Still_Cmd 64;
BA_ "FlexKomSigName" SG_ 500 ACC_Still_Cmd "DAS_A3_PKT";
BA_ "FlexKomSigStartPos" SG_ 500 ACC_Still_Cmd 7;
BA_ "FlexKomSigStartValue" SG_ 500 ACC_Still_Cmd "1FFF0CCB000000FFh";
BA_ "GenSigCycleTime" SG_ 500 ACC_Still_Cmd 20;
BA_ "GenSigSNA" SG_ 500 ACC_Still_Cmd "0h";
BA_ "GenSigTimeout_ORC" SG_ 500 ACC_Still_Cmd 70;
BA_ "FlexKomComment" SG_ 500 As_DispRq "DAS_A3_PKT";
BA_ "FlexKomIsMotorola" SG_ 500 As_DispRq 1;
BA_ "FlexKomSID" SG_ 500 As_DispRq 1043;
BA_ "FlexKomSigLaenge" SG_ 500 As_DispRq 64;
BA_ "FlexKomSigName" SG_ 500 As_DispRq "DAS_A3_PKT";
BA_ "FlexKomSigStartPos" SG_ 500 As_DispRq 7;
BA_ "FlexKomSigStartValue" SG_ 500 As_DispRq "1FFF0CCB000000FFh";
BA_ "GenSigCycleTime" SG_ 500 As_DispRq 20;
BA_ "GenSigSNA" SG_ 500 As_DispRq "3h";
BA_ "GenSigTimeout_IC" SG_ 500 As_DispRq 210;
BA_ "GenSigTimeout_ORC" SG_ 500 As_DispRq 70;
BA_ "FlexKomComment" SG_ 500 Brk_Jrk_Rq "DAS_A3_PKT";
BA_ "FlexKomIsMotorola" SG_ 500 Brk_Jrk_Rq 1;
BA_ "FlexKomSID" SG_ 500 Brk_Jrk_Rq 1043;
BA_ "FlexKomSigLaenge" SG_ 500 Brk_Jrk_Rq 64;
BA_ "FlexKomSigName" SG_ 500 Brk_Jrk_Rq "DAS_A3_PKT";
BA_ "FlexKomSigStartPos" SG_ 500 Brk_Jrk_Rq 7;
BA_ "FlexKomSigStartValue" SG_ 500 Brk_Jrk_Rq "1FFF0CCB000000FFh";
BA_ "GenSigCycleTime" SG_ 500 Brk_Jrk_Rq 20;
BA_ "GenSigSNA" SG_ 500 Brk_Jrk_Rq "0h";
BA_ "FlexKomComment" SG_ 500 Brk_PreFill_Rq "DAS_A3_PKT";
BA_ "FlexKomIsMotorola" SG_ 500 Brk_PreFill_Rq 1;
BA_ "FlexKomSID" SG_ 500 Brk_PreFill_Rq 1043;
BA_ "FlexKomSigLaenge" SG_ 500 Brk_PreFill_Rq 64;
BA_ "FlexKomSigName" SG_ 500 Brk_PreFill_Rq "DAS_A3_PKT";
BA_ "FlexKomSigStartPos" SG_ 500 Brk_PreFill_Rq 7;
BA_ "FlexKomSigStartValue" SG_ 500 Brk_PreFill_Rq "1FFF0CCB000000FFh";
BA_ "GenSigCycleTime" SG_ 500 Brk_PreFill_Rq 20;
BA_ "GenSigSNA" SG_ 500 Brk_PreFill_Rq "0h";
BA_ "GenSigTimeout_ORC" SG_ 500 Brk_PreFill_Rq 70;
BA_ "FlexKomComment" SG_ 500 CRC_DAS_A3 "DAS_A3_PKT";
BA_ "FlexKomIsMotorola" SG_ 500 CRC_DAS_A3 1;
BA_ "FlexKomSID" SG_ 500 CRC_DAS_A3 1043;
BA_ "FlexKomSigLaenge" SG_ 500 CRC_DAS_A3 64;
BA_ "FlexKomSigName" SG_ 500 CRC_DAS_A3 "DAS_A3_PKT";
BA_ "FlexKomSigStartPos" SG_ 500 CRC_DAS_A3 7;
BA_ "FlexKomSigStartValue" SG_ 500 CRC_DAS_A3 "1FFF0CCB000000FFh";
BA_ "GenSigCycleTime" SG_ 500 CRC_DAS_A3 20;
BA_ "GenSigSNA" SG_ 500 CRC_DAS_A3 "FFh";
BA_ "GenSigStartValue" SG_ 500 CRC_DAS_A3 255;
BA_ "FlexKomComment" SG_ 500 DAS_ACCEL_Rq "DAS_A3_PKT";
BA_ "FlexKomIsMotorola" SG_ 500 DAS_ACCEL_Rq 1;
BA_ "FlexKomSID" SG_ 500 DAS_ACCEL_Rq 1043;
BA_ "FlexKomSigLaenge" SG_ 500 DAS_ACCEL_Rq 64;
BA_ "FlexKomSigName" SG_ 500 DAS_ACCEL_Rq "DAS_A3_PKT";
BA_ "FlexKomSigStartPos" SG_ 500 DAS_ACCEL_Rq 7;
BA_ "FlexKomSigStartValue" SG_ 500 DAS_ACCEL_Rq "1FFF0CCB000000FFh";
BA_ "GenSigCycleTime" SG_ 500 DAS_ACCEL_Rq 20;
BA_ "GenSigSNA" SG_ 500 DAS_ACCEL_Rq "FFFh";
BA_ "GenSigStartValue" SG_ 500 DAS_ACCEL_Rq 3275;
BA_ "GenSigTimeout_ORC" SG_ 500 DAS_ACCEL_Rq 70;
BA_ "FlexKomComment" SG_ 500 DAS_Rq_ID "DAS_A3_PKT";
BA_ "FlexKomIsMotorola" SG_ 500 DAS_Rq_ID 1;
BA_ "FlexKomSID" SG_ 500 DAS_Rq_ID 1043;
BA_ "FlexKomSigLaenge" SG_ 500 DAS_Rq_ID 64;
BA_ "FlexKomSigName" SG_ 500 DAS_Rq_ID "DAS_A3_PKT";
BA_ "FlexKomSigStartPos" SG_ 500 DAS_Rq_ID 7;
BA_ "FlexKomSigStartValue" SG_ 500 DAS_Rq_ID "1FFF0CCB000000FFh";
BA_ "GenSigCycleTime" SG_ 500 DAS_Rq_ID 20;
BA_ "GenSigSNA" SG_ 500 DAS_Rq_ID "7h";
BA_ "GenSigTimeout_ORC" SG_ 500 DAS_Rq_ID 70;
BA_ "FlexKomComment" SG_ 500 DAS_Sts "DAS_A3_PKT";
BA_ "FlexKomIsMotorola" SG_ 500 DAS_Sts 1;
BA_ "FlexKomSID" SG_ 500 DAS_Sts 1043;
BA_ "FlexKomSigLaenge" SG_ 500 DAS_Sts 64;
BA_ "FlexKomSigName" SG_ 500 DAS_Sts "DAS_A3_PKT";
BA_ "FlexKomSigStartPos" SG_ 500 DAS_Sts 7;
BA_ "FlexKomSigStartValue" SG_ 500 DAS_Sts "1FFF0CCB000000FFh";
BA_ "GenSigCycleTime" SG_ 500 DAS_Sts 20;
BA_ "GenSigSNA" SG_ 500 DAS_Sts "3h";
BA_ "FlexKomComment" SG_ 500 DsblFuelShutOff_ACC "DAS_A3_PKT";
BA_ "FlexKomIsMotorola" SG_ 500 DsblFuelShutOff_ACC 1;
BA_ "FlexKomSID" SG_ 500 DsblFuelShutOff_ACC 1043;
BA_ "FlexKomSigLaenge" SG_ 500 DsblFuelShutOff_ACC 64;
BA_ "FlexKomSigName" SG_ 500 DsblFuelShutOff_ACC "DAS_A3_PKT";
BA_ "FlexKomSigStartPos" SG_ 500 DsblFuelShutOff_ACC 7;
BA_ "FlexKomSigStartValue" SG_ 500 DsblFuelShutOff_ACC "1FFF0CCB000000FFh";
BA_ "GenSigCycleTime" SG_ 500 DsblFuelShutOff_ACC 20;
BA_ "GenSigSNA" SG_ 500 DsblFuelShutOff_ACC "0h";
BA_ "FlexKomComment" SG_ 500 MC_DAS_A3 "DAS_A3_PKT";
BA_ "FlexKomIsMotorola" SG_ 500 MC_DAS_A3 1;
BA_ "FlexKomSID" SG_ 500 MC_DAS_A3 1043;
BA_ "FlexKomSigLaenge" SG_ 500 MC_DAS_A3 64;
BA_ "FlexKomSigName" SG_ 500 MC_DAS_A3 "DAS_A3_PKT";
BA_ "FlexKomSigStartPos" SG_ 500 MC_DAS_A3 7;
BA_ "FlexKomSigStartValue" SG_ 500 MC_DAS_A3 "1FFF0CCB000000FFh";
BA_ "GenSigCycleTime" SG_ 500 MC_DAS_A3 20;
BA_ "GenSigSNA" SG_ 500 MC_DAS_A3 "0h";
BA_ "FlexKomComment" SG_ 625 CRC_DAS_A5 "DAS_A5 Packet";
BA_ "FlexKomIsMotorola" SG_ 625 CRC_DAS_A5 1;
BA_ "FlexKomSID" SG_ 625 CRC_DAS_A5 2333;
BA_ "FlexKomSigLaenge" SG_ 625 CRC_DAS_A5 64;
BA_ "FlexKomSigName" SG_ 625 CRC_DAS_A5 "DAS_A5_PKT";
BA_ "FlexKomSigStartPos" SG_ 625 CRC_DAS_A5 7;
BA_ "FlexKomSigStartValue" SG_ 625 CRC_DAS_A5 "000000FF000000FFh";
BA_ "GenSigCycleTime" SG_ 625 CRC_DAS_A5 20;
BA_ "GenSigSNA" SG_ 625 CRC_DAS_A5 "FFh";
BA_ "GenSigStartValue" SG_ 625 CRC_DAS_A5 255;
BA_ "FlexKomComment" SG_ 625 DAS_EPB_APPLY_RQ "DAS_A5 Packet";
BA_ "FlexKomIsMotorola" SG_ 625 DAS_EPB_APPLY_RQ 1;
BA_ "FlexKomSID" SG_ 625 DAS_EPB_APPLY_RQ 2333;
BA_ "FlexKomSigLaenge" SG_ 625 DAS_EPB_APPLY_RQ 64;
BA_ "FlexKomSigName" SG_ 625 DAS_EPB_APPLY_RQ "DAS_A5_PKT";
BA_ "FlexKomSigStartPos" SG_ 625 DAS_EPB_APPLY_RQ 7;
BA_ "FlexKomSigStartValue" SG_ 625 DAS_EPB_APPLY_RQ "000000FF000000FFh";
BA_ "GenSigCycleTime" SG_ 625 DAS_EPB_APPLY_RQ 20;
BA_ "GenSigSNA" SG_ 625 DAS_EPB_APPLY_RQ "0h";
BA_ "GenSigTimeout_RHSC2" SG_ 625 DAS_EPB_APPLY_RQ 70;
BA_ "FlexKomComment" SG_ 625 DAS_EPB_RELSE_RQ "DAS_A5 Packet";
BA_ "FlexKomIsMotorola" SG_ 625 DAS_EPB_RELSE_RQ 1;
BA_ "FlexKomSID" SG_ 625 DAS_EPB_RELSE_RQ 2333;
BA_ "FlexKomSigLaenge" SG_ 625 DAS_EPB_RELSE_RQ 64;
BA_ "FlexKomSigName" SG_ 625 DAS_EPB_RELSE_RQ "DAS_A5_PKT";
BA_ "FlexKomSigStartPos" SG_ 625 DAS_EPB_RELSE_RQ 7;
BA_ "FlexKomSigStartValue" SG_ 625 DAS_EPB_RELSE_RQ "000000FF000000FFh";
BA_ "GenSigCycleTime" SG_ 625 DAS_EPB_RELSE_RQ 20;
BA_ "GenSigSNA" SG_ 625 DAS_EPB_RELSE_RQ "0h";
BA_ "GenSigTimeout_RHSC2" SG_ 625 DAS_EPB_RELSE_RQ 70;
BA_ "FlexKomComment" SG_ 625 FCWBrkTeen "DAS_A5 Packet";
BA_ "FlexKomIsMotorola" SG_ 625 FCWBrkTeen 1;
BA_ "FlexKomSID" SG_ 625 FCWBrkTeen 2333;
BA_ "FlexKomSigLaenge" SG_ 625 FCWBrkTeen 64;
BA_ "FlexKomSigName" SG_ 625 FCWBrkTeen "DAS_A5_PKT";
BA_ "FlexKomSigStartPos" SG_ 625 FCWBrkTeen 7;
BA_ "FlexKomSigStartValue" SG_ 625 FCWBrkTeen "000000FF000000FFh";
BA_ "GenSigCycleTime" SG_ 625 FCWBrkTeen 20;
BA_ "GenSigSNA" SG_ 625 FCWBrkTeen "0h";
BA_ "GenSigTimeout_IC" SG_ 625 FCWBrkTeen 210;
BA_ "GenSigTimeout_ORC" SG_ 625 FCWBrkTeen 70;
BA_ "RID" SG_ 625 FCWBrkTeen "2165";
BA_ "FlexKomComment" SG_ 625 FCWSetting "DAS_A5 Packet";
BA_ "FlexKomIsMotorola" SG_ 625 FCWSetting 1;
BA_ "FlexKomSID" SG_ 625 FCWSetting 2333;
BA_ "FlexKomSigLaenge" SG_ 625 FCWSetting 64;
BA_ "FlexKomSigName" SG_ 625 FCWSetting "DAS_A5_PKT";
BA_ "FlexKomSigStartPos" SG_ 625 FCWSetting 7;
BA_ "FlexKomSigStartValue" SG_ 625 FCWSetting "000000FF000000FFh";
BA_ "GenSigCycleTime" SG_ 625 FCWSetting 20;
BA_ "GenSigSNA" SG_ 625 FCWSetting "0h";
BA_ "GenSigTimeout_CBC" SG_ 625 FCWSetting 210;
BA_ "GenSigTimeout_IC" SG_ 625 FCWSetting 210;
BA_ "GenSigTimeout_ORC" SG_ 625 FCWSetting 70;
BA_ "RID" SG_ 625 FCWSetting "2163";
BA_ "FlexKomComment" SG_ 625 FCWSettingTeen "DAS_A5 Packet";
BA_ "FlexKomIsMotorola" SG_ 625 FCWSettingTeen 1;
BA_ "FlexKomSID" SG_ 625 FCWSettingTeen 2333;
BA_ "FlexKomSigLaenge" SG_ 625 FCWSettingTeen 64;
BA_ "FlexKomSigName" SG_ 625 FCWSettingTeen "DAS_A5_PKT";
BA_ "FlexKomSigStartPos" SG_ 625 FCWSettingTeen 7;
BA_ "FlexKomSigStartValue" SG_ 625 FCWSettingTeen "000000FF000000FFh";
BA_ "GenSigCycleTime" SG_ 625 FCWSettingTeen 20;
BA_ "GenSigSNA" SG_ 625 FCWSettingTeen "0h";
BA_ "GenSigTimeout_CBC" SG_ 625 FCWSettingTeen 210;
BA_ "GenSigTimeout_IC" SG_ 625 FCWSettingTeen 210;
BA_ "GenSigTimeout_ORC" SG_ 625 FCWSettingTeen 70;
BA_ "RID" SG_ 625 FCWSettingTeen "2169";
BA_ "FlexKomComment" SG_ 625 FCWState "DAS_A5 Packet";
BA_ "FlexKomIsMotorola" SG_ 625 FCWState 1;
BA_ "FlexKomSID" SG_ 625 FCWState 2333;
BA_ "FlexKomSigLaenge" SG_ 625 FCWState 64;
BA_ "FlexKomSigName" SG_ 625 FCWState "DAS_A5_PKT";
BA_ "FlexKomSigStartPos" SG_ 625 FCWState 7;
BA_ "FlexKomSigStartValue" SG_ 625 FCWState "000000FF000000FFh";
BA_ "GenSigCycleTime" SG_ 625 FCWState 20;
BA_ "GenSigSNA" SG_ 625 FCWState "0h";
BA_ "GenSigTimeout_IC" SG_ 625 FCWState 210;
BA_ "GenSigTimeout_ORC" SG_ 625 FCWState 70;
BA_ "RID" SG_ 625 FCWState "2171";
BA_ "FlexKomComment" SG_ 625 MC_DAS_A5 "DAS_A5 Packet";
BA_ "FlexKomIsMotorola" SG_ 625 MC_DAS_A5 1;
BA_ "FlexKomSID" SG_ 625 MC_DAS_A5 2333;
BA_ "FlexKomSigLaenge" SG_ 625 MC_DAS_A5 64;
BA_ "FlexKomSigName" SG_ 625 MC_DAS_A5 "DAS_A5_PKT";
BA_ "FlexKomSigStartPos" SG_ 625 MC_DAS_A5 7;
BA_ "FlexKomSigStartValue" SG_ 625 MC_DAS_A5 "000000FF000000FFh";
BA_ "GenSigCycleTime" SG_ 625 MC_DAS_A5 20;
BA_ "GenSigSNA" SG_ 625 MC_DAS_A5 "0h";
BA_ "FlexKomComment" SG_ 625 SDS_Engaged_State "DAS_A5 Packet";
BA_ "FlexKomIsMotorola" SG_ 625 SDS_Engaged_State 1;
BA_ "FlexKomSID" SG_ 625 SDS_Engaged_State 2333;
BA_ "FlexKomSigLaenge" SG_ 625 SDS_Engaged_State 64;
BA_ "FlexKomSigName" SG_ 625 SDS_Engaged_State "DAS_A5_PKT";
BA_ "FlexKomSigStartPos" SG_ 625 SDS_Engaged_State 7;
BA_ "FlexKomSigStartValue" SG_ 625 SDS_Engaged_State "000000FF000000FFh";
BA_ "GenSigCycleTime" SG_ 625 SDS_Engaged_State 20;
BA_ "GenSigSNA" SG_ 625 SDS_Engaged_State "3h";
BA_ "GenSigTimeout_RHSC2" SG_ 625 SDS_Engaged_State 70;
BA_ "FlexKomComment" SG_ 625 WhlTrqActRq_DAS "DAS_A5 Packet";
BA_ "FlexKomIsMotorola" SG_ 625 WhlTrqActRq_DAS 1;
BA_ "FlexKomSID" SG_ 625 WhlTrqActRq_DAS 2333;
BA_ "FlexKomSigLaenge" SG_ 625 WhlTrqActRq_DAS 64;
BA_ "FlexKomSigName" SG_ 625 WhlTrqActRq_DAS "DAS_A5_PKT";
BA_ "FlexKomSigStartPos" SG_ 625 WhlTrqActRq_DAS 7;
BA_ "FlexKomSigStartValue" SG_ 625 WhlTrqActRq_DAS "000000FF000000FFh";
BA_ "GenSigCycleTime" SG_ 625 WhlTrqActRq_DAS 20;
BA_ "GenSigSNA" SG_ 625 WhlTrqActRq_DAS "0h";
BA_ "FlexKomComment" SG_ 625 WhlTrqRq_DAS "DAS_A5 Packet";
BA_ "FlexKomIsMotorola" SG_ 625 WhlTrqRq_DAS 1;
BA_ "FlexKomSID" SG_ 625 WhlTrqRq_DAS 2333;
BA_ "FlexKomSigLaenge" SG_ 625 WhlTrqRq_DAS 64;
BA_ "FlexKomSigName" SG_ 625 WhlTrqRq_DAS "DAS_A5_PKT";
BA_ "FlexKomSigStartPos" SG_ 625 WhlTrqRq_DAS 7;
BA_ "FlexKomSigStartValue" SG_ 625 WhlTrqRq_DAS "000000FF000000FFh";
BA_ "GenSigCycleTime" SG_ 625 WhlTrqRq_DAS 20;
BA_ "GenSigSNA" SG_ 625 WhlTrqRq_DAS "7FFFh";
BA_ "FlexKomComment" SG_ 2015 DG_RQ_GLOBAL "Diagnostic-Request";
BA_ "FlexKomIsMotorola" SG_ 2015 DG_RQ_GLOBAL 1;
BA_ "FlexKomSID" SG_ 2015 DG_RQ_GLOBAL 392;
BA_ "FlexKomSigLaenge" SG_ 2015 DG_RQ_GLOBAL 64;
BA_ "FlexKomSigName" SG_ 2015 DG_RQ_GLOBAL "DG_RQ_GLOBAL";
BA_ "FlexKomSigStartPos" SG_ 2015 DG_RQ_GLOBAL 7;
BA_ "FlexKomSigStartValue" SG_ 2015 DG_RQ_GLOBAL "0000000000000000h";
BA_ "GenSigSNA" SG_ 2015 DG_RQ_GLOBAL "0h";
BA_ "FlexKomComment" SG_ 1875 D_RQ_DASM "Diagnostic-Request";
BA_ "FlexKomIsMotorola" SG_ 1875 D_RQ_DASM 1;
BA_ "FlexKomSID" SG_ 1875 D_RQ_DASM 97;
BA_ "FlexKomSigLaenge" SG_ 1875 D_RQ_DASM 64;
BA_ "FlexKomSigName" SG_ 1875 D_RQ_DASM "D_RQ_DASM";
BA_ "FlexKomSigStartPos" SG_ 1875 D_RQ_DASM 7;
BA_ "FlexKomSigStartValue" SG_ 1875 D_RQ_DASM "0000000000000000h";
BA_ "GenSigSendType" SG_ 1875 D_RQ_DASM 1;
BA_ "GenSigSNA" SG_ 1875 D_RQ_DASM "0h";
BA_ "FlexKomComment" SG_ 1882 D_RQ_EPS "Diagnostic-Request";
BA_ "FlexKomIsMotorola" SG_ 1882 D_RQ_EPS 1;
BA_ "FlexKomSID" SG_ 1882 D_RQ_EPS 87;
BA_ "FlexKomSigLaenge" SG_ 1882 D_RQ_EPS 64;
BA_ "FlexKomSigName" SG_ 1882 D_RQ_EPS "D_RQ_EPS";
BA_ "FlexKomSigStartPos" SG_ 1882 D_RQ_EPS 7;
BA_ "FlexKomSigStartValue" SG_ 1882 D_RQ_EPS "0000000000000000h";
BA_ "GenSigSendType" SG_ 1882 D_RQ_EPS 1;
BA_ "GenSigSNA" SG_ 1882 D_RQ_EPS "0h";
BA_ "FlexKomComment" SG_ 1892 D_RQ_HaLF "Diagnostic-Request";
BA_ "FlexKomIsMotorola" SG_ 1892 D_RQ_HaLF 1;
BA_ "FlexKomSID" SG_ 1892 D_RQ_HaLF 1632;
BA_ "FlexKomSigLaenge" SG_ 1892 D_RQ_HaLF 64;
BA_ "FlexKomSigName" SG_ 1892 D_RQ_HaLF "D_RQ_HaLF";
BA_ "FlexKomSigStartPos" SG_ 1892 D_RQ_HaLF 7;
BA_ "FlexKomSigStartValue" SG_ 1892 D_RQ_HaLF "0000000000000000h";
BA_ "GenSigSendType" SG_ 1892 D_RQ_HaLF 1;
BA_ "GenSigSNA" SG_ 1892 D_RQ_HaLF "0h";
BA_ "FlexKomComment" SG_ 1890 D_RQ_PTS "Diagnostic-Request";
BA_ "FlexKomIsMotorola" SG_ 1890 D_RQ_PTS 1;
BA_ "FlexKomSID" SG_ 1890 D_RQ_PTS 109;
BA_ "FlexKomSigLaenge" SG_ 1890 D_RQ_PTS 64;
BA_ "FlexKomSigName" SG_ 1890 D_RQ_PTS "D_RQ_PTS";
BA_ "FlexKomSigStartPos" SG_ 1890 D_RQ_PTS 7;
BA_ "FlexKomSigStartValue" SG_ 1890 D_RQ_PTS "0000000000000000h";
BA_ "GenSigSendType" SG_ 1890 D_RQ_PTS 1;
BA_ "GenSigSNA" SG_ 1890 D_RQ_PTS "0h";
BA_ "FlexKomComment" SG_ 1235 D_RS_DASM "Diagnostic-Response";
BA_ "FlexKomIsMotorola" SG_ 1235 D_RS_DASM 1;
BA_ "FlexKomSID" SG_ 1235 D_RS_DASM 149;
BA_ "FlexKomSigLaenge" SG_ 1235 D_RS_DASM 64;
BA_ "FlexKomSigName" SG_ 1235 D_RS_DASM "D_RS_DASM";
BA_ "FlexKomSigStartPos" SG_ 1235 D_RS_DASM 7;
BA_ "FlexKomSigStartValue" SG_ 1235 D_RS_DASM "0000000000000000h";
BA_ "GenSigSendType" SG_ 1235 D_RS_DASM 1;
BA_ "GenSigSNA" SG_ 1235 D_RS_DASM "0h";
BA_ "FlexKomComment" SG_ 1242 D_RS_EPS "Diagnostic-Response";
BA_ "FlexKomIsMotorola" SG_ 1242 D_RS_EPS 1;
BA_ "FlexKomSID" SG_ 1242 D_RS_EPS 141;
BA_ "FlexKomSigLaenge" SG_ 1242 D_RS_EPS 64;
BA_ "FlexKomSigName" SG_ 1242 D_RS_EPS "D_RS_EPS";
BA_ "FlexKomSigStartPos" SG_ 1242 D_RS_EPS 7;
BA_ "FlexKomSigStartValue" SG_ 1242 D_RS_EPS "0000000000000000h";
BA_ "GenSigSendType" SG_ 1242 D_RS_EPS 1;
BA_ "GenSigSNA" SG_ 1242 D_RS_EPS "0h";
BA_ "FlexKomComment" SG_ 1252 D_RS_HaLF "Diagnostic-Response";
BA_ "FlexKomIsMotorola" SG_ 1252 D_RS_HaLF 1;
BA_ "FlexKomSID" SG_ 1252 D_RS_HaLF 1633;
BA_ "FlexKomSigLaenge" SG_ 1252 D_RS_HaLF 64;
BA_ "FlexKomSigName" SG_ 1252 D_RS_HaLF "D_RS_HaLF";
BA_ "FlexKomSigStartPos" SG_ 1252 D_RS_HaLF 7;
BA_ "FlexKomSigStartValue" SG_ 1252 D_RS_HaLF "0000000000000000h";
BA_ "GenSigSendType" SG_ 1252 D_RS_HaLF 1;
BA_ "GenSigSNA" SG_ 1252 D_RS_HaLF "0h";
BA_ "FlexKomComment" SG_ 1250 D_RS_PTS "Diagnostic-Response";
BA_ "FlexKomIsMotorola" SG_ 1250 D_RS_PTS 1;
BA_ "FlexKomSID" SG_ 1250 D_RS_PTS 161;
BA_ "FlexKomSigLaenge" SG_ 1250 D_RS_PTS 64;
BA_ "FlexKomSigName" SG_ 1250 D_RS_PTS "D_RS_PTS";
BA_ "FlexKomSigStartPos" SG_ 1250 D_RS_PTS 7;
BA_ "FlexKomSigStartValue" SG_ 1250 D_RS_PTS "0000000000000000h";
BA_ "GenSigSendType" SG_ 1250 D_RS_PTS 1;
BA_ "GenSigSNA" SG_ 1250 D_RS_PTS "0h";
BA_ "FlexKomComment" SG_ 264 CRC_ECM_A1 "ECM_A1 Packet";
BA_ "FlexKomIsMotorola" SG_ 264 CRC_ECM_A1 1;
BA_ "FlexKomSID" SG_ 264 CRC_ECM_A1 446;
BA_ "FlexKomSigLaenge" SG_ 264 CRC_ECM_A1 64;
BA_ "FlexKomSigName" SG_ 264 CRC_ECM_A1 "ECM_A1_PKT";
BA_ "FlexKomSigStartPos" SG_ 264 CRC_ECM_A1 7;
BA_ "FlexKomSigStartValue" SG_ 264 CRC_ECM_A1 "FFFF1FFF1FFF00FFh";
BA_ "GenSigCycleTime" SG_ 264 CRC_ECM_A1 10;
BA_ "GenSigSNA" SG_ 264 CRC_ECM_A1 "FFh";
BA_ "GenSigStartValue" SG_ 264 CRC_ECM_A1 255;
BA_ "FlexKomComment" SG_ 264 ECM_IMMO_STAT_CANC "ECM_A1 Packet";
BA_ "FlexKomIsMotorola" SG_ 264 ECM_IMMO_STAT_CANC 1;
BA_ "FlexKomSID" SG_ 264 ECM_IMMO_STAT_CANC 446;
BA_ "FlexKomSigLaenge" SG_ 264 ECM_IMMO_STAT_CANC 64;
BA_ "FlexKomSigName" SG_ 264 ECM_IMMO_STAT_CANC "ECM_A1_PKT";
BA_ "FlexKomSigStartPos" SG_ 264 ECM_IMMO_STAT_CANC 7;
BA_ "FlexKomSigStartValue" SG_ 264 ECM_IMMO_STAT_CANC "FFFF1FFF1FFF00FFh";
BA_ "GenSigCycleTime" SG_ 264 ECM_IMMO_STAT_CANC 10;
BA_ "GenSigSNA" SG_ 264 ECM_IMMO_STAT_CANC "3h";
BA_ "GenSigTimeout_CBC" SG_ 264 ECM_IMMO_STAT_CANC 105;
BA_ "FlexKomComment" SG_ 264 EngRPM "ECM_A1 Packet";
BA_ "FlexKomIsMotorola" SG_ 264 EngRPM 1;
BA_ "FlexKomSID" SG_ 264 EngRPM 446;
BA_ "FlexKomSigLaenge" SG_ 264 EngRPM 64;
BA_ "FlexKomSigName" SG_ 264 EngRPM "ECM_A1_PKT";
BA_ "FlexKomSigStartPos" SG_ 264 EngRPM 7;
BA_ "FlexKomSigStartValue" SG_ 264 EngRPM "FFFF1FFF1FFF00FFh";
BA_ "GenSigCycleTime" SG_ 264 EngRPM 10;
BA_ "GenSigSNA" SG_ 264 EngRPM "FFFFh";
BA_ "GenSigStartValue" SG_ 264 EngRPM 65535;
BA_ "GenSigTimeout_CBC" SG_ 264 EngRPM 105;
BA_ "GenSigTimeout_EPS" SG_ 264 EngRPM 105;
BA_ "GenSigTimeout_RHSC2" SG_ 264 EngRPM 105;
BA_ "GenSigTimeout_IC" SG_ 264 EngRPM 105;
BA_ "GenSigTimeout_ORC" SG_ 264 EngRPM 35;
BA_ "RID" SG_ 264 EngRPM "2185";
BA_ "FlexKomComment" SG_ 264 MC_ECM_A1 "ECM_A1 Packet";
BA_ "FlexKomIsMotorola" SG_ 264 MC_ECM_A1 1;
BA_ "FlexKomSID" SG_ 264 MC_ECM_A1 446;
BA_ "FlexKomSigLaenge" SG_ 264 MC_ECM_A1 64;
BA_ "FlexKomSigName" SG_ 264 MC_ECM_A1 "ECM_A1_PKT";
BA_ "FlexKomSigStartPos" SG_ 264 MC_ECM_A1 7;
BA_ "FlexKomSigStartValue" SG_ 264 MC_ECM_A1 "FFFF1FFF1FFF00FFh";
BA_ "GenSigCycleTime" SG_ 264 MC_ECM_A1 10;
BA_ "GenSigSNA" SG_ 264 MC_ECM_A1 "0h";
BA_ "FlexKomComment" SG_ 288 AccelPdlPosn "ECM_A2 Packet";
BA_ "FlexKomIsMotorola" SG_ 288 AccelPdlPosn 1;
BA_ "FlexKomSID" SG_ 288 AccelPdlPosn 455;
BA_ "FlexKomSigLaenge" SG_ 288 AccelPdlPosn 56;
BA_ "FlexKomSigName" SG_ 288 AccelPdlPosn "ECM_A2_PKT";
BA_ "FlexKomSigStartPos" SG_ 288 AccelPdlPosn 7;
BA_ "FlexKomSigStartValue" SG_ 288 AccelPdlPosn "1FFFFF1FFF00FFh";
BA_ "GenSigCycleTime" SG_ 288 AccelPdlPosn 20;
BA_ "GenSigSNA" SG_ 288 AccelPdlPosn "FFh";
BA_ "GenSigStartValue" SG_ 288 AccelPdlPosn 255;
BA_ "GenSigTimeout_ETM" SG_ 288 AccelPdlPosn 210;
BA_ "RID" SG_ 288 AccelPdlPosn "5036";
BA_ "FlexKomComment" SG_ 288 AccelPdlPosnSens_Flt "ECM_A2 Packet";
BA_ "FlexKomIsMotorola" SG_ 288 AccelPdlPosnSens_Flt 1;
BA_ "FlexKomSID" SG_ 288 AccelPdlPosnSens_Flt 455;
BA_ "FlexKomSigLaenge" SG_ 288 AccelPdlPosnSens_Flt 56;
BA_ "FlexKomSigName" SG_ 288 AccelPdlPosnSens_Flt "ECM_A2_PKT";
BA_ "FlexKomSigStartPos" SG_ 288 AccelPdlPosnSens_Flt 7;
BA_ "FlexKomSigStartValue" SG_ 288 AccelPdlPosnSens_Flt "1FFFFF1FFF00FFh";
BA_ "GenSigCycleTime" SG_ 288 AccelPdlPosnSens_Flt 20;
BA_ "GenSigSNA" SG_ 288 AccelPdlPosnSens_Flt "0h";
BA_ "RID" SG_ 288 AccelPdlPosnSens_Flt "5031";
BA_ "FlexKomComment" SG_ 288 CRC_ECM_A2 "ECM_A2 Packet";
BA_ "FlexKomIsMotorola" SG_ 288 CRC_ECM_A2 1;
BA_ "FlexKomSID" SG_ 288 CRC_ECM_A2 455;
BA_ "FlexKomSigLaenge" SG_ 288 CRC_ECM_A2 56;
BA_ "FlexKomSigName" SG_ 288 CRC_ECM_A2 "ECM_A2_PKT";
BA_ "FlexKomSigStartPos" SG_ 288 CRC_ECM_A2 7;
BA_ "FlexKomSigStartValue" SG_ 288 CRC_ECM_A2 "1FFFFF1FFF00FFh";
BA_ "GenSigCycleTime" SG_ 288 CRC_ECM_A2 20;
BA_ "GenSigSNA" SG_ 288 CRC_ECM_A2 "FFh";
BA_ "GenSigStartValue" SG_ 288 CRC_ECM_A2 255;
BA_ "FlexKomComment" SG_ 288 CRUISE_OVERRIDE "ECM_A2 Packet";
BA_ "FlexKomIsMotorola" SG_ 288 CRUISE_OVERRIDE 1;
BA_ "FlexKomSID" SG_ 288 CRUISE_OVERRIDE 455;
BA_ "FlexKomSigLaenge" SG_ 288 CRUISE_OVERRIDE 56;
BA_ "FlexKomSigName" SG_ 288 CRUISE_OVERRIDE "ECM_A2_PKT";
BA_ "FlexKomSigStartPos" SG_ 288 CRUISE_OVERRIDE 7;
BA_ "FlexKomSigStartValue" SG_ 288 CRUISE_OVERRIDE "1FFFFF1FFF00FFh";
BA_ "GenSigCycleTime" SG_ 288 CRUISE_OVERRIDE 20;
BA_ "GenSigSNA" SG_ 288 CRUISE_OVERRIDE "0h";
BA_ "GenSigTimeout_IC" SG_ 288 CRUISE_OVERRIDE 210;
BA_ "FlexKomComment" SG_ 288 ECM_LHOM "ECM_A2 Packet";
BA_ "FlexKomIsMotorola" SG_ 288 ECM_LHOM 1;
BA_ "FlexKomSID" SG_ 288 ECM_LHOM 455;
BA_ "FlexKomSigLaenge" SG_ 288 ECM_LHOM 56;
BA_ "FlexKomSigName" SG_ 288 ECM_LHOM "ECM_A2_PKT";
BA_ "FlexKomSigStartPos" SG_ 288 ECM_LHOM 7;
BA_ "FlexKomSigStartValue" SG_ 288 ECM_LHOM "1FFFFF1FFF00FFh";
BA_ "GenSigCycleTime" SG_ 288 ECM_LHOM 20;
BA_ "GenSigSNA" SG_ 288 ECM_LHOM "0h";
BA_ "FlexKomComment" SG_ 288 ESS_RqShftPark "ECM_A2 Packet";
BA_ "FlexKomIsMotorola" SG_ 288 ESS_RqShftPark 1;
BA_ "FlexKomSID" SG_ 288 ESS_RqShftPark 455;
BA_ "FlexKomSigLaenge" SG_ 288 ESS_RqShftPark 56;
BA_ "FlexKomSigName" SG_ 288 ESS_RqShftPark "ECM_A2_PKT";
BA_ "FlexKomSigStartPos" SG_ 288 ESS_RqShftPark 7;
BA_ "FlexKomSigStartValue" SG_ 288 ESS_RqShftPark "1FFFFF1FFF00FFh";
BA_ "GenSigCycleTime" SG_ 288 ESS_RqShftPark 20;
BA_ "GenSigSNA" SG_ 288 ESS_RqShftPark "0h";
BA_ "FlexKomComment" SG_ 288 EngTrq_Enbl_Rq_AS "ECM_A2 Packet";
BA_ "FlexKomIsMotorola" SG_ 288 EngTrq_Enbl_Rq_AS 1;
BA_ "FlexKomSID" SG_ 288 EngTrq_Enbl_Rq_AS 455;
BA_ "FlexKomSigLaenge" SG_ 288 EngTrq_Enbl_Rq_AS 56;
BA_ "FlexKomSigName" SG_ 288 EngTrq_Enbl_Rq_AS "ECM_A2_PKT";
BA_ "FlexKomSigStartPos" SG_ 288 EngTrq_Enbl_Rq_AS 7;
BA_ "FlexKomSigStartValue" SG_ 288 EngTrq_Enbl_Rq_AS "1FFFFF1FFF00FFh";
BA_ "GenSigCycleTime" SG_ 288 EngTrq_Enbl_Rq_AS 20;
BA_ "GenSigSNA" SG_ 288 EngTrq_Enbl_Rq_AS "0h";
BA_ "FlexKomComment" SG_ 288 EngTrq_Enbl_Rq_ESC "ECM_A2 Packet";
BA_ "FlexKomIsMotorola" SG_ 288 EngTrq_Enbl_Rq_ESC 1;
BA_ "FlexKomSID" SG_ 288 EngTrq_Enbl_Rq_ESC 455;
BA_ "FlexKomSigLaenge" SG_ 288 EngTrq_Enbl_Rq_ESC 56;
BA_ "FlexKomSigName" SG_ 288 EngTrq_Enbl_Rq_ESC "ECM_A2_PKT";
BA_ "FlexKomSigStartPos" SG_ 288 EngTrq_Enbl_Rq_ESC 7;
BA_ "FlexKomSigStartValue" SG_ 288 EngTrq_Enbl_Rq_ESC "1FFFFF1FFF00FFh";
BA_ "GenSigCycleTime" SG_ 288 EngTrq_Enbl_Rq_ESC 20;
BA_ "GenSigSNA" SG_ 288 EngTrq_Enbl_Rq_ESC "0h";
BA_ "FlexKomComment" SG_ 288 LV12PwrFreeRq "ECM_A2 Packet";
BA_ "FlexKomIsMotorola" SG_ 288 LV12PwrFreeRq 1;
BA_ "FlexKomSID" SG_ 288 LV12PwrFreeRq 455;
BA_ "FlexKomSigLaenge" SG_ 288 LV12PwrFreeRq 56;
BA_ "FlexKomSigName" SG_ 288 LV12PwrFreeRq "ECM_A2_PKT";
BA_ "FlexKomSigStartPos" SG_ 288 LV12PwrFreeRq 7;
BA_ "FlexKomSigStartValue" SG_ 288 LV12PwrFreeRq "1FFFFF1FFF00FFh";
BA_ "GenSigCycleTime" SG_ 288 LV12PwrFreeRq 20;
BA_ "GenSigSNA" SG_ 288 LV12PwrFreeRq "0h";
BA_ "FlexKomComment" SG_ 288 MC_ECM_A2 "ECM_A2 Packet";
BA_ "FlexKomIsMotorola" SG_ 288 MC_ECM_A2 1;
BA_ "FlexKomSID" SG_ 288 MC_ECM_A2 455;
BA_ "FlexKomSigLaenge" SG_ 288 MC_ECM_A2 56;
BA_ "FlexKomSigName" SG_ 288 MC_ECM_A2 "ECM_A2_PKT";
BA_ "FlexKomSigStartPos" SG_ 288 MC_ECM_A2 7;
BA_ "FlexKomSigStartValue" SG_ 288 MC_ECM_A2 "1FFFFF1FFF00FFh";
BA_ "GenSigCycleTime" SG_ 288 MC_ECM_A2 20;
BA_ "GenSigSNA" SG_ 288 MC_ECM_A2 "0h";
BA_ "FlexKomComment" SG_ 288 RPMOverRev "ECM_A2 Packet";
BA_ "FlexKomIsMotorola" SG_ 288 RPMOverRev 1;
BA_ "FlexKomSID" SG_ 288 RPMOverRev 455;
BA_ "FlexKomSigLaenge" SG_ 288 RPMOverRev 56;
BA_ "FlexKomSigName" SG_ 288 RPMOverRev "ECM_A2_PKT";
BA_ "FlexKomSigStartPos" SG_ 288 RPMOverRev 7;
BA_ "FlexKomSigStartValue" SG_ 288 RPMOverRev "1FFFFF1FFF00FFh";
BA_ "GenSigCycleTime" SG_ 288 RPMOverRev 20;
BA_ "GenSigSNA" SG_ 288 RPMOverRev "0h";
BA_ "FlexKomComment" SG_ 760 CRC_ECM_A3 "ECM_A3 message packet";
BA_ "FlexKomIsMotorola" SG_ 760 CRC_ECM_A3 1;
BA_ "FlexKomSID" SG_ 760 CRC_ECM_A3 1369;
BA_ "FlexKomSigLaenge" SG_ 760 CRC_ECM_A3 64;
BA_ "FlexKomSigName" SG_ 760 CRC_ECM_A3 "ECM_A3_PKT";
BA_ "FlexKomSigStartPos" SG_ 760 CRC_ECM_A3 7;
BA_ "FlexKomSigStartValue" SG_ 760 CRC_ECM_A3 "5FFF1FFF00FF0FFFh";
BA_ "GenSigCycleTime" SG_ 760 CRC_ECM_A3 10;
BA_ "GenSigSNA" SG_ 760 CRC_ECM_A3 "FFh";
BA_ "GenSigStartValue" SG_ 760 CRC_ECM_A3 255;
BA_ "FlexKomComment" SG_ 760 ESS_ENG_ST "ECM_A3 message packet";
BA_ "FlexKomIsMotorola" SG_ 760 ESS_ENG_ST 1;
BA_ "FlexKomSID" SG_ 760 ESS_ENG_ST 1369;
BA_ "FlexKomSigLaenge" SG_ 760 ESS_ENG_ST 64;
BA_ "FlexKomSigName" SG_ 760 ESS_ENG_ST "ECM_A3_PKT";
BA_ "FlexKomSigStartPos" SG_ 760 ESS_ENG_ST 7;
BA_ "FlexKomSigStartValue" SG_ 760 ESS_ENG_ST "5FFF1FFF00FF0FFFh";
BA_ "GenSigCycleTime" SG_ 760 ESS_ENG_ST 10;
BA_ "GenSigSNA" SG_ 760 ESS_ENG_ST "Fh";
BA_ "GenSigStartValue" SG_ 760 ESS_ENG_ST 15;
BA_ "GenSigTimeout_CBC" SG_ 760 ESS_ENG_ST 105;
BA_ "GenSigTimeout_ORC" SG_ 760 ESS_ENG_ST 35;
BA_ "GenSigTimeout_RF_HUB" SG_ 760 ESS_ENG_ST 105;
BA_ "RID" SG_ 760 ESS_ENG_ST "1653";
BA_ "FlexKomComment" SG_ 760 MC_ECM_A3 "ECM_A3 message packet";
BA_ "FlexKomIsMotorola" SG_ 760 MC_ECM_A3 1;
BA_ "FlexKomSID" SG_ 760 MC_ECM_A3 1369;
BA_ "FlexKomSigLaenge" SG_ 760 MC_ECM_A3 64;
BA_ "FlexKomSigName" SG_ 760 MC_ECM_A3 "ECM_A3_PKT";
BA_ "FlexKomSigStartPos" SG_ 760 MC_ECM_A3 7;
BA_ "FlexKomSigStartValue" SG_ 760 MC_ECM_A3 "5FFF1FFF00FF0FFFh";
BA_ "GenSigCycleTime" SG_ 760 MC_ECM_A3 10;
BA_ "GenSigSNA" SG_ 760 MC_ECM_A3 "0h";
BA_ "RID" SG_ 760 MC_ECM_A3 "9769";
BA_ "FlexKomComment" SG_ 559 ActlAccelPdlPosn "ECM_A5 Packet";
BA_ "FlexKomIsMotorola" SG_ 559 ActlAccelPdlPosn 1;
BA_ "FlexKomSID" SG_ 559 ActlAccelPdlPosn 1821;
BA_ "FlexKomSigLaenge" SG_ 559 ActlAccelPdlPosn 64;
BA_ "FlexKomSigName" SG_ 559 ActlAccelPdlPosn "ECM_A5_PKT";
BA_ "FlexKomSigStartPos" SG_ 559 ActlAccelPdlPosn 7;
BA_ "FlexKomSigStartValue" SG_ 559 ActlAccelPdlPosn "FFFFFFFF00000CFFh";
BA_ "GenSigCycleTime" SG_ 559 ActlAccelPdlPosn 20;
BA_ "GenSigSNA" SG_ 559 ActlAccelPdlPosn "FFh";
BA_ "GenSigStartValue" SG_ 559 ActlAccelPdlPosn 255;
BA_ "GenSigTimeout_CBC" SG_ 559 ActlAccelPdlPosn 210;
BA_ "RID" SG_ 559 ActlAccelPdlPosn "5035";
BA_ "FlexKomComment" SG_ 559 CRC_ECM_A5 "ECM_A5 Packet";
BA_ "FlexKomIsMotorola" SG_ 559 CRC_ECM_A5 1;
BA_ "FlexKomSID" SG_ 559 CRC_ECM_A5 1821;
BA_ "FlexKomSigLaenge" SG_ 559 CRC_ECM_A5 64;
BA_ "FlexKomSigName" SG_ 559 CRC_ECM_A5 "ECM_A5_PKT";
BA_ "FlexKomSigStartPos" SG_ 559 CRC_ECM_A5 7;
BA_ "FlexKomSigStartValue" SG_ 559 CRC_ECM_A5 "FFFFFFFF00000CFFh";
BA_ "GenSigCycleTime" SG_ 559 CRC_ECM_A5 20;
BA_ "GenSigSNA" SG_ 559 CRC_ECM_A5 "FFh";
BA_ "GenSigStartValue" SG_ 559 CRC_ECM_A5 255;
BA_ "FlexKomComment" SG_ 559 MC_ECM_A5 "ECM_A5 Packet";
BA_ "FlexKomIsMotorola" SG_ 559 MC_ECM_A5 1;
BA_ "FlexKomSID" SG_ 559 MC_ECM_A5 1821;
BA_ "FlexKomSigLaenge" SG_ 559 MC_ECM_A5 64;
BA_ "FlexKomSigName" SG_ 559 MC_ECM_A5 "ECM_A5_PKT";
BA_ "FlexKomSigStartPos" SG_ 559 MC_ECM_A5 7;
BA_ "FlexKomSigStartValue" SG_ 559 MC_ECM_A5 "FFFFFFFF00000CFFh";
BA_ "GenSigCycleTime" SG_ 559 MC_ECM_A5 20;
BA_ "GenSigSNA" SG_ 559 MC_ECM_A5 "0h";
BA_ "FlexKomComment" SG_ 384 AM_ECM_Prsnt "Aftermarket ECM present";
BA_ "FlexKomIsMotorola" SG_ 384 AM_ECM_Prsnt 1;
BA_ "FlexKomSID" SG_ 384 AM_ECM_Prsnt 1941;
BA_ "FlexKomSigLaenge" SG_ 384 AM_ECM_Prsnt 2;
BA_ "FlexKomSigName" SG_ 384 AM_ECM_Prsnt "AM_ECM_Prsnt";
BA_ "FlexKomSigStartPos" SG_ 384 AM_ECM_Prsnt 46;
BA_ "FlexKomSigStartValue" SG_ 384 AM_ECM_Prsnt "00h";
BA_ "GenSigCycleTime" SG_ 384 AM_ECM_Prsnt 100;
BA_ "GenSigSNA" SG_ 384 AM_ECM_Prsnt "3h";
BA_ "GenSigTimeout_CBC" SG_ 384 AM_ECM_Prsnt 1050;
BA_ "FlexKomComment" SG_ 384 AirPress_Outsd "Ambient air pressure (barometric pressure)";
BA_ "FlexKomIsMotorola" SG_ 384 AirPress_Outsd 1;
BA_ "FlexKomSID" SG_ 384 AirPress_Outsd 1084;
BA_ "FlexKomSigLaenge" SG_ 384 AirPress_Outsd 8;
BA_ "FlexKomSigName" SG_ 384 AirPress_Outsd "AirPress_Outsd";
BA_ "FlexKomSigStartPos" SG_ 384 AirPress_Outsd 23;
BA_ "FlexKomSigStartValue" SG_ 384 AirPress_Outsd "FFh";
BA_ "GenSigCycleTime" SG_ 384 AirPress_Outsd 100;
BA_ "GenSigSNA" SG_ 384 AirPress_Outsd "FFh";
BA_ "GenSigStartValue" SG_ 384 AirPress_Outsd 255;
BA_ "GenSigTimeout_ETM" SG_ 384 AirPress_Outsd 1050;
BA_ "GenSigTimeout_IC" SG_ 384 AirPress_Outsd 1050;
BA_ "GenSigTimeout_RF_HUB" SG_ 384 AirPress_Outsd 1050;
BA_ "FlexKomComment" SG_ 384 CHRG_FAIL "Charging system Failure (battery indicator request";
BA_ "FlexKomIsMotorola" SG_ 384 CHRG_FAIL 1;
BA_ "FlexKomSID" SG_ 384 CHRG_FAIL 1085;
BA_ "FlexKomSigLaenge" SG_ 384 CHRG_FAIL 1;
BA_ "FlexKomSigName" SG_ 384 CHRG_FAIL "CHRG_FAIL";
BA_ "FlexKomSigStartPos" SG_ 384 CHRG_FAIL 41;
BA_ "FlexKomSigStartValue" SG_ 384 CHRG_FAIL "00h";
BA_ "GenSigCycleTime" SG_ 384 CHRG_FAIL 100;
BA_ "GenSigSNA" SG_ 384 CHRG_FAIL "1h";
BA_ "GenSigTimeout_IC" SG_ 384 CHRG_FAIL 1050;
BA_ "GenSigTimeout_ORC" SG_ 384 CHRG_FAIL 350;
BA_ "FlexKomComment" SG_ 384 EngCoolTemp "Engine coolant temperature";
BA_ "FlexKomIsMotorola" SG_ 384 EngCoolTemp 1;
BA_ "FlexKomSID" SG_ 384 EngCoolTemp 711;
BA_ "FlexKomSigLaenge" SG_ 384 EngCoolTemp 8;
BA_ "FlexKomSigName" SG_ 384 EngCoolTemp "EngCoolTemp";
BA_ "FlexKomSigStartPos" SG_ 384 EngCoolTemp 15;
BA_ "FlexKomSigStartValue" SG_ 384 EngCoolTemp "FFh";
BA_ "GenSigCycleTime" SG_ 384 EngCoolTemp 100;
BA_ "GenSigSNA" SG_ 384 EngCoolTemp "FFh";
BA_ "GenSigStartValue" SG_ 384 EngCoolTemp 255;
BA_ "GenSigTimeout_CBC" SG_ 384 EngCoolTemp 1050;
BA_ "GenSigTimeout_IC" SG_ 384 EngCoolTemp 1050;
BA_ "RID" SG_ 384 EngCoolTemp "1130";
BA_ "FlexKomComment" SG_ 384 IntkAirTemp "Engine Intake Air Temperature";
BA_ "FlexKomIsMotorola" SG_ 384 IntkAirTemp 1;
BA_ "FlexKomSID" SG_ 384 IntkAirTemp 441;
BA_ "FlexKomSigLaenge" SG_ 384 IntkAirTemp 8;
BA_ "FlexKomSigName" SG_ 384 IntkAirTemp "IntkAirTemp";
BA_ "FlexKomSigStartPos" SG_ 384 IntkAirTemp 7;
BA_ "FlexKomSigStartValue" SG_ 384 IntkAirTemp "00h";
BA_ "GenSigCycleTime" SG_ 384 IntkAirTemp 100;
BA_ "GenSigSNA" SG_ 384 IntkAirTemp "FFh";
BA_ "GenSigTimeout_ETM" SG_ 384 IntkAirTemp 1050;
BA_ "GenSigTimeout_IC" SG_ 384 IntkAirTemp 1050;
BA_ "RID" SG_ 384 IntkAirTemp "1149";
BA_ "FlexKomComment" SG_ 384 SysVolt "Engine voltage packet";
BA_ "FlexKomIsMotorola" SG_ 384 SysVolt 1;
BA_ "FlexKomSID" SG_ 384 SysVolt 437;
BA_ "FlexKomSigLaenge" SG_ 384 SysVolt 16;
BA_ "FlexKomSigName" SG_ 384 SysVolt "EngVoltPkt";
BA_ "FlexKomSigStartPos" SG_ 384 SysVolt 31;
BA_ "FlexKomSigStartValue" SG_ 384 SysVolt "0000h";
BA_ "GenSigCycleTime" SG_ 384 SysVolt 100;
BA_ "GenSigSNA" SG_ 384 SysVolt "FFh";
BA_ "FlexKomComment" SG_ 800 KeySense_DispReq "Key sense cluster EVIC request";
BA_ "FlexKomIsMotorola" SG_ 800 KeySense_DispReq 1;
BA_ "FlexKomSID" SG_ 800 KeySense_DispReq 2393;
BA_ "FlexKomSigLaenge" SG_ 800 KeySense_DispReq 2;
BA_ "FlexKomSigName" SG_ 800 KeySense_DispReq "KeySense_DispReq";
BA_ "FlexKomSigStartPos" SG_ 800 KeySense_DispReq 15;
BA_ "FlexKomSigStartValue" SG_ 800 KeySense_DispReq "00h";
BA_ "GenSigCycleTime" SG_ 800 KeySense_DispReq 100;
BA_ "GenSigSNA" SG_ 800 KeySense_DispReq "0h";
BA_ "GenSigTimeout_IC" SG_ 800 KeySense_DispReq 1050;
BA_ "FlexKomComment" SG_ 800 KeySense_SetSpdOpt "Key sense max speed option for ECM speed limiting";
BA_ "FlexKomIsMotorola" SG_ 800 KeySense_SetSpdOpt 1;
BA_ "FlexKomSID" SG_ 800 KeySense_SetSpdOpt 2394;
BA_ "FlexKomSigLaenge" SG_ 800 KeySense_SetSpdOpt 3;
BA_ "FlexKomSigName" SG_ 800 KeySense_SetSpdOpt "KeySense_SetSpdOpt";
BA_ "FlexKomSigStartPos" SG_ 800 KeySense_SetSpdOpt 2;
BA_ "FlexKomSigStartValue" SG_ 800 KeySense_SetSpdOpt "00h";
BA_ "GenSigCycleTime" SG_ 800 KeySense_SetSpdOpt 100;
BA_ "GenSigSNA" SG_ 800 KeySense_SetSpdOpt "7h";
BA_ "RID" SG_ 800 KeySense_SetSpdOpt "2192";
BA_ "FlexKomComment" SG_ 800 LeakCheckTimerValue "Requested leak test timer value";
BA_ "FlexKomIsMotorola" SG_ 800 LeakCheckTimerValue 1;
BA_ "FlexKomSID" SG_ 800 LeakCheckTimerValue 2575;
BA_ "FlexKomSigLaenge" SG_ 800 LeakCheckTimerValue 16;
BA_ "FlexKomSigName" SG_ 800 LeakCheckTimerValue "LeakCheckTimerValue";
BA_ "FlexKomSigStartPos" SG_ 800 LeakCheckTimerValue 15;
BA_ "FlexKomSigStartValue" SG_ 800 LeakCheckTimerValue "0000h";
BA_ "GenSigCycleTime" SG_ 800 LeakCheckTimerValue 100;
BA_ "GenSigSNA" SG_ 800 LeakCheckTimerValue "1FFh";
BA_ "FlexKomComment" SG_ 800 LeakTestRequest "Leak test is requested after powerdown; No request";
BA_ "FlexKomIsMotorola" SG_ 800 LeakTestRequest 1;
BA_ "FlexKomSID" SG_ 800 LeakTestRequest 2577;
BA_ "FlexKomSigLaenge" SG_ 800 LeakTestRequest 1;
BA_ "FlexKomSigName" SG_ 800 LeakTestRequest "LeakTestRequest";
BA_ "FlexKomSigStartPos" SG_ 800 LeakTestRequest 26;
BA_ "FlexKomSigStartValue" SG_ 800 LeakTestRequest "00h";
BA_ "GenSigCycleTime" SG_ 800 LeakTestRequest 100;
BA_ "GenSigSNA" SG_ 800 LeakTestRequest "0h";
BA_ "FlexKomComment" SG_ 800 LeakTestSts "Status of leak test";
BA_ "FlexKomIsMotorola" SG_ 800 LeakTestSts 1;
BA_ "FlexKomSID" SG_ 800 LeakTestSts 2576;
BA_ "FlexKomSigLaenge" SG_ 800 LeakTestSts 2;
BA_ "FlexKomSigName" SG_ 800 LeakTestSts "LeakTestSts";
BA_ "FlexKomSigStartPos" SG_ 800 LeakTestSts 28;
BA_ "FlexKomSigStartValue" SG_ 800 LeakTestSts "00h";
BA_ "GenSigCycleTime" SG_ 800 LeakTestSts 100;
BA_ "GenSigSNA" SG_ 800 LeakTestSts "0h";
BA_ "FlexKomComment" SG_ 800 RefuelEvent "Status of refuel event";
BA_ "FlexKomIsMotorola" SG_ 800 RefuelEvent 1;
BA_ "FlexKomSID" SG_ 800 RefuelEvent 2574;
BA_ "FlexKomSigLaenge" SG_ 800 RefuelEvent 3;
BA_ "FlexKomSigName" SG_ 800 RefuelEvent "RefuelEvent";
BA_ "FlexKomSigStartPos" SG_ 800 RefuelEvent 13;
BA_ "FlexKomSigStartValue" SG_ 800 RefuelEvent "00h";
BA_ "GenSigCycleTime" SG_ 800 RefuelEvent 100;
BA_ "GenSigSNA" SG_ 800 RefuelEvent "0h";
BA_ "FlexKomComment" SG_ 800 RefuelIndication "Indication to the driver about the status of the r";
BA_ "FlexKomIsMotorola" SG_ 800 RefuelIndication 1;
BA_ "FlexKomSID" SG_ 800 RefuelIndication 2578;
BA_ "FlexKomSigLaenge" SG_ 800 RefuelIndication 3;
BA_ "FlexKomSigName" SG_ 800 RefuelIndication "RefuelIndication";
BA_ "FlexKomSigStartPos" SG_ 800 RefuelIndication 31;
BA_ "FlexKomSigStartValue" SG_ 800 RefuelIndication "00h";
BA_ "GenSigCycleTime" SG_ 800 RefuelIndication 100;
BA_ "GenSigSNA" SG_ 800 RefuelIndication "0h";
BA_ "GenSigTimeout_IC" SG_ 800 RefuelIndication 1050;
BA_ "FlexKomComment" SG_ 280 ANL_LFT "ECM_ENG_TRQ packet";
BA_ "FlexKomIsMotorola" SG_ 280 ANL_LFT 1;
BA_ "FlexKomSID" SG_ 280 ANL_LFT 1853;
BA_ "FlexKomSigLaenge" SG_ 280 ANL_LFT 64;
BA_ "FlexKomSigName" SG_ 280 ANL_LFT "ECM_ENG_TRQ_Pkt";
BA_ "FlexKomSigStartPos" SG_ 280 ANL_LFT 7;
BA_ "FlexKomSigStartValue" SG_ 280 ANL_LFT "9FFF1FFF1FFF00FFh";
BA_ "GenSigCycleTime" SG_ 280 ANL_LFT 10;
BA_ "GenSigSNA" SG_ 280 ANL_LFT "0h";
BA_ "GenSigTimeout_CBC" SG_ 280 ANL_LFT 105;
BA_ "FlexKomComment" SG_ 280 CRC_ECM_ENG_TRQ "ECM_ENG_TRQ packet";
BA_ "FlexKomIsMotorola" SG_ 280 CRC_ECM_ENG_TRQ 1;
BA_ "FlexKomSID" SG_ 280 CRC_ECM_ENG_TRQ 1853;
BA_ "FlexKomSigLaenge" SG_ 280 CRC_ECM_ENG_TRQ 64;
BA_ "FlexKomSigName" SG_ 280 CRC_ECM_ENG_TRQ "ECM_ENG_TRQ_Pkt";
BA_ "FlexKomSigStartPos" SG_ 280 CRC_ECM_ENG_TRQ 7;
BA_ "FlexKomSigStartValue" SG_ 280 CRC_ECM_ENG_TRQ "9FFF1FFF1FFF00FFh";
BA_ "GenSigCycleTime" SG_ 280 CRC_ECM_ENG_TRQ 10;
BA_ "GenSigSNA" SG_ 280 CRC_ECM_ENG_TRQ "FFh";
BA_ "GenSigStartValue" SG_ 280 CRC_ECM_ENG_TRQ 255;
BA_ "FlexKomComment" SG_ 280 MC_ECM_ENG_TRQ "ECM_ENG_TRQ packet";
BA_ "FlexKomIsMotorola" SG_ 280 MC_ECM_ENG_TRQ 1;
BA_ "FlexKomSID" SG_ 280 MC_ECM_ENG_TRQ 1853;
BA_ "FlexKomSigLaenge" SG_ 280 MC_ECM_ENG_TRQ 64;
BA_ "FlexKomSigName" SG_ 280 MC_ECM_ENG_TRQ "ECM_ENG_TRQ_Pkt";
BA_ "FlexKomSigStartPos" SG_ 280 MC_ECM_ENG_TRQ 7;
BA_ "FlexKomSigStartValue" SG_ 280 MC_ECM_ENG_TRQ "9FFF1FFF1FFF00FFh";
BA_ "GenSigCycleTime" SG_ 280 MC_ECM_ENG_TRQ 10;
BA_ "GenSigSNA" SG_ 280 MC_ECM_ENG_TRQ "0h";
BA_ "FlexKomComment" SG_ 280 StartRelayBCMCmd "ECM_ENG_TRQ packet";
BA_ "FlexKomIsMotorola" SG_ 280 StartRelayBCMCmd 1;
BA_ "FlexKomSID" SG_ 280 StartRelayBCMCmd 1853;
BA_ "FlexKomSigLaenge" SG_ 280 StartRelayBCMCmd 64;
BA_ "FlexKomSigName" SG_ 280 StartRelayBCMCmd "ECM_ENG_TRQ_Pkt";
BA_ "FlexKomSigStartPos" SG_ 280 StartRelayBCMCmd 7;
BA_ "FlexKomSigStartValue" SG_ 280 StartRelayBCMCmd "9FFF1FFF1FFF00FFh";
BA_ "GenSigCycleTime" SG_ 280 StartRelayBCMCmd 10;
BA_ "GenSigSNA" SG_ 280 StartRelayBCMCmd "0h";
BA_ "FlexKomComment" SG_ 1427 ECU_APPL_DASM "ECU to External Application";
BA_ "FlexKomIsMotorola" SG_ 1427 ECU_APPL_DASM 1;
BA_ "FlexKomSID" SG_ 1427 ECU_APPL_DASM 364;
BA_ "FlexKomSigLaenge" SG_ 1427 ECU_APPL_DASM 64;
BA_ "FlexKomSigName" SG_ 1427 ECU_APPL_DASM "ECU_APPL_DASM";
BA_ "FlexKomSigStartPos" SG_ 1427 ECU_APPL_DASM 7;
BA_ "FlexKomSigStartValue" SG_ 1427 ECU_APPL_DASM "0000000000000000h";
BA_ "GenSigSendType" SG_ 1427 ECU_APPL_DASM 1;
BA_ "GenSigSNA" SG_ 1427 ECU_APPL_DASM "0h";
BA_ "FlexKomComment" SG_ 1434 ECU_APPL_EPS "ECU to External Application";
BA_ "FlexKomIsMotorola" SG_ 1434 ECU_APPL_EPS 1;
BA_ "FlexKomSID" SG_ 1434 ECU_APPL_EPS 354;
BA_ "FlexKomSigLaenge" SG_ 1434 ECU_APPL_EPS 64;
BA_ "FlexKomSigName" SG_ 1434 ECU_APPL_EPS "ECU_APPL_EPS";
BA_ "FlexKomSigStartPos" SG_ 1434 ECU_APPL_EPS 7;
BA_ "FlexKomSigStartValue" SG_ 1434 ECU_APPL_EPS "0000000000000000h";
BA_ "GenSigSendType" SG_ 1434 ECU_APPL_EPS 1;
BA_ "GenSigSNA" SG_ 1434 ECU_APPL_EPS "0h";
BA_ "FlexKomComment" SG_ 1444 ECU_APPL_HaLF "ECU to External Application";
BA_ "FlexKomIsMotorola" SG_ 1444 ECU_APPL_HaLF 1;
BA_ "FlexKomSID" SG_ 1444 ECU_APPL_HaLF 1634;
BA_ "FlexKomSigLaenge" SG_ 1444 ECU_APPL_HaLF 64;
BA_ "FlexKomSigName" SG_ 1444 ECU_APPL_HaLF "ECU_APPL_HaLF";
BA_ "FlexKomSigStartPos" SG_ 1444 ECU_APPL_HaLF 7;
BA_ "FlexKomSigStartValue" SG_ 1444 ECU_APPL_HaLF "0000000000000000h";
BA_ "GenSigSendType" SG_ 1444 ECU_APPL_HaLF 1;
BA_ "GenSigSNA" SG_ 1444 ECU_APPL_HaLF "0h";
BA_ "FlexKomComment" SG_ 1442 ECU_APPL_PTS "ECU to External Application";
BA_ "FlexKomIsMotorola" SG_ 1442 ECU_APPL_PTS 1;
BA_ "FlexKomSID" SG_ 1442 ECU_APPL_PTS 376;
BA_ "FlexKomSigLaenge" SG_ 1442 ECU_APPL_PTS 64;
BA_ "FlexKomSigName" SG_ 1442 ECU_APPL_PTS "ECU_APPL_PTS";
BA_ "FlexKomSigStartPos" SG_ 1442 ECU_APPL_PTS 7;
BA_ "FlexKomSigStartValue" SG_ 1442 ECU_APPL_PTS "0000000000000000h";
BA_ "GenSigSendType" SG_ 1442 ECU_APPL_PTS 1;
BA_ "GenSigSNA" SG_ 1442 ECU_APPL_PTS "0h";
BA_ "FlexKomComment" SG_ 993 DISPLACEMENT "Engine Configuration Information";
BA_ "FlexKomIsMotorola" SG_ 993 DISPLACEMENT 1;
BA_ "FlexKomSID" SG_ 993 DISPLACEMENT 617;
BA_ "FlexKomSigLaenge" SG_ 993 DISPLACEMENT 32;
BA_ "FlexKomSigName" SG_ 993 DISPLACEMENT "ENG_CFG";
BA_ "FlexKomSigStartPos" SG_ 993 DISPLACEMENT 7;
BA_ "FlexKomSigStartValue" SG_ 993 DISPLACEMENT "FFEFE7E7h";
BA_ "GenSigCycleTime" SG_ 993 DISPLACEMENT 100;
BA_ "GenSigSNA" SG_ 993 DISPLACEMENT "FFh";
BA_ "GenSigStartValue" SG_ 993 DISPLACEMENT 255;
BA_ "GenSigTimeout_CBC" SG_ 993 DISPLACEMENT 1050;
BA_ "GenSigTimeout_EPS" SG_ 993 DISPLACEMENT 1050;
BA_ "GenSigTimeout_ETM" SG_ 993 DISPLACEMENT 1050;
BA_ "GenSigTimeout_IC" SG_ 993 DISPLACEMENT 1050;
BA_ "GenSigTimeout_ORC" SG_ 993 DISPLACEMENT 350;
BA_ "RID" SG_ 993 DISPLACEMENT "1899";
BA_ "FlexKomComment" SG_ 993 ECM_Vehi_Type "Engine Configuration Information";
BA_ "FlexKomIsMotorola" SG_ 993 ECM_Vehi_Type 1;
BA_ "FlexKomSID" SG_ 993 ECM_Vehi_Type 617;
BA_ "FlexKomSigLaenge" SG_ 993 ECM_Vehi_Type 32;
BA_ "FlexKomSigName" SG_ 993 ECM_Vehi_Type "ENG_CFG";
BA_ "FlexKomSigStartPos" SG_ 993 ECM_Vehi_Type 7;
BA_ "FlexKomSigStartValue" SG_ 993 ECM_Vehi_Type "FFEFE7E7h";
BA_ "GenSigCycleTime" SG_ 993 ECM_Vehi_Type 100;
BA_ "GenSigSNA" SG_ 993 ECM_Vehi_Type "3h";
BA_ "GenSigTimeout_IC" SG_ 993 ECM_Vehi_Type 1050;
BA_ "FlexKomComment" SG_ 993 ENG_ASP "Engine Configuration Information";
BA_ "FlexKomIsMotorola" SG_ 993 ENG_ASP 1;
BA_ "FlexKomSID" SG_ 993 ENG_ASP 617;
BA_ "FlexKomSigLaenge" SG_ 993 ENG_ASP 32;
BA_ "FlexKomSigName" SG_ 993 ENG_ASP "ENG_CFG";
BA_ "FlexKomSigStartPos" SG_ 993 ENG_ASP 7;
BA_ "FlexKomSigStartValue" SG_ 993 ENG_ASP "FFEFE7E7h";
BA_ "GenSigCycleTime" SG_ 993 ENG_ASP 100;
BA_ "GenSigSNA" SG_ 993 ENG_ASP "7h";
BA_ "GenSigStartValue" SG_ 993 ENG_ASP 7;
BA_ "GenSigTimeout_ETM" SG_ 993 ENG_ASP 1050;
BA_ "FlexKomComment" SG_ 993 ETC_PRSNT "Engine Configuration Information";
BA_ "FlexKomIsMotorola" SG_ 993 ETC_PRSNT 1;
BA_ "FlexKomSID" SG_ 993 ETC_PRSNT 617;
BA_ "FlexKomSigLaenge" SG_ 993 ETC_PRSNT 32;
BA_ "FlexKomSigName" SG_ 993 ETC_PRSNT "ENG_CFG";
BA_ "FlexKomSigStartPos" SG_ 993 ETC_PRSNT 7;
BA_ "FlexKomSigStartValue" SG_ 993 ETC_PRSNT "FFEFE7E7h";
BA_ "GenSigCycleTime" SG_ 993 ETC_PRSNT 100;
BA_ "GenSigSNA" SG_ 993 ETC_PRSNT "0h";
BA_ "GenSigTimeout_IC" SG_ 993 ETC_PRSNT 1050;
BA_ "FlexKomComment" SG_ 993 EngStyle "Engine Configuration Information";
BA_ "FlexKomIsMotorola" SG_ 993 EngStyle 1;
BA_ "FlexKomSID" SG_ 993 EngStyle 617;
BA_ "FlexKomSigLaenge" SG_ 993 EngStyle 32;
BA_ "FlexKomSigName" SG_ 993 EngStyle "ENG_CFG";
BA_ "FlexKomSigStartPos" SG_ 993 EngStyle 7;
BA_ "FlexKomSigStartValue" SG_ 993 EngStyle "FFEFE7E7h";
BA_ "GenSigCycleTime" SG_ 993 EngStyle 100;
BA_ "GenSigSNA" SG_ 993 EngStyle "7h";
BA_ "GenSigStartValue" SG_ 993 EngStyle 7;
BA_ "GenSigTimeout_CBC" SG_ 993 EngStyle 1050;
BA_ "RID" SG_ 993 EngStyle "1062";
BA_ "FlexKomComment" SG_ 993 FUEL_TYPE "Engine Configuration Information";
BA_ "FlexKomIsMotorola" SG_ 993 FUEL_TYPE 1;
BA_ "FlexKomSID" SG_ 993 FUEL_TYPE 617;
BA_ "FlexKomSigLaenge" SG_ 993 FUEL_TYPE 32;
BA_ "FlexKomSigName" SG_ 993 FUEL_TYPE "ENG_CFG";
BA_ "FlexKomSigStartPos" SG_ 993 FUEL_TYPE 7;
BA_ "FlexKomSigStartValue" SG_ 993 FUEL_TYPE "FFEFE7E7h";
BA_ "GenSigCycleTime" SG_ 993 FUEL_TYPE 100;
BA_ "GenSigSNA" SG_ 993 FUEL_TYPE "7h";
BA_ "GenSigStartValue" SG_ 993 FUEL_TYPE 7;
BA_ "GenSigTimeout_CBC" SG_ 993 FUEL_TYPE 1050;
BA_ "GenSigTimeout_IC" SG_ 993 FUEL_TYPE 1050;
BA_ "GenSigTimeout_ORC" SG_ 993 FUEL_TYPE 350;
BA_ "RID" SG_ 993 FUEL_TYPE "1261";
BA_ "FlexKomComment" SG_ 993 Manufacture "Engine Configuration Information";
BA_ "FlexKomIsMotorola" SG_ 993 Manufacture 1;
BA_ "FlexKomSID" SG_ 993 Manufacture 617;
BA_ "FlexKomSigLaenge" SG_ 993 Manufacture 32;
BA_ "FlexKomSigName" SG_ 993 Manufacture "ENG_CFG";
BA_ "FlexKomSigStartPos" SG_ 993 Manufacture 7;
BA_ "FlexKomSigStartValue" SG_ 993 Manufacture "FFEFE7E7h";
BA_ "GenSigCycleTime" SG_ 993 Manufacture 100;
BA_ "GenSigSNA" SG_ 993 Manufacture "7h";
BA_ "GenSigStartValue" SG_ 993 Manufacture 7;
BA_ "FlexKomComment" SG_ 993 NUM_CYL "Engine Configuration Information";
BA_ "FlexKomIsMotorola" SG_ 993 NUM_CYL 1;
BA_ "FlexKomSID" SG_ 993 NUM_CYL 617;
BA_ "FlexKomSigLaenge" SG_ 993 NUM_CYL 32;
BA_ "FlexKomSigName" SG_ 993 NUM_CYL "ENG_CFG";
BA_ "FlexKomSigStartPos" SG_ 993 NUM_CYL 7;
BA_ "FlexKomSigStartValue" SG_ 993 NUM_CYL "FFEFE7E7h";
BA_ "GenSigCycleTime" SG_ 993 NUM_CYL 100;
BA_ "GenSigSNA" SG_ 993 NUM_CYL "Fh";
BA_ "GenSigStartValue" SG_ 993 NUM_CYL 15;
BA_ "FlexKomComment" SG_ 993 NUM_VALVE "Engine Configuration Information";
BA_ "FlexKomIsMotorola" SG_ 993 NUM_VALVE 1;
BA_ "FlexKomSID" SG_ 993 NUM_VALVE 617;
BA_ "FlexKomSigLaenge" SG_ 993 NUM_VALVE 32;
BA_ "FlexKomSigName" SG_ 993 NUM_VALVE "ENG_CFG";
BA_ "FlexKomSigStartPos" SG_ 993 NUM_VALVE 7;
BA_ "FlexKomSigStartValue" SG_ 993 NUM_VALVE "FFEFE7E7h";
BA_ "GenSigCycleTime" SG_ 993 NUM_VALVE 100;
BA_ "GenSigSNA" SG_ 993 NUM_VALVE "7h";
BA_ "GenSigStartValue" SG_ 993 NUM_VALVE 7;
BA_ "FlexKomComment" SG_ 993 SpStPrsnt "Engine Configuration Information";
BA_ "FlexKomIsMotorola" SG_ 993 SpStPrsnt 1;
BA_ "FlexKomSID" SG_ 993 SpStPrsnt 617;
BA_ "FlexKomSigLaenge" SG_ 993 SpStPrsnt 32;
BA_ "FlexKomSigName" SG_ 993 SpStPrsnt "ENG_CFG";
BA_ "FlexKomSigStartPos" SG_ 993 SpStPrsnt 7;
BA_ "FlexKomSigStartValue" SG_ 993 SpStPrsnt "FFEFE7E7h";
BA_ "GenSigCycleTime" SG_ 993 SpStPrsnt 100;
BA_ "GenSigSNA" SG_ 993 SpStPrsnt "0h";
BA_ "GenSigTimeout_EPS" SG_ 993 SpStPrsnt 1050;
BA_ "GenSigTimeout_IC" SG_ 993 SpStPrsnt 1050;
BA_ "GenSigTimeout_ORC" SG_ 993 SpStPrsnt 350;
BA_ "RID" SG_ 993 SpStPrsnt "1164";
BA_ "FlexKomComment" SG_ 993 TRANS_TYPE "Engine Configuration Information";
BA_ "FlexKomIsMotorola" SG_ 993 TRANS_TYPE 1;
BA_ "FlexKomSID" SG_ 993 TRANS_TYPE 617;
BA_ "FlexKomSigLaenge" SG_ 993 TRANS_TYPE 32;
BA_ "FlexKomSigName" SG_ 993 TRANS_TYPE "ENG_CFG";
BA_ "FlexKomSigStartPos" SG_ 993 TRANS_TYPE 7;
BA_ "FlexKomSigStartValue" SG_ 993 TRANS_TYPE "FFEFE7E7h";
BA_ "GenSigCycleTime" SG_ 993 TRANS_TYPE 100;
BA_ "GenSigSNA" SG_ 993 TRANS_TYPE "0h";
BA_ "GenSigTimeout_IC" SG_ 993 TRANS_TYPE 1050;
BA_ "GenSigTimeout_ORC" SG_ 993 TRANS_TYPE 350;
BA_ "RID" SG_ 993 TRANS_TYPE "1094";
BA_ "FlexKomComment" SG_ 770 AutoParkSts "EPB_1 message packet";
BA_ "FlexKomIsMotorola" SG_ 770 AutoParkSts 1;
BA_ "FlexKomSID" SG_ 770 AutoParkSts 2083;
BA_ "FlexKomSigLaenge" SG_ 770 AutoParkSts 64;
BA_ "FlexKomSigName" SG_ 770 AutoParkSts "EPB_1";
BA_ "FlexKomSigStartPos" SG_ 770 AutoParkSts 7;
BA_ "FlexKomSigStartValue" SG_ 770 AutoParkSts "00000000000000FFh";
BA_ "GenSigCycleTime" SG_ 770 AutoParkSts 250;
BA_ "GenSigSNA" SG_ 770 AutoParkSts "3h";
BA_ "GenSigTimeout_IC" SG_ 770 AutoParkSts 2625;
BA_ "RID" SG_ 770 AutoParkSts "2161";
BA_ "FlexKomComment" SG_ 770 CRC_EPB_1 "EPB_1 message packet";
BA_ "FlexKomIsMotorola" SG_ 770 CRC_EPB_1 1;
BA_ "FlexKomSID" SG_ 770 CRC_EPB_1 2083;
BA_ "FlexKomSigLaenge" SG_ 770 CRC_EPB_1 64;
BA_ "FlexKomSigName" SG_ 770 CRC_EPB_1 "EPB_1";
BA_ "FlexKomSigStartPos" SG_ 770 CRC_EPB_1 7;
BA_ "FlexKomSigStartValue" SG_ 770 CRC_EPB_1 "00000000000000FFh";
BA_ "GenSigCycleTime" SG_ 770 CRC_EPB_1 250;
BA_ "GenSigSNA" SG_ 770 CRC_EPB_1 "FFh";
BA_ "GenSigStartValue" SG_ 770 CRC_EPB_1 255;
BA_ "GenSigTimeout_IC" SG_ 770 CRC_EPB_1 2625;
BA_ "FlexKomComment" SG_ 770 ClampForce "EPB_1 message packet";
BA_ "FlexKomIsMotorola" SG_ 770 ClampForce 1;
BA_ "FlexKomSID" SG_ 770 ClampForce 2083;
BA_ "FlexKomSigLaenge" SG_ 770 ClampForce 64;
BA_ "FlexKomSigName" SG_ 770 ClampForce "EPB_1";
BA_ "FlexKomSigStartPos" SG_ 770 ClampForce 7;
BA_ "FlexKomSigStartValue" SG_ 770 ClampForce "00000000000000FFh";
BA_ "GenSigCycleTime" SG_ 770 ClampForce 250;
BA_ "GenSigSNA" SG_ 770 ClampForce "0h";
BA_ "GenSigTimeout_IC" SG_ 770 ClampForce 2625;
BA_ "GenSigTimeout_ORC" SG_ 770 ClampForce 875;
BA_ "FlexKomComment" SG_ 770 EPBSts "EPB_1 message packet";
BA_ "FlexKomIsMotorola" SG_ 770 EPBSts 1;
BA_ "FlexKomSID" SG_ 770 EPBSts 2083;
BA_ "FlexKomSigLaenge" SG_ 770 EPBSts 64;
BA_ "FlexKomSigName" SG_ 770 EPBSts "EPB_1";
BA_ "FlexKomSigStartPos" SG_ 770 EPBSts 7;
BA_ "FlexKomSigStartValue" SG_ 770 EPBSts "00000000000000FFh";
BA_ "GenSigCycleTime" SG_ 770 EPBSts 250;
BA_ "GenSigSNA" SG_ 770 EPBSts "0h";
BA_ "GenSigTimeout_IC" SG_ 770 EPBSts 2625;
BA_ "GenSigTimeout_ORC" SG_ 770 EPBSts 875;
BA_ "FlexKomComment" SG_ 770 EPBWarningLampReq "EPB_1 message packet";
BA_ "FlexKomIsMotorola" SG_ 770 EPBWarningLampReq 1;
BA_ "FlexKomSID" SG_ 770 EPBWarningLampReq 2083;
BA_ "FlexKomSigLaenge" SG_ 770 EPBWarningLampReq 64;
BA_ "FlexKomSigName" SG_ 770 EPBWarningLampReq "EPB_1";
BA_ "FlexKomSigStartPos" SG_ 770 EPBWarningLampReq 7;
BA_ "FlexKomSigStartValue" SG_ 770 EPBWarningLampReq "00000000000000FFh";
BA_ "GenSigCycleTime" SG_ 770 EPBWarningLampReq 250;
BA_ "GenSigSNA" SG_ 770 EPBWarningLampReq "3h";
BA_ "GenSigTimeout_IC" SG_ 770 EPBWarningLampReq 2625;
BA_ "GenSigTimeout_ORC" SG_ 770 EPBWarningLampReq 875;
BA_ "FlexKomComment" SG_ 770 EPB_Sw_Stat "EPB_1 message packet";
BA_ "FlexKomIsMotorola" SG_ 770 EPB_Sw_Stat 1;
BA_ "FlexKomSID" SG_ 770 EPB_Sw_Stat 2083;
BA_ "FlexKomSigLaenge" SG_ 770 EPB_Sw_Stat 64;
BA_ "FlexKomSigName" SG_ 770 EPB_Sw_Stat "EPB_1";
BA_ "FlexKomSigStartPos" SG_ 770 EPB_Sw_Stat 7;
BA_ "FlexKomSigStartValue" SG_ 770 EPB_Sw_Stat "00000000000000FFh";
BA_ "GenSigCycleTime" SG_ 770 EPB_Sw_Stat 250;
BA_ "GenSigSNA" SG_ 770 EPB_Sw_Stat "3h";
BA_ "GenSigTimeout_IC" SG_ 770 EPB_Sw_Stat 2625;
BA_ "GenSigTimeout_ORC" SG_ 770 EPB_Sw_Stat 875;
BA_ "FlexKomComment" SG_ 770 FunctionLamp "EPB_1 message packet";
BA_ "FlexKomIsMotorola" SG_ 770 FunctionLamp 1;
BA_ "FlexKomSID" SG_ 770 FunctionLamp 2083;
BA_ "FlexKomSigLaenge" SG_ 770 FunctionLamp 64;
BA_ "FlexKomSigName" SG_ 770 FunctionLamp "EPB_1";
BA_ "FlexKomSigStartPos" SG_ 770 FunctionLamp 7;
BA_ "FlexKomSigStartValue" SG_ 770 FunctionLamp "00000000000000FFh";
BA_ "GenSigCycleTime" SG_ 770 FunctionLamp 250;
BA_ "GenSigSNA" SG_ 770 FunctionLamp "3h";
BA_ "GenSigTimeout_IC" SG_ 770 FunctionLamp 2625;
BA_ "FlexKomComment" SG_ 770 MC_EPB_1 "EPB_1 message packet";
BA_ "FlexKomIsMotorola" SG_ 770 MC_EPB_1 1;
BA_ "FlexKomSID" SG_ 770 MC_EPB_1 2083;
BA_ "FlexKomSigLaenge" SG_ 770 MC_EPB_1 64;
BA_ "FlexKomSigName" SG_ 770 MC_EPB_1 "EPB_1";
BA_ "FlexKomSigStartPos" SG_ 770 MC_EPB_1 7;
BA_ "FlexKomSigStartValue" SG_ 770 MC_EPB_1 "00000000000000FFh";
BA_ "GenSigCycleTime" SG_ 770 MC_EPB_1 250;
BA_ "GenSigSNA" SG_ 770 MC_EPB_1 "0h";
BA_ "GenSigTimeout_IC" SG_ 770 MC_EPB_1 2625;
BA_ "RID" SG_ 770 MC_EPB_1 "9772";
BA_ "FlexKomComment" SG_ 770 ServiceModeSts "EPB_1 message packet";
BA_ "FlexKomIsMotorola" SG_ 770 ServiceModeSts 1;
BA_ "FlexKomSID" SG_ 770 ServiceModeSts 2083;
BA_ "FlexKomSigLaenge" SG_ 770 ServiceModeSts 64;
BA_ "FlexKomSigName" SG_ 770 ServiceModeSts "EPB_1";
BA_ "FlexKomSigStartPos" SG_ 770 ServiceModeSts 7;
BA_ "FlexKomSigStartValue" SG_ 770 ServiceModeSts "00000000000000FFh";
BA_ "GenSigCycleTime" SG_ 770 ServiceModeSts 250;
BA_ "GenSigSNA" SG_ 770 ServiceModeSts "0h";
BA_ "GenSigTimeout_IC" SG_ 770 ServiceModeSts 2625;
BA_ "RID" SG_ 770 ServiceModeSts "2162";
BA_ "FlexKomComment" SG_ 770 TextDisplay "EPB_1 message packet";
BA_ "FlexKomIsMotorola" SG_ 770 TextDisplay 1;
BA_ "FlexKomSID" SG_ 770 TextDisplay 2083;
BA_ "FlexKomSigLaenge" SG_ 770 TextDisplay 64;
BA_ "FlexKomSigName" SG_ 770 TextDisplay "EPB_1";
BA_ "FlexKomSigStartPos" SG_ 770 TextDisplay 7;
BA_ "FlexKomSigStartValue" SG_ 770 TextDisplay "00000000000000FFh";
BA_ "GenSigCycleTime" SG_ 770 TextDisplay 250;
BA_ "GenSigSNA" SG_ 770 TextDisplay "1Fh";
BA_ "GenSigTimeout_IC" SG_ 770 TextDisplay 2625;
BA_ "RID" SG_ 770 TextDisplay "2158";
BA_ "FlexKomComment" SG_ 669 CRC_EPB_A1 "EPB_A1 message packet";
BA_ "FlexKomIsMotorola" SG_ 669 CRC_EPB_A1 1;
BA_ "FlexKomSID" SG_ 669 CRC_EPB_A1 2013;
BA_ "FlexKomSigLaenge" SG_ 669 CRC_EPB_A1 24;
BA_ "FlexKomSigName" SG_ 669 CRC_EPB_A1 "EPB_A1_Pkt";
BA_ "FlexKomSigStartPos" SG_ 669 CRC_EPB_A1 7;
BA_ "FlexKomSigStartValue" SG_ 669 CRC_EPB_A1 "0000FFh";
BA_ "GenSigCycleTime" SG_ 669 CRC_EPB_A1 40;
BA_ "GenSigSNA" SG_ 669 CRC_EPB_A1 "FFh";
BA_ "GenSigStartValue" SG_ 669 CRC_EPB_A1 255;
BA_ "FlexKomComment" SG_ 669 EPBActivation "EPB_A1 message packet";
BA_ "FlexKomIsMotorola" SG_ 669 EPBActivation 1;
BA_ "FlexKomSID" SG_ 669 EPBActivation 2013;
BA_ "FlexKomSigLaenge" SG_ 669 EPBActivation 24;
BA_ "FlexKomSigName" SG_ 669 EPBActivation "EPB_A1_Pkt";
BA_ "FlexKomSigStartPos" SG_ 669 EPBActivation 7;
BA_ "FlexKomSigStartValue" SG_ 669 EPBActivation "0000FFh";
BA_ "GenSigCycleTime" SG_ 669 EPBActivation 40;
BA_ "GenSigSNA" SG_ 669 EPBActivation "1Fh";
BA_ "FlexKomComment" SG_ 669 EPBHoldSts "EPB_A1 message packet";
BA_ "FlexKomIsMotorola" SG_ 669 EPBHoldSts 1;
BA_ "FlexKomSID" SG_ 669 EPBHoldSts 2013;
BA_ "FlexKomSigLaenge" SG_ 669 EPBHoldSts 24;
BA_ "FlexKomSigName" SG_ 669 EPBHoldSts "EPB_A1_Pkt";
BA_ "FlexKomSigStartPos" SG_ 669 EPBHoldSts 7;
BA_ "FlexKomSigStartValue" SG_ 669 EPBHoldSts "0000FFh";
BA_ "GenSigCycleTime" SG_ 669 EPBHoldSts 40;
BA_ "GenSigSNA" SG_ 669 EPBHoldSts "0h";
BA_ "GenSigTimeout_ORC" SG_ 669 EPBHoldSts 140;
BA_ "RID" SG_ 669 EPBHoldSts "2160";
BA_ "FlexKomComment" SG_ 669 MC_EPB_A1 "EPB_A1 message packet";
BA_ "FlexKomIsMotorola" SG_ 669 MC_EPB_A1 1;
BA_ "FlexKomSID" SG_ 669 MC_EPB_A1 2013;
BA_ "FlexKomSigLaenge" SG_ 669 MC_EPB_A1 24;
BA_ "FlexKomSigName" SG_ 669 MC_EPB_A1 "EPB_A1_Pkt";
BA_ "FlexKomSigStartPos" SG_ 669 MC_EPB_A1 7;
BA_ "FlexKomSigStartValue" SG_ 669 MC_EPB_A1 "0000FFh";
BA_ "GenSigCycleTime" SG_ 669 MC_EPB_A1 40;
BA_ "GenSigSNA" SG_ 669 MC_EPB_A1 "0h";
BA_ "RID" SG_ 669 MC_EPB_A1 "9774";
BA_ "FlexKomComment" SG_ 544 CRC_EPS_1 "EPS_1 packet";
BA_ "FlexKomIsMotorola" SG_ 544 CRC_EPS_1 1;
BA_ "FlexKomSID" SG_ 544 CRC_EPS_1 1415;
BA_ "FlexKomSigLaenge" SG_ 544 CRC_EPS_1 64;
BA_ "FlexKomSigName" SG_ 544 CRC_EPS_1 "EPS_1_PKT";
BA_ "FlexKomSigStartPos" SG_ 544 CRC_EPS_1 7;
BA_ "FlexKomSigStartValue" SG_ 544 CRC_EPS_1 "07FF07FF040000FFh";
BA_ "GenSigCycleTime" SG_ 544 CRC_EPS_1 10;
BA_ "GenSigSNA" SG_ 544 CRC_EPS_1 "FFh";
BA_ "GenSigStartValue" SG_ 544 CRC_EPS_1 255;
BA_ "GenSigTimeout_HaLF" SG_ 544 CRC_EPS_1 105;
BA_ "GenSigTimeout_PTS" SG_ 544 CRC_EPS_1 105;
BA_ "FlexKomComment" SG_ 544 EPSHandsOnRecognition "EPS_1 packet";
BA_ "FlexKomIsMotorola" SG_ 544 EPSHandsOnRecognition 1;
BA_ "FlexKomSID" SG_ 544 EPSHandsOnRecognition 1415;
BA_ "FlexKomSigLaenge" SG_ 544 EPSHandsOnRecognition 64;
BA_ "FlexKomSigName" SG_ 544 EPSHandsOnRecognition "EPS_1_PKT";
BA_ "FlexKomSigStartPos" SG_ 544 EPSHandsOnRecognition 7;
BA_ "FlexKomSigStartValue" SG_ 544 EPSHandsOnRecognition "07FF07FF040000FFh";
BA_ "GenSigCycleTime" SG_ 544 EPSHandsOnRecognition 10;
BA_ "GenSigSNA" SG_ 544 EPSHandsOnRecognition "0h";
BA_ "GenSigTimeout_HaLF" SG_ 544 EPSHandsOnRecognition 105;
BA_ "GenSigTimeout_PTS" SG_ 544 EPSHandsOnRecognition 105;
BA_ "FlexKomComment" SG_ 544 EPSMotorTorque "EPS_1 packet";
BA_ "FlexKomIsMotorola" SG_ 544 EPSMotorTorque 1;
BA_ "FlexKomSID" SG_ 544 EPSMotorTorque 1415;
BA_ "FlexKomSigLaenge" SG_ 544 EPSMotorTorque 64;
BA_ "FlexKomSigName" SG_ 544 EPSMotorTorque "EPS_1_PKT";
BA_ "FlexKomSigStartPos" SG_ 544 EPSMotorTorque 7;
BA_ "FlexKomSigStartValue" SG_ 544 EPSMotorTorque "07FF07FF040000FFh";
BA_ "GenSigCycleTime" SG_ 544 EPSMotorTorque 10;
BA_ "GenSigSNA" SG_ 544 EPSMotorTorque "400h";
BA_ "GenSigStartValue" SG_ 544 EPSMotorTorque 1024;
BA_ "GenSigTimeout_HaLF" SG_ 544 EPSMotorTorque 105;
BA_ "FlexKomComment" SG_ 544 EPSMotorTorqueExtRng "EPS_1 packet";
BA_ "FlexKomIsMotorola" SG_ 544 EPSMotorTorqueExtRng 1;
BA_ "FlexKomSID" SG_ 544 EPSMotorTorqueExtRng 1415;
BA_ "FlexKomSigLaenge" SG_ 544 EPSMotorTorqueExtRng 64;
BA_ "FlexKomSigName" SG_ 544 EPSMotorTorqueExtRng "EPS_1_PKT";
BA_ "FlexKomSigStartPos" SG_ 544 EPSMotorTorqueExtRng 7;
BA_ "FlexKomSigStartValue" SG_ 544 EPSMotorTorqueExtRng "07FF07FF040000FFh";
BA_ "GenSigCycleTime" SG_ 544 EPSMotorTorqueExtRng 10;
BA_ "GenSigSNA" SG_ 544 EPSMotorTorqueExtRng "7FFh";
BA_ "GenSigStartValue" SG_ 544 EPSMotorTorqueExtRng 2047;
BA_ "FlexKomComment" SG_ 544 EPSMotorTorqueValidData "EPS_1 packet";
BA_ "FlexKomIsMotorola" SG_ 544 EPSMotorTorqueValidData 1;
BA_ "FlexKomSID" SG_ 544 EPSMotorTorqueValidData 1415;
BA_ "FlexKomSigLaenge" SG_ 544 EPSMotorTorqueValidData 64;
BA_ "FlexKomSigName" SG_ 544 EPSMotorTorqueValidData "EPS_1_PKT";
BA_ "FlexKomSigStartPos" SG_ 544 EPSMotorTorqueValidData 7;
BA_ "FlexKomSigStartValue" SG_ 544 EPSMotorTorqueValidData "07FF07FF040000FFh";
BA_ "GenSigCycleTime" SG_ 544 EPSMotorTorqueValidData 10;
BA_ "GenSigSNA" SG_ 544 EPSMotorTorqueValidData "0h";
BA_ "GenSigTimeout_HaLF" SG_ 544 EPSMotorTorqueValidData 105;
BA_ "FlexKomComment" SG_ 544 EPSTemporaryDeactivationLDW "EPS_1 packet";
BA_ "FlexKomIsMotorola" SG_ 544 EPSTemporaryDeactivationLDW 1;
BA_ "FlexKomSID" SG_ 544 EPSTemporaryDeactivationLDW 1415;
BA_ "FlexKomSigLaenge" SG_ 544 EPSTemporaryDeactivationLDW 64;
BA_ "FlexKomSigName" SG_ 544 EPSTemporaryDeactivationLDW "EPS_1_PKT";
BA_ "FlexKomSigStartPos" SG_ 544 EPSTemporaryDeactivationLDW 7;
BA_ "FlexKomSigStartValue" SG_ 544 EPSTemporaryDeactivationLDW "07FF07FF040000FFh";
BA_ "GenSigCycleTime" SG_ 544 EPSTemporaryDeactivationLDW 10;
BA_ "GenSigSNA" SG_ 544 EPSTemporaryDeactivationLDW "0h";
BA_ "FlexKomComment" SG_ 544 EPSTemporaryDeactivationPPPA "EPS_1 packet";
BA_ "FlexKomIsMotorola" SG_ 544 EPSTemporaryDeactivationPPPA 1;
BA_ "FlexKomSID" SG_ 544 EPSTemporaryDeactivationPPPA 1415;
BA_ "FlexKomSigLaenge" SG_ 544 EPSTemporaryDeactivationPPPA 64;
BA_ "FlexKomSigName" SG_ 544 EPSTemporaryDeactivationPPPA "EPS_1_PKT";
BA_ "FlexKomSigStartPos" SG_ 544 EPSTemporaryDeactivationPPPA 7;
BA_ "FlexKomSigStartValue" SG_ 544 EPSTemporaryDeactivationPPPA "07FF07FF040000FFh";
BA_ "GenSigCycleTime" SG_ 544 EPSTemporaryDeactivationPPPA 10;
BA_ "GenSigSNA" SG_ 544 EPSTemporaryDeactivationPPPA "0h";
BA_ "GenSigTimeout_HaLF" SG_ 544 EPSTemporaryDeactivationPPPA 105;
BA_ "GenSigTimeout_PTS" SG_ 544 EPSTemporaryDeactivationPPPA 105;
BA_ "FlexKomComment" SG_ 544 HALFTorqueOverlayFault "EPS_1 packet";
BA_ "FlexKomIsMotorola" SG_ 544 HALFTorqueOverlayFault 1;
BA_ "FlexKomSID" SG_ 544 HALFTorqueOverlayFault 1415;
BA_ "FlexKomSigLaenge" SG_ 544 HALFTorqueOverlayFault 64;
BA_ "FlexKomSigName" SG_ 544 HALFTorqueOverlayFault "EPS_1_PKT";
BA_ "FlexKomSigStartPos" SG_ 544 HALFTorqueOverlayFault 7;
BA_ "FlexKomSigStartValue" SG_ 544 HALFTorqueOverlayFault "07FF07FF040000FFh";
BA_ "GenSigCycleTime" SG_ 544 HALFTorqueOverlayFault 10;
BA_ "GenSigSNA" SG_ 544 HALFTorqueOverlayFault "0h";
BA_ "GenSigTimeout_HaLF" SG_ 544 HALFTorqueOverlayFault 105;
BA_ "GenSigTimeout_PTS" SG_ 544 HALFTorqueOverlayFault 105;
BA_ "FlexKomComment" SG_ 544 HALFTorqueOverlayIntActivated "EPS_1 packet";
BA_ "FlexKomIsMotorola" SG_ 544 HALFTorqueOverlayIntActivated 1;
BA_ "FlexKomSID" SG_ 544 HALFTorqueOverlayIntActivated 1415;
BA_ "FlexKomSigLaenge" SG_ 544 HALFTorqueOverlayIntActivated 64;
BA_ "FlexKomSigName" SG_ 544 HALFTorqueOverlayIntActivated "EPS_1_PKT";
BA_ "FlexKomSigStartPos" SG_ 544 HALFTorqueOverlayIntActivated 7;
BA_ "FlexKomSigStartValue" SG_ 544 HALFTorqueOverlayIntActivated "07FF07FF040000FFh";
BA_ "GenSigCycleTime" SG_ 544 HALFTorqueOverlayIntActivated 10;
BA_ "GenSigSNA" SG_ 544 HALFTorqueOverlayIntActivated "0h";
BA_ "GenSigTimeout_HaLF" SG_ 544 HALFTorqueOverlayIntActivated 105;
BA_ "GenSigTimeout_PTS" SG_ 544 HALFTorqueOverlayIntActivated 105;
BA_ "FlexKomComment" SG_ 544 MC_EPS_1 "EPS_1 packet";
BA_ "FlexKomIsMotorola" SG_ 544 MC_EPS_1 1;
BA_ "FlexKomSID" SG_ 544 MC_EPS_1 1415;
BA_ "FlexKomSigLaenge" SG_ 544 MC_EPS_1 64;
BA_ "FlexKomSigName" SG_ 544 MC_EPS_1 "EPS_1_PKT";
BA_ "FlexKomSigStartPos" SG_ 544 MC_EPS_1 7;
BA_ "FlexKomSigStartValue" SG_ 544 MC_EPS_1 "07FF07FF040000FFh";
BA_ "GenSigCycleTime" SG_ 544 MC_EPS_1 10;
BA_ "GenSigSNA" SG_ 544 MC_EPS_1 "0h";
BA_ "GenSigTimeout_HaLF" SG_ 544 MC_EPS_1 105;
BA_ "GenSigTimeout_PTS" SG_ 544 MC_EPS_1 105;
BA_ "FlexKomComment" SG_ 544 PTSDriveStyleSts "EPS_1 packet";
BA_ "FlexKomIsMotorola" SG_ 544 PTSDriveStyleSts 1;
BA_ "FlexKomSID" SG_ 544 PTSDriveStyleSts 1415;
BA_ "FlexKomSigLaenge" SG_ 544 PTSDriveStyleSts 64;
BA_ "FlexKomSigName" SG_ 544 PTSDriveStyleSts "EPS_1_PKT";
BA_ "FlexKomSigStartPos" SG_ 544 PTSDriveStyleSts 7;
BA_ "FlexKomSigStartValue" SG_ 544 PTSDriveStyleSts "07FF07FF040000FFh";
BA_ "GenSigCycleTime" SG_ 544 PTSDriveStyleSts 10;
BA_ "GenSigSNA" SG_ 544 PTSDriveStyleSts "0h";
BA_ "GenSigTimeout_HaLF" SG_ 544 PTSDriveStyleSts 105;
BA_ "GenSigTimeout_PTS" SG_ 544 PTSDriveStyleSts 105;
BA_ "FlexKomComment" SG_ 544 PTSTorqueOverlayFault "EPS_1 packet";
BA_ "FlexKomIsMotorola" SG_ 544 PTSTorqueOverlayFault 1;
BA_ "FlexKomSID" SG_ 544 PTSTorqueOverlayFault 1415;
BA_ "FlexKomSigLaenge" SG_ 544 PTSTorqueOverlayFault 64;
BA_ "FlexKomSigName" SG_ 544 PTSTorqueOverlayFault "EPS_1_PKT";
BA_ "FlexKomSigStartPos" SG_ 544 PTSTorqueOverlayFault 7;
BA_ "FlexKomSigStartValue" SG_ 544 PTSTorqueOverlayFault "07FF07FF040000FFh";
BA_ "GenSigCycleTime" SG_ 544 PTSTorqueOverlayFault 10;
BA_ "GenSigSNA" SG_ 544 PTSTorqueOverlayFault "0h";
BA_ "GenSigTimeout_HaLF" SG_ 544 PTSTorqueOverlayFault 105;
BA_ "GenSigTimeout_PTS" SG_ 544 PTSTorqueOverlayFault 105;
BA_ "FlexKomComment" SG_ 544 PTSTorqueOverlayIntActivated "EPS_1 packet";
BA_ "FlexKomIsMotorola" SG_ 544 PTSTorqueOverlayIntActivated 1;
BA_ "FlexKomSID" SG_ 544 PTSTorqueOverlayIntActivated 1415;
BA_ "FlexKomSigLaenge" SG_ 544 PTSTorqueOverlayIntActivated 64;
BA_ "FlexKomSigName" SG_ 544 PTSTorqueOverlayIntActivated "EPS_1_PKT";
BA_ "FlexKomSigStartPos" SG_ 544 PTSTorqueOverlayIntActivated 7;
BA_ "FlexKomSigStartValue" SG_ 544 PTSTorqueOverlayIntActivated "07FF07FF040000FFh";
BA_ "GenSigCycleTime" SG_ 544 PTSTorqueOverlayIntActivated 10;
BA_ "GenSigSNA" SG_ 544 PTSTorqueOverlayIntActivated "0h";
BA_ "GenSigTimeout_HaLF" SG_ 544 PTSTorqueOverlayIntActivated 105;
BA_ "GenSigTimeout_PTS" SG_ 544 PTSTorqueOverlayIntActivated 105;
BA_ "FlexKomComment" SG_ 544 StrClmTrq "EPS_1 packet";
BA_ "FlexKomIsMotorola" SG_ 544 StrClmTrq 1;
BA_ "FlexKomSID" SG_ 544 StrClmTrq 1415;
BA_ "FlexKomSigLaenge" SG_ 544 StrClmTrq 64;
BA_ "FlexKomSigName" SG_ 544 StrClmTrq "EPS_1_PKT";
BA_ "FlexKomSigStartPos" SG_ 544 StrClmTrq 7;
BA_ "FlexKomSigStartValue" SG_ 544 StrClmTrq "07FF07FF040000FFh";
BA_ "GenSigCycleTime" SG_ 544 StrClmTrq 10;
BA_ "GenSigSNA" SG_ 544 StrClmTrq "7FFh";
BA_ "GenSigStartValue" SG_ 544 StrClmTrq 2047;
BA_ "GenSigTimeout_HaLF" SG_ 544 StrClmTrq 105;
BA_ "GenSigTimeout_PTS" SG_ 544 StrClmTrq 105;
BA_ "FlexKomComment" SG_ 544 StrClmTrqVD "EPS_1 packet";
BA_ "FlexKomIsMotorola" SG_ 544 StrClmTrqVD 1;
BA_ "FlexKomSID" SG_ 544 StrClmTrqVD 1415;
BA_ "FlexKomSigLaenge" SG_ 544 StrClmTrqVD 64;
BA_ "FlexKomSigName" SG_ 544 StrClmTrqVD "EPS_1_PKT";
BA_ "FlexKomSigStartPos" SG_ 544 StrClmTrqVD 7;
BA_ "FlexKomSigStartValue" SG_ 544 StrClmTrqVD "07FF07FF040000FFh";
BA_ "GenSigCycleTime" SG_ 544 StrClmTrqVD 10;
BA_ "GenSigSNA" SG_ 544 StrClmTrqVD "0h";
BA_ "GenSigTimeout_HaLF" SG_ 544 StrClmTrqVD 105;
BA_ "GenSigTimeout_PTS" SG_ 544 StrClmTrqVD 105;
VAL_ 501 Sm_ICON_Dspl 0 "NONE" 1 "OFF" 2 "READY_TG1" 3 "READY_TG2" 4 "READY_TG3" 5 "READY_TG4" 8 "ACC_E_NT_TG1" 9 "ACC_E_NT_TG2" 10 "ACC_E_NT_TG3" 11 "ACC_E_NT_TG4" 12 "ACC_E_WT_TG1" 13 "ACC_E_WT_TG2" 14 "ACC_E_WT_TG3" 15 "ACC_E_WT_TG4" 33 "NCC_OFF" 34 "NCC_READY" 40 "NCC_ENGAGED" 63 "SNA" ;
VAL_ 501 SetSpeed_MPH 255 "SNA" ;
VAL_ 501 SetSpeed_KPH 255 "SNA" ;
VAL_ 501 ObjIntrstDist 255 "SNA" ;
VAL_ 501 HMI_Screens 255 "SNA" ;
VAL_ 501 FCW_Error 0 "No_Error" 1 "FCW_Error" 2 "Limited_FCW" 3 "SNA" ;
VAL_ 501 ACCOnOff 0 "OFF" 1 "NCC" 2 "NCC_SET" 3 "ACC_ON" 4 "ACC_SET" 7 "SNA" ;
VAL_ 838 AS_CHIME_TYPE 0 "NONE" 1 "TYP_1" 2 "TYP_2" 3 "TYP_3" 4 "TYP_4" 5 "TYP_5" 6 "TYP_6" 7 "TYP_7" 8 "TYP_8" 9 "TYP_9" 10 "TYP_10" 11 "TYP_11" 12 "TYP_12" 13 "TYP_13" 14 "TYP_14" 15 "SNA" ;
VAL_ 168 DrvrIntndedAxleTorq 16383 "SNA" ;
VAL_ 720 BSM_CFG_STAT 0 "NT_ENB" 1 "ENB_LED" 2 "ENB_LED_CHM" 3 "SNA" ;
VAL_ 720 BSM_CFG_STAT_TeenKey 0 "NT_ENB" 1 "ENB_LED" 2 "ENB_LED_CHM" 3 "SNA" ;
VAL_ 720 BSM_LT_WRN 0 "NW" 2 "RM_LED" 3 "RBM_LED" 4 "FM_LED" 5 "FBM_LED" 7 "SNA" ;
VAL_ 720 BSM_RT_WRN 0 "NW" 2 "RM_LED" 3 "RBM_LED" 4 "FM_LED" 5 "FBM_LED" 7 "SNA" ;
VAL_ 820 DR_LK_STAT 0 "LKD" 1 "DRV_DR_UNLKD" 2 "ALL_DR_UNLKD" 3 "SNA" ;
VAL_ 820 FOB_SrchRq 0 "NO_ACT" 1 "SEARCH" 2 "RCVD_RSLT" ;
VAL_ 820 IGN_OFF_TIME_LNG 4095 "SNA" ;
VAL_ 820 PANEL_INTS 255 "SNA" ;
VAL_ 820 SHIP_STAT 0 "CUST_MD" 1 "ABBRV_MD" 2 "SHIP_MD" 3 "NOT_PROG" ;
VAL_ 274 CmdIgnStat 0 "IGN_LK" 3 "IGN_OFF_ACC" 4 "IGN_RUN" 5 "IGN_START" 7 "SNA" ;
VAL_ 274 KeyInIgn 0 "KEY_DEF" 1 "KEY_NOT_IN_IGN" 2 "KEY_IN_IGN" 3 "SNA" ;
VAL_ 274 StTyp 0 "ST_NOT_ACT" 1 "NOR_ST" 2 "TIP_ST" 3 "REM_ST" 7 "SNA" ;
VAL_ 512 AMB_TEMP_AVG 65535 "SNA" ;
VAL_ 512 AMB_TEMP_VOLT 255 "SNA" ;
VAL_ 512 AirTemp_Outsd 255 "SNA" ;
VAL_ 512 BATT_VOLT 255 "SNA" ;
VAL_ 512 FUEL_VOLT 255 "SNA" ;
VAL_ 804 RemSt_Inhibit 0 "INHIBIT_DEFAUILT" 1 "TIME_OUT_RUN" 2 "TIME_OUT_CUST_MODE" 3 "KEY_IN_RUN" 4 "DRV_DOOR_AJAR" 5 "PASS_DOOR_AJAR" 6 "LR_DOOR_AJAR" 7 "RR_DOOR_AJAR" 8 "START_COUNTER" 9 "FAIL_COUNTER" 10 "LOW_RPM_SHUTDOWN" 11 "KEY_IN_IGN" 12 "BRAKE_PRESSED" 13 "HAZARD_LAMP_ON" 14 "NOT_IN_PARK" 15 "VEH_SPEED_HIGH" 16 "HOOD_AJAR" 17 "TRUNK_LIFTGATE" 18 "VTA_ALARM" 19 "PANIC_MODE" 20 "BATT_VOLT_HIGH" 21 "BATT_VOLT_LOW" 22 "POWER_LOSS" 23 "MIL_ON" 24 "OIL_PRESSURE_LOW" 25 "COOLANT_TEMP_HIGH" 26 "RPM_HIGH" 27 "CRANK_NO_START" 28 "REMOTE_OFF_RQ" 29 "RS_DISABLED_PREV" 30 "NOT_CONFIGURED" 31 "NO_HOOD_SWITCH" 32 "NO_AUTO_TRANS" 33 "NOT_ENABLED" 34 "INVALID_SKIM_KEY" 35 "IGN_SNA" 36 "IGN_NOT_LOCK" 37 "GLOW_PLUG_TIMEOUT" 38 "LOW_FUEL" 39 "ETC_LAMP_ON" 40 "LOGISTIC_MODE" 41 "COLD_START_LAMP" 42 "ESL_NOT_UNLOCK" 43 "RFHUB_HS_FAIL" 44 "PSA_Not_Active" 255 "SNA" ;
VAL_ 804 WPR_SYS_AUTO 0 "SNA" ;
VAL_ 804 WPR_SYS_FLT 0 "SNA" ;
VAL_ 804 WPR_SYS_HIGH 0 "SNA" ;
VAL_ 804 WPR_SYS_INT 0 "SNA" ;
VAL_ 804 WPR_SYS_LOW 0 "SNA" ;
VAL_ 804 WPR_SYS_MIST 0 "SNA" ;
VAL_ 804 WPR_SYS_OFF 1 "SNA" ;
VAL_ 804 WPR_SYS_WASH 0 "SNA" ;
VAL_ 788 CFG_FEATURE 0 "CFG_NONE" 1 "CFG_AUTO_LK" 2 "CFG_AUTO_UNLK" 3 "CFG_DLY_LK" 4 "CFG_DRV_FST" 5 "CFG_SOUND_LK" 6 "CFG_HORN_DUR" 7 "CFG_FLASH_LK" 8 "CFG_DrAlrPrsnt" 9 "CFG_PARK_ASSIST" 10 "CFG_LANG" 11 "CFG_US_METRIC" 12 "CFG_SRV_INTV" 13 "CFG_AUTO_WPR" 14 "CFG_HL_DLY" 15 "CFG_HL_WPR" 16 "CFG_ACC_DLY" 18 "CFG_REM_MEM" 19 "CFG_EASY_EXIT" 20 "CFG_LO_VEH" 21 "CFG_TILT_IN_REV" 22 "CFG_ILL_APRCH" 23 "CFG_ILL_ENTRY" 24 "CFG_GLBL_UP_WIN" 25 "CFG_GLBL_DN_WIN" 26 "CFG_DRL_ON" 27 "CFG_AHB" 28 "REST_FACT_DEF" 29 "CFG_CMP_CAL" 30 "CFG_CMP_VAR" 31 "CFG_VOICE_COMF" 32 "CFG_NAV_TBYT" 33 "CFG_HILL_ST" 34 "CFG_AFS" 35 "CFG_BSD" 36 "CFG_PE" 37 "CFG_WAL" 38 "CFG_DSS" 39 "CFG_SOUND_RS" 40 "CFG_DCS" 41 "CFG_AUTO_RELK" 42 "CFG_CMS" 43 "CFG_FCW" 44 "CFG_PRE_SAFE" 45 "CFG_BELT_SLAK" 46 "CFG_FUEL_SAV" 47 "CFG_FCW_SENS" 48 "CFG_HDLP_DROP" 49 "CFG_ECMM" 50 "PASS_WIN_LKOUT" 51 "AERO" 52 "JACK" 53 "CFG_TRLR" 54 "CFG_ALIGNMENT" 55 "CFG_ASCM_WMO" 57 "CFG_LDW" 58 "OIL" 59 "CFG_NORMAL_DCS" 61 "CFG_TRANSPORT" 62 "CFG_PTO_MODE" 63 "CFG_PTO_SINGLE_RPM" 64 "CFG_PTO_RPM1" 65 "CFG_PTO_RPM2" 66 "CFG_PTO_RPM3" 67 "CFG_PTO_Type" 68 "CFG_PTO_Auto_Resume" 69 "CFG_MAX_PTO_VEH_SPEED" 70 "RVC_GRID" 71 "DIMMER" 72 "RLE_LIGHT" 73 "RLE_HORN" 76 "CFG_TRLR_TYP" 77 "CFG_TRLR_NAME" 81 "CFG_PTS_FT" 82 "CFG_PTS_RR" 83 "CFG_PTS_FT_VOL" 84 "CFG_PTS_RR_VOL" 86 "CFG_PLG" 87 "CFG_AUX1" 88 "CFG_AUX2" 89 "CFG_AUX3" 90 "CFG_AUX4" 91 "CFG_AUX5" 93 "CFG_LDWTRQ" 94 "CFG_PTO_REM_Throttle" 95 "CFG_UNIT_DEFAULT" 96 "CFG_PressureUnit" 97 "CFG_SpeedUnit" 98 "CFG_DistanceUnit" 99 "CFG_ConsumptionUnit" 100 "CFG_CapacityUnit" 101 "CFG_TemperatureUnit" 102 "CFG_PowerUnit" 103 "CFG_TorqueUnit" 104 "CFG_EPS" 105 "CFG_CHMSL_LINES" 106 "CFG_POLICE_PE" 107 "EPB_AUTO_PRK" 108 "EPB_SERVICE" 109 "HOLD_N_GO" 110 "PWR_FLD_MRR" 111 "HANDS_FREE_LFT" 112 "HANDS_FREE_SLDR" 113 "SVC_GRIDLINES" 114 "SVC_DELAY" 115 "SLD_DR_ALRT" 116 "TEEN_FCW_SENS" 117 "TEEN_FCW_BRK" 118 "TEEN_PRK_ASST" 119 "TEEN_PRK_ASST_BRK" 120 "TEEN_FT_PRK_VOL" 121 "TEEN_RR_PRK_VOL" 122 "TEEN_MAX_SPEED" 123 "TEEN_FUEL_WRN" 124 "TEEN_FUEL_POPUP" 125 "TEEN_BLIND_SPOT" 126 "TEEN_RAIN_WPR" 127 "TEEN_AUTO_HB" 128 "TEEN_LGHT_WPR" 129 "TEEN_SLD_DR_ALRT" 130 "TEEN_PLG_CHIME" 131 "SLD_DR_CHM" 132 "TEEN_SLD_DR_CHM" 133 "CFG_ABSM" 134 "CFG_PADDLE_SHIFT" 137 "CFG_PRK_ASST_BRK" 138 "CFG_LDW_ON" 139 "CFG_PRK_ASST_TYPE" 140 "CFG_DR_ALR" 141 "CFG_RDY_DRV" 142 "CFG_PANEL_INTS" 143 "CFG_MOOD_LGT_INTS" 144 "CFG_ML_HDLP_LVL" 145 "CFG_BSM_TRLR" 146 "CFG_AUTO_SS" 147 "CFG_PCS" 148 "CFG_UNIT_SET" 149 "CFG_DOORS_OFF_ACC_DLY" 150 "CFG_MOTORIZED_SEATBELT" 151 "CFG_MOTORIZED_SEATBELT_STRN" 152 "CFG_TSI" 153 "CFG_LKA" 154 "CFG_LKA_SENS" 155 "CFG_LKA_STRN" 156 "CFG_ABSD" 157 "CFG_ABSD_SENS" 158 "CFG_ABSD_STRN" 162 "CFG_TIRE_FILL_ALERT" 163 "CFG_POWER_SIDE_STEP" 164 "CFG_AUTO_STOP_START" ;
VAL_ 788 CFG_STAT_RQ 0 "CFG_DEF" 1 "CFG_DSBL" 2 "CFG_ENBL" 3 "CFG_SPEC" ;
VAL_ 500 As_DispRq 0 "No_RQ" 1 "ACC" 2 "FCW" 3 "SNA" ;
VAL_ 500 DAS_ACCEL_Rq 4095 "SNA" ;
VAL_ 500 DAS_Rq_ID 0 "IDLE" 1 "ACC" 2 "CMS" 3 "ABA" 4 "LSCM" 5 "CMS_XTD" 6 "PEB" 7 "SNA" ;
VAL_ 500 DAS_Sts 0 "OK" 1 "INTERNAL" 2 "EXTERNAL" 3 "SNA" ;
VAL_ 625 FCWSetting 0 "OFF" 1 "NEAR" 2 "MEDIUM" 3 "FAR" ;
VAL_ 625 FCWSettingTeen 0 "OFF" 1 "NEAR" 2 "MEDIUM" 3 "FAR" ;
VAL_ 625 SDS_Engaged_State 0 "Disengaged" 1 "Engaged_with_Driver" 2 "Engaged_Driverless" 3 "SNA" ;
VAL_ 625 WhlTrqRq_DAS 32767 "SNA" ;
VAL_ 264 ECM_IMMO_STAT_CANC 0 "IS" 1 "KILL" 2 "RUN" 3 "SNA" ;
VAL_ 264 EngRPM 65535 "SNA" ;
VAL_ 288 AccelPdlPosn 255 "SNA" ;
VAL_ 760 ESS_ENG_ST 1 "ENS_STOPPED" 2 "ENS_RQ_ST" 3 "ENS_RUN" 4 "ENS_STOP_PEND" 5 "ENS_ST_PRTCT" 6 "ENS_ST_INH" 7 "ENS_DSBL" 8 "ENS_IHB_LATCH" 9 "ENS_STARTING" 10 "KEY_START" 15 "SNA" ;
VAL_ 559 ActlAccelPdlPosn 255 "SNA" ;
VAL_ 384 AM_ECM_Prsnt 0 "DEFAULT" 2 "AM_ECM_PRSNT" 3 "SNA" ;
VAL_ 384 AirPress_Outsd 255 "SNA" ;
VAL_ 384 CHRG_FAIL 1 "SNA" ;
VAL_ 384 EngCoolTemp 255 "SNA" ;
VAL_ 384 IntkAirTemp 255 "SNA" ;
VAL_ 384 SysVolt 255 "SNA" ;
VAL_ 800 KeySense_DispReq 0 "NONE" 1 "WARN" 2 "SPD_LMT" ;
VAL_ 800 KeySense_SetSpdOpt 0 "NOT_PROG" 1 "OPT_1" 2 "OPT_2" 3 "OPT_3" 4 "OPT_4" 5 "OPT_5" 7 "SNA" ;
VAL_ 800 LeakCheckTimerValue 511 "SNA" ;
VAL_ 800 LeakTestSts 0 "NONE" 1 "PEND" 2 "COMPLETE" 3 "DELAY" ;
VAL_ 800 RefuelEvent 0 "NONE" 1 "PEND" 2 "TRUE" 3 "COMP" 4 "FAULT" ;
VAL_ 800 RefuelIndication 0 "NONE" 1 "WAIT" 2 "PARK" 3 "OK" 4 "DOOR" ;
VAL_ 280 StartRelayBCMCmd 0 "SNA" ;
VAL_ 993 DISPLACEMENT 255 "SNA" ;
VAL_ 993 ECM_Vehi_Type 0 "STANDARD" 1 "EVEHICLE" 3 "SNA" ;
VAL_ 993 ENG_ASP 0 "INTAKE_NORM" 1 "TURBO1" 2 "TURBO2" 3 "SUPER" 7 "SNA" ;
VAL_ 993 EngStyle 0 "CHOICE1" 1 "CHOICE2" 2 "CHOICE3" 3 "CHOICE4" 4 "CHOICE5" 5 "CHOICE6" 7 "SNA" ;
VAL_ 993 FUEL_TYPE 0 "UNLEADED" 1 "DIESEL" 2 "FLEX" 3 "CNG" 7 "SNA" ;
VAL_ 993 Manufacture 0 "ENG_DCA" 1 "ENG_DCS" 2 "ENG_MMC" 3 "ENG_HY" 7 "ENG_NP" ;
VAL_ 993 NUM_CYL 15 "SNA" ;
VAL_ 993 NUM_VALVE 7 "SNA" ;
VAL_ 770 AutoParkSts 0 "OFF" 1 "ON" 2 "GRADE" 3 "SNA" ;
VAL_ 770 EPBWarningLampReq 0 "OFF" 1 "CONT" 2 "BLINK" 3 "SNA" ;
VAL_ 770 EPB_Sw_Stat 0 "Not_Active" 1 "Active" 2 "S_FAULT" 3 "SNA" ;
VAL_ 770 FunctionLamp 0 "OFF" 1 "CONT" 2 "BLINK" 3 "SNA" ;
VAL_ 770 TextDisplay 0 "NONE" 1 "TxtMsg_1" 2 "TxtMsg_2" 3 "TxtMsg_3" 4 "TxtMsg_4" 5 "TxtMsg_5" 6 "TxtMsg_6" 7 "TxtMsg_7" 8 "TxtMsg_8" 9 "TxtMsg_9" 10 "TxtMsg_10" 11 "TxtMsg_11" 12 "TxtMsg_12" 13 "TxtMsg_13" 14 "TxtMsg_14" 15 "TxtMsg_15" 16 "TxtMsg_16" 17 "TxtMsg_17" 18 "TxtMsg_18" 19 "TxtMsg_19" 20 "TxtMsg_20" 21 "TxtMsg_21" 22 "TxtMsg_22" 23 "TxtMsg_23" 24 "TxtMsg_24" 25 "TxtMsg_25" 26 "TxtMsg_26" 27 "TxtMsg_27" 28 "TxtMsg_28" 29 "TxtMsg_29" 30 "TxtMsg_30" 31 "SNA" ;
VAL_ 669 EPBActivation 0 "NONE" 1 "STATIC_APPLY" 2 "STATIC_RELEASE" 3 "AUTO_APPLY_BTN" 4 "AUTO_APPLY_SHFT" 5 "AUTO_RELEASE_SHFT" 6 "DAR" 7 "SAFE_HOLD" 8 "TSA_APPLY" 9 "TSA_RELEASE" 10 "TSA_PERMANENT_APPLY" 11 "AHH_REQUEST" 12 "ACC_REQUEST" 13 "ESS_HSA_REQUEST" 14 "CDP" 15 "ESS_EPB_REQUEST" 16 "ADBF" 17 "ASSEMBLY_CHECK" 18 "DIAG_OPEN_BOTH" 19 "DIAG_CLOSE_BOTH" 20 "DIAG_OPEN_LEFT" 21 "DIAG_OPEN_RIGHT" 22 "DIAG_CLOSE_LEFT" 23 "DIAG_CLOSE_RIGHT" ;
VAL_ 669 EPBHoldSts 0 "REL" 1 "APPLIED" 2 "Applying" 3 "Releasing" 4 "DC" 5 "BSU" ;
VAL_ 544 EPSMotorTorqueExtRng 2047 "SNA" ;
VAL_ 544 EPSTemporaryDeactivationLDW 0 "False" 1 "True" ;
VAL_ 544 StrClmTrq 2047 "SNA" ;
VAL_ 544 StrClmTrqVD 0 "SNA" ;
